VERSION ""

NS_ :

BS_:

BU_:

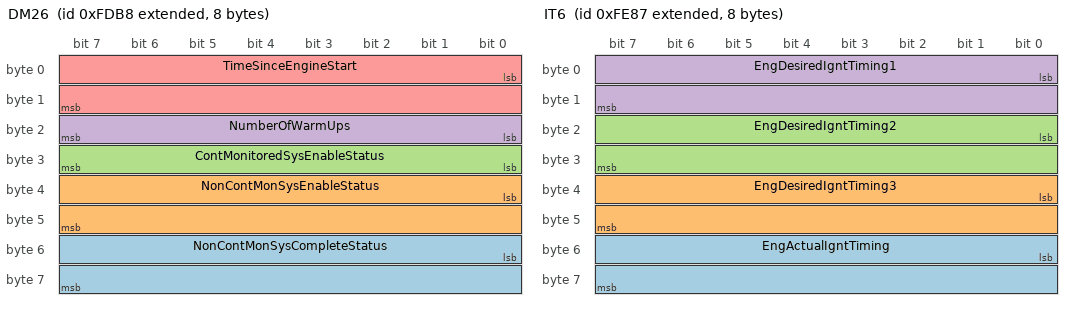
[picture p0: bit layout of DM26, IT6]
BO_ 2147548600 DM26: 8 Vector__XXX
 SG_ NonContMonSysCompleteStatus : 48|16@1+ (1,0) [0|65535] "" Vector__XXX
 SG_ NonContMonSysEnableStatus : 32|16@1+ (1,0) [0|65535] "" Vector__XXX
 SG_ ContMonitoredSysEnableStatus : 24|8@1+ (1,0) [0|255] "" Vector__XXX
 SG_ NumberOfWarmUps : 16|8@1+ (1,0) [0|255] "" Vector__XXX
 SG_ TimeSinceEngineStart : 0|16@1+ (1,0) [0|64255] "sec" Vector__XXX

BO_ 2147537920 DM18: 8 Vector__XXX
 SG_ SecurityEntityType : 16|4@1- (1,0) [0|15] "" Vector__XXX
 SG_ SecurityEntityLength : 0|12@1+ (1,0) [0|1785] "" Vector__XXX

BO_ 2147548855 LF: 10 Vector__XXX
 SG_ TotalEngCruiseTime : 48|32@1+ (0.05,0) [0|210554060.75] "hr" Vector__XXX
 SG_ TotalDriveAverageLoadFactor : 40|8@1+ (0.4,0) [0|100] "%" Vector__XXX
 SG_ TripDriveAverageLoadFactor : 32|8@1+ (0.4,0) [0|100] "%" Vector__XXX
 SG_ TripAverageEngSpeed : 16|16@1+ (0.125,0) [0|8031.875] "rpm" Vector__XXX
 SG_ TripMaxEngSpeed : 0|16@1+ (0.125,0) [0|8031.875] "rpm" Vector__XXX

BO_ 2147548736 LD: 8 Vector__XXX
 SG_ ImplementRearWorkLight : 62|2@1+ (1,0) [0|3] "" Vector__XXX
 SG_ ImplementLeftForwardWorkLight : 60|2@1+ (1,0) [0|3] "" Vector__XXX
 SG_ ImplementRightForwardWorkLight : 58|2@1+ (1,0) [0|3] "" Vector__XXX
 SG_ ImplementLeftFacingWorkLight : 54|2@1+ (1,0) [0|3] "" Vector__XXX
 SG_ ImplementRightFacingWorkLight : 52|2@1+ (1,0) [0|3] "" Vector__XXX
 SG_ ImplementOEMOption1Light : 50|2@1+ (1,0) [0|3] "" Vector__XXX
 SG_ ImplementOEMOption2Light : 48|2@1+ (1,0) [0|3] "" Vector__XXX
 SG_ TrctrFrontHighMountedWorkLights : 46|2@1+ (1,0) [0|3] "" Vector__XXX
 SG_ TrctorFrontLowMountedWorkLights : 44|2@1+ (1,0) [0|3] "" Vector__XXX
 SG_ TrctorSideHighMountedWorkLights : 42|2@1+ (1,0) [0|3] "" Vector__XXX
 SG_ TractorSideLowMountedWorkLights : 40|2@1+ (1,0) [0|3] "" Vector__XXX
 SG_ TrctorRearHighMountedWorkLights : 38|2@1+ (1,0) [0|3] "" Vector__XXX
 SG_ TractorRearLowMountedWorkLights : 36|2@1+ (1,0) [0|3] "" Vector__XXX
 SG_ TrctrUndersideMountedWorkLights : 34|2@1+ (1,0) [0|3] "" Vector__XXX
 SG_ RearFogLights : 32|2@1+ (1,0) [0|3] "" Vector__XXX
 SG_ TractorMarkerLight : 30|2@1+ (1,0) [0|3] "" Vector__XXX
 SG_ ImplementMarkerLight : 28|2@1+ (1,0) [0|3] "" Vector__XXX
 SG_ TractorClearanceLight : 26|2@1+ (1,0) [0|3] "" Vector__XXX
 SG_ ImplementClearanceLight : 24|2@1+ (1,0) [0|3] "" Vector__XXX
 SG_ LeftStopLight : 22|2@1+ (1,0) [0|3] "" Vector__XXX
 SG_ RightStopLight : 20|2@1+ (1,0) [0|3] "" Vector__XXX
 SG_ CenterStopLight : 18|2@1+ (1,0) [0|3] "" Vector__XXX
 SG_ BackUpLightAndAlarmHorn : 16|2@1+ (1,0) [0|3] "" Vector__XXX
 SG_ LeftTurnSignalLights : 14|2@1+ (1,0) [0|3] "" Vector__XXX
 SG_ RightTurnSignalLights : 12|2@1+ (1,0) [0|3] "" Vector__XXX
 SG_ RotatingBeaconLight : 10|2@1+ (1,0) [0|3] "" Vector__XXX
 SG_ TractorFrontFogLights : 8|2@1+ (1,0) [0|3] "" Vector__XXX
 SG_ HighBeamHeadLightData : 6|2@1+ (1,0) [0|3] "" Vector__XXX
 SG_ LowBeamHeadLightData : 4|2@1+ (1,0) [0|3] "" Vector__XXX
 SG_ AltBeamHeadLightData : 2|2@1+ (1,0) [0|3] "" Vector__XXX
 SG_ RunningLight : 0|2@1+ (1,0) [0|3] "" Vector__XXX

BO_ 2147548737 LC: 8 Vector__XXX
 SG_ ImplementRearWorkLightCmd : 62|2@1+ (1,0) [0|3] "" Vector__XXX
 SG_ ImplmentLeftForwardWorkLightCmd : 60|2@1+ (1,0) [0|3] "" Vector__XXX
 SG_ ImplmntRightForwardWorkLightCmd : 58|2@1+ (1,0) [0|3] "" Vector__XXX
 SG_ LightingDataRqCmd : 56|2@1+ (1,0) [0|3] "" Vector__XXX
 SG_ ImplementLeftFacingWorkLightCmd : 54|2@1+ (1,0) [0|3] "" Vector__XXX
 SG_ ImplmentRightFacingWorkLightCmd : 52|2@1+ (1,0) [0|3] "" Vector__XXX
 SG_ ImplementOEMOption1LightCmd : 50|2@1+ (1,0) [0|3] "" Vector__XXX
 SG_ ImplementOEMOption2LightCmd : 48|2@1+ (1,0) [0|3] "" Vector__XXX
 SG_ TrctrFrntHghMuntedWorkLightsCmd : 46|2@1+ (1,0) [0|3] "" Vector__XXX
 SG_ TrctrFrntLwMountedWorkLightsCmd : 44|2@1+ (1,0) [0|3] "" Vector__XXX
 SG_ TrctrSdHighMountedWorkLightsCmd : 42|2@1+ (1,0) [0|3] "" Vector__XXX
 SG_ TrctrSdeLowMountedWorkLightsCmd : 40|2@1+ (1,0) [0|3] "" Vector__XXX
 SG_ TrctrRrHighMountedWorkLightsCmd : 38|2@1+ (1,0) [0|3] "" Vector__XXX
 SG_ TrctrRarLowMountedWorkLightsCmd : 36|2@1+ (1,0) [0|3] "" Vector__XXX
 SG_ TrctrUndrsdMountedWorkLightsCmd : 34|2@1+ (1,0) [0|3] "" Vector__XXX
 SG_ RearFogLightCmd : 32|2@1+ (1,0) [0|3] "" Vector__XXX
 SG_ TractorMarkerLightCmd : 30|2@1+ (1,0) [0|3] "" Vector__XXX
 SG_ ImplementMarkerLightCmd : 28|2@1+ (1,0) [0|3] "" Vector__XXX
 SG_ TractorClearanceLightCmd : 26|2@1+ (1,0) [0|3] "" Vector__XXX
 SG_ ImplementClearanceLightCmd : 24|2@1+ (1,0) [0|3] "" Vector__XXX
 SG_ LeftStopLightCmd : 22|2@1+ (1,0) [0|3] "" Vector__XXX
 SG_ RightStopLightCmd : 20|2@1+ (1,0) [0|3] "" Vector__XXX
 SG_ CenterStopLightCmd : 18|2@1+ (1,0) [0|3] "" Vector__XXX
 SG_ BackUpLightAndAlarmHornCmd : 16|2@1+ (1,0) [0|3] "" Vector__XXX
 SG_ LeftTurnSignalLightsCmd : 14|2@1+ (1,0) [0|3] "" Vector__XXX
 SG_ RightTurnSignalLightsCmd : 12|2@1+ (1,0) [0|3] "" Vector__XXX
 SG_ RotatingBeaconLightCmd : 10|2@1+ (1,0) [0|3] "" Vector__XXX
 SG_ TractorFrontFogLightsCmd : 8|2@1+ (1,0) [0|3] "" Vector__XXX
 SG_ HighBeamHeadLightCmd : 6|2@1+ (1,0) [0|3] "" Vector__XXX
 SG_ LowBeamHeadLightCmd : 4|2@1+ (1,0) [0|3] "" Vector__XXX
 SG_ AltBeamHeadLightCmd : 2|2@1+ (1,0) [0|3] "" Vector__XXX
 SG_ RunningLightCmd : 0|2@1+ (1,0) [0|3] "" Vector__XXX

BO_ 2147548786 LBC: 8 Vector__XXX
 SG_ BladeCtrlMode : 16|8@1+ (1,0) [0|255] "" Vector__XXX
 SG_ BladeDurationAndDirection : 0|16@1+ (0.1,-3275.2) [-3275.2|3148.7] "sec" Vector__XXX

BO_ 2147548807 IT6: 8 Vector__XXX
 SG_ EngActualIgntTiming : 48|16@1+ (1,-200) [-200|301.99] "deg" Vector__XXX
 SG_ EngDesiredIgntTiming3 : 32|16@1+ (1,-200) [-200|301.99] "deg" Vector__XXX
 SG_ EngDesiredIgntTiming2 : 16|16@1+ (1,-200) [-200|301.99] "deg" Vector__XXX
 SG_ EngDesiredIgntTiming1 : 0|16@1+ (1,-200) [-200|301.99] "deg" Vector__XXX

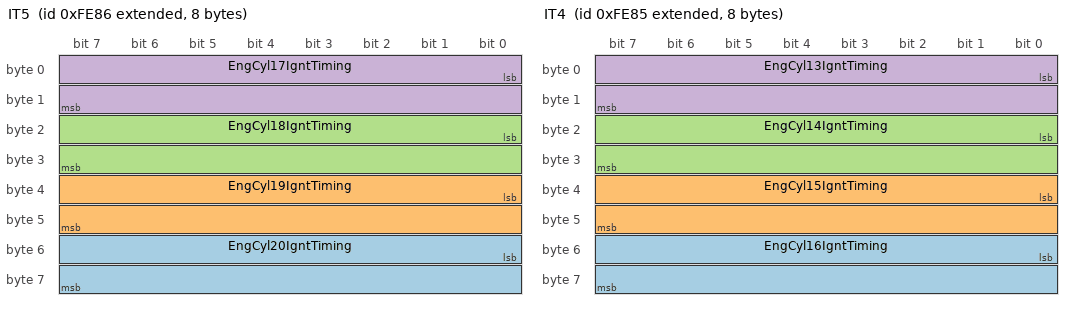
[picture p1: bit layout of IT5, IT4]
BO_ 2147548806 IT5: 8 Vector__XXX
 SG_ EngCyl20IgntTiming : 48|16@1+ (1,-200) [-200|301.99] "deg" Vector__XXX
 SG_ EngCyl19IgntTiming : 32|16@1+ (1,-200) [-200|301.99] "deg" Vector__XXX
 SG_ EngCyl18IgntTiming : 16|16@1+ (1,-200) [-200|301.99] "deg" Vector__XXX
 SG_ EngCyl17IgntTiming : 0|16@1+ (1,-200) [-200|301.99] "deg" Vector__XXX

BO_ 2147548805 IT4: 8 Vector__XXX
 SG_ EngCyl16IgntTiming : 48|16@1+ (1,-200) [-200|301.99] "deg" Vector__XXX
 SG_ EngCyl15IgntTiming : 32|16@1+ (1,-200) [-200|301.99] "deg" Vector__XXX
 SG_ EngCyl14IgntTiming : 16|16@1+ (1,-200) [-200|301.99] "deg" Vector__XXX
 SG_ EngCyl13IgntTiming : 0|16@1+ (1,-200) [-200|301.99] "deg" Vector__XXX

BO_ 2147548804 IT3: 8 Vector__XXX
 SG_ EngCyl12IgntTiming : 48|16@1+ (1,-200) [-200|301.99] "deg" Vector__XXX
 SG_ EngCyl11IgntTiming : 32|16@1+ (1,-200) [-200|301.99] "deg" Vector__XXX
 SG_ EngCyl10IgntTiming : 16|16@1+ (1,-200) [-200|301.99] "deg" Vector__XXX
 SG_ EngCyl9IgntTiming : 0|16@1+ (1,-200) [-200|301.99] "deg" Vector__XXX

BO_ 2147548803 IT2: 8 Vector__XXX
 SG_ EngCyl8IgntTiming : 48|16@1+ (1,-200) [-200|301.99] "deg" Vector__XXX
 SG_ EngCyl7IgntTiming : 32|16@1+ (1,-200) [-200|301.99] "deg" Vector__XXX
 SG_ EngCyl6IgntTiming : 16|16@1+ (1,-200) [-200|301.99] "deg" Vector__XXX
 SG_ EngCyl5IgntTiming : 0|16@1+ (1,-200) [-200|301.99] "deg" Vector__XXX

BO_ 2147548802 IT1: 8 Vector__XXX
 SG_ EngCyl4IgntTiming : 48|16@1+ (1,-200) [-200|301.99] "deg" Vector__XXX
 SG_ EngCyl3IgntTiming : 32|16@1+ (1,-200) [-200|301.99] "deg" Vector__XXX
 SG_ EngCyl2IgntTiming : 16|16@1+ (1,-200) [-200|301.99] "deg" Vector__XXX
 SG_ EngCyl1IgntTiming : 0|16@1+ (1,-200) [-200|301.99] "deg" Vector__XXX

BO_ 2147548810 ISO3: 8 Vector__XXX
 SG_ EngCyl20IgntTransSecondOutput : 24|8@1+ (1,-125) [-125|125] "%" Vector__XXX
 SG_ EngCyl19IgntTransSecondOutput : 16|8@1+ (1,-125) [-125|125] "%" Vector__XXX
 SG_ EngCyl18IgntTransSecondOutput : 8|8@1+ (1,-125) [-125|125] "%" Vector__XXX
 SG_ EngCyl17IgntTransSecondOutput : 0|8@1+ (1,-125) [-125|125] "%" Vector__XXX

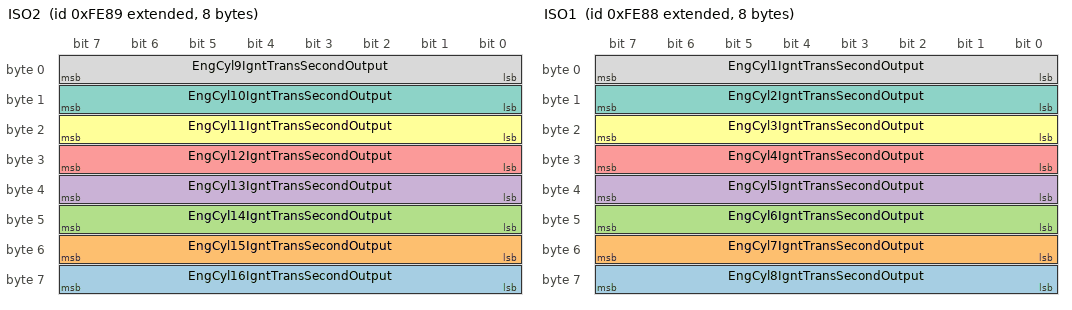
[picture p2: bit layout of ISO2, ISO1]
BO_ 2147548809 ISO2: 8 Vector__XXX
 SG_ EngCyl16IgntTransSecondOutput : 56|8@1+ (1,-125) [-125|125] "%" Vector__XXX
 SG_ EngCyl15IgntTransSecondOutput : 48|8@1+ (1,-125) [-125|125] "%" Vector__XXX
 SG_ EngCyl14IgntTransSecondOutput : 40|8@1+ (1,-125) [-125|125] "%" Vector__XXX
 SG_ EngCyl13IgntTransSecondOutput : 32|8@1+ (1,-125) [-125|125] "%" Vector__XXX
 SG_ EngCyl12IgntTransSecondOutput : 24|8@1+ (1,-125) [-125|125] "%" Vector__XXX
 SG_ EngCyl11IgntTransSecondOutput : 16|8@1+ (1,-125) [-125|125] "%" Vector__XXX
 SG_ EngCyl10IgntTransSecondOutput : 8|8@1+ (1,-125) [-125|125] "%" Vector__XXX
 SG_ EngCyl9IgntTransSecondOutput : 0|8@1+ (1,-125) [-125|125] "%" Vector__XXX

BO_ 2147548808 ISO1: 8 Vector__XXX
 SG_ EngCyl8IgntTransSecondOutput : 56|8@1+ (1,-125) [-125|125] "%" Vector__XXX
 SG_ EngCyl7IgntTransSecondOutput : 48|8@1+ (1,-125) [-125|125] "%" Vector__XXX
 SG_ EngCyl6IgntTransSecondOutput : 40|8@1+ (1,-125) [-125|125] "%" Vector__XXX
 SG_ EngCyl5IgntTransSecondOutput : 32|8@1+ (1,-125) [-125|125] "%" Vector__XXX
 SG_ EngCyl4IgntTransSecondOutput : 24|8@1+ (1,-125) [-125|125] "%" Vector__XXX
 SG_ EngCyl3IgntTransSecondOutput : 16|8@1+ (1,-125) [-125|125] "%" Vector__XXX
 SG_ EngCyl2IgntTransSecondOutput : 8|8@1+ (1,-125) [-125|125] "%" Vector__XXX
 SG_ EngCyl1IgntTransSecondOutput : 0|8@1+ (1,-125) [-125|125] "%" Vector__XXX

BO_ 2147548616 ISCS: 8 Vector__XXX
 SG_ EngOprtrPrmryIntrmdtSpdSlctStte : 0|4@1+ (1,0) [0|15] "" Vector__XXX

BO_ 2147548618 ISC: 8 Vector__XXX
 SG_ EngOprtrPrmryIntrmdtSpeedSelect : 0|4@1+ (1,0) [0|15] "" Vector__XXX

BO_ 2147548892 IO: 8 Vector__XXX
 SG_ EngTotalIdleHours : 32|32@1+ (0.05,0) [0|210554060.75] "hr" Vector__XXX
 SG_ EngTotalIdleFuelUsed : 0|32@1+ (0.5,0) [0|2105540607.5] "L" Vector__XXX

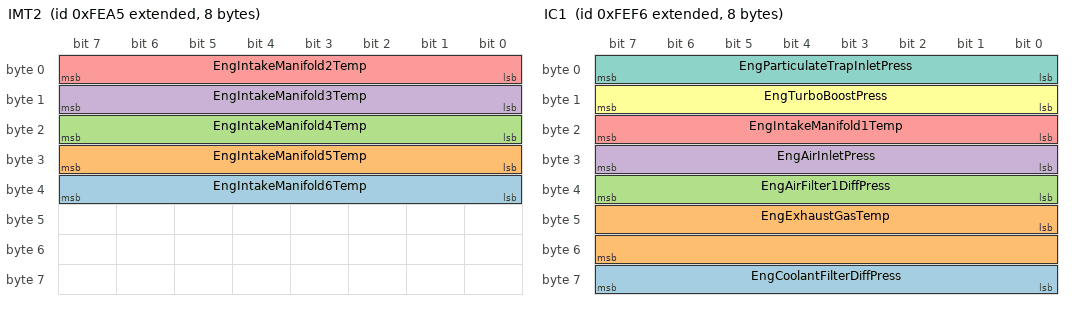
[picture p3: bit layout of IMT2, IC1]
BO_ 2147548837 IMT2: 8 Vector__XXX
 SG_ EngIntakeManifold6Temp : 32|8@1+ (1,-40) [-40|210] "deg" Vector__XXX
 SG_ EngIntakeManifold5Temp : 24|8@1+ (1,-40) [-40|210] "deg" Vector__XXX
 SG_ EngIntakeManifold4Temp : 16|8@1+ (1,-40) [-40|210] "deg" Vector__XXX
 SG_ EngIntakeManifold3Temp : 8|8@1+ (1,-40) [-40|210] "deg" Vector__XXX
 SG_ EngIntakeManifold2Temp : 0|8@1+ (1,-40) [-40|210] "deg" Vector__XXX

BO_ 2147548838 IMT1: 8 Vector__XXX
 SG_ EngTurbo4BoostPress : 48|16@1+ (0.125,0) [0|0] "+8031.875" Vector__XXX
 SG_ EngTurbo3BoostPress : 32|16@1+ (0.125,0) [0|0] "+8031.875" Vector__XXX
 SG_ EngTurbo2BoostPress : 16|16@1+ (0.125,0) [0|0] "+8031.875" Vector__XXX
 SG_ EngTurbo1BoostPress : 0|16@1+ (0.125,0) [0|0] "+8031.875" Vector__XXX

BO_ 2147548624 IC2: 8 Vector__XXX
 SG_ EngAirFilter4DiffPress : 16|8@1+ (0.05,0) [0|12.5] "kPa" Vector__XXX
 SG_ EngAirFilter3DiffPress : 8|8@1+ (0.05,0) [0|12.5] "kPa" Vector__XXX
 SG_ EngAirFilter2DiffPress : 0|8@1+ (0.05,0) [0|12.5] "kPa" Vector__XXX

BO_ 2147548918 IC1: 8 Vector__XXX
 SG_ EngCoolantFilterDiffPress : 56|8@1+ (0.5,0) [0|125] "kPa" Vector__XXX
 SG_ EngExhaustGasTemp : 40|16@1+ (0.03125,-273) [-273|1735] "deg" Vector__XXX
 SG_ EngAirFilter1DiffPress : 32|8@1+ (0.05,0) [0|12.5] "kPa" Vector__XXX
 SG_ EngAirInletPress : 24|8@1+ (2,0) [0|500] "kPa" Vector__XXX
 SG_ EngIntakeManifold1Temp : 16|8@1+ (1,-40) [-40|210] "deg" Vector__XXX
 SG_ EngTurboBoostPress : 8|8@1+ (2,0) [0|500] "kPa" Vector__XXX
 SG_ EngParticulateTrapInletPress : 0|8@1+ (0.5,0) [0|125] "kPa" Vector__XXX

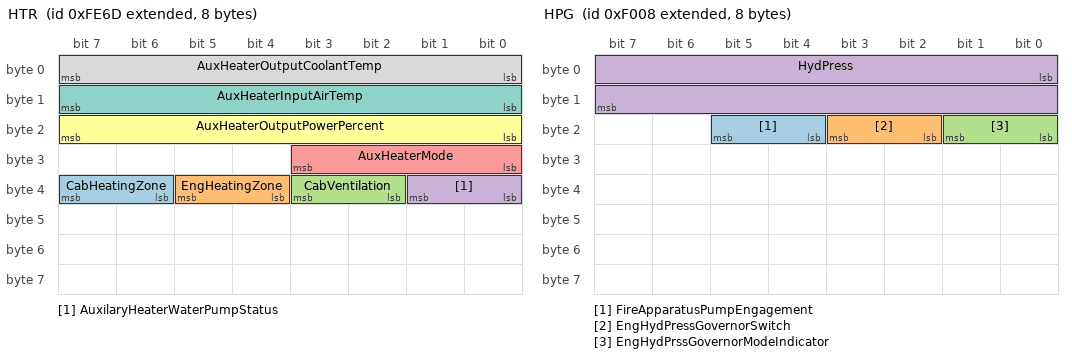
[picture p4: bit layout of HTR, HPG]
BO_ 2147548781 HTR: 8 Vector__XXX
 SG_ CabHeatingZone : 38|2@1+ (1,0) [0|3] "" Vector__XXX
 SG_ EngHeatingZone : 36|2@1+ (1,0) [0|3] "" Vector__XXX
 SG_ CabVentilation : 34|2@1+ (1,0) [0|3] "" Vector__XXX
 SG_ AuxilaryHeaterWaterPumpStatus : 32|2@1+ (1,0) [0|3] "" Vector__XXX
 SG_ AuxHeaterMode : 24|4@1+ (1,0) [0|15] "" Vector__XXX
 SG_ AuxHeaterOutputPowerPercent : 16|8@1+ (0.4,0) [0|100] "%" Vector__XXX
 SG_ AuxHeaterInputAirTemp : 8|8@1+ (1,-40) [-40|210] "deg" Vector__XXX
 SG_ AuxHeaterOutputCoolantTemp : 0|8@1+ (1,-40) [-40|210] "deg" Vector__XXX

BO_ 2147548782 HRW: 8 Vector__XXX
 SG_ RearAxleRightWheelSpeed : 48|16@1+ (1,0) [0|250.996] "km/h" Vector__XXX
 SG_ RearAxleLeftWheelSpeed : 32|16@1+ (1,0) [0|250.996] "km/h" Vector__XXX
 SG_ FrontAxleRightWheelSpeed : 16|16@1+ (1,0) [0|250.996] "km/h" Vector__XXX
 SG_ FrontAxleLeftWheelSpeed : 0|16@1+ (1,0) [0|250.996] "km/h" Vector__XXX

BO_ 2147545096 HPG: 8 Vector__XXX
 SG_ FireApparatusPumpEngagement : 20|2@1+ (1,0) [0|3] "" Vector__XXX
 SG_ EngHydPressGovernorSwitch : 18|2@1+ (1,0) [0|3] "" Vector__XXX
 SG_ EngHydPrssGovernorModeIndicator : 16|2@1+ (1,0) [0|3] "" Vector__XXX
 SG_ HydPress : 0|16@1+ (2,0) [0|128510] "kPa" Vector__XXX

BO_ 2147548901 HOURS: 8 Vector__XXX
 SG_ EngTotalRevolutions : 32|32@1+ (1000,0) [0|4.211081215E+012] "r" Vector__XXX
 SG_ EngTotalHoursOfOperation : 0|32@1+ (0.05,0) [0|210554060.75] "hr" Vector__XXX

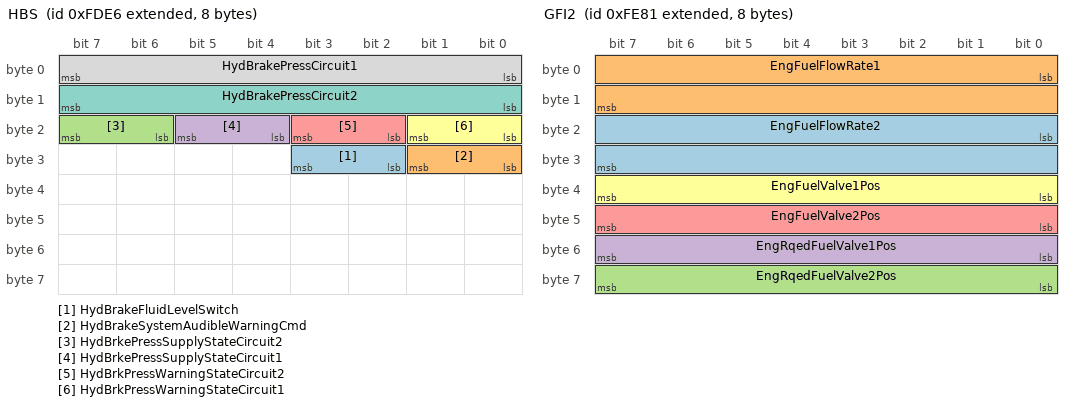
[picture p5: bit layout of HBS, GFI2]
BO_ 2147548646 HBS: 8 Vector__XXX
 SG_ HydBrakeFluidLevelSwitch : 26|2@1+ (1,0) [0|3] "" Vector__XXX
 SG_ HydBrakeSystemAudibleWarningCmd : 24|2@1+ (1,0) [0|3] "" Vector__XXX
 SG_ HydBrkePressSupplyStateCircuit2 : 22|2@1+ (1,0) [0|3] "" Vector__XXX
 SG_ HydBrkePressSupplyStateCircuit1 : 20|2@1+ (1,0) [0|3] "" Vector__XXX
 SG_ HydBrkPressWarningStateCircuit2 : 18|2@1+ (1,0) [0|3] "" Vector__XXX
 SG_ HydBrkPressWarningStateCircuit1 : 16|2@1+ (1,0) [0|3] "" Vector__XXX
 SG_ HydBrakePressCircuit2 : 8|8@1+ (100,0) [0|25] "MPa" Vector__XXX
 SG_ HydBrakePressCircuit1 : 0|8@1+ (100,0) [0|25] "MPa" Vector__XXX

BO_ 2147548856 GTFI: 22 Vector__XXX
 SG_ TripDriveFuelEconomy : 160|16@1+ (1,0) [0|125.5] "km/kg" Vector__XXX
 SG_ TripCruiseFuelUsed : 128|32@1+ (0.5,0) [0|2105540607.5] "kg" Vector__XXX
 SG_ TripVehicleIdleFuelUsed : 96|32@1+ (0.5,0) [0|2105540607.5] "kg" Vector__XXX
 SG_ TripPTONonmovingFuelUsed : 64|32@1+ (0.5,0) [0|2105540607.5] "kg" Vector__XXX
 SG_ TripPTOMovingFuelUsed : 32|32@1+ (0.5,0) [0|2105540607.5] "kg" Vector__XXX
 SG_ TripDriveFuelUsed : 0|32@1+ (0.5,0) [0|2105540607.5] "kg" Vector__XXX

BO_ 2147548811 GFP: 8 Vector__XXX
 SG_ EngAirToFuelDiffPress : 32|16@1+ (0.1,0) [0|6425.5] "kPa" Vector__XXX
 SG_ EngFuelValveDiffPress : 16|16@1+ (0.1,0) [0|6425.5] "kPa" Vector__XXX
 SG_ EngFuelValveInletAbsPress : 0|16@1+ (0.1,0) [0|6425.5] "kPa" Vector__XXX

BO_ 2147548801 GFI2: 8 Vector__XXX
 SG_ EngFuelFlowRate2 : 16|16@1+ (0.1,0) [0|6425.5] "m^3/h" Vector__XXX
 SG_ EngFuelFlowRate1 : 0|16@1+ (0.1,0) [0|6425.5] "m^3/h" Vector__XXX
 SG_ EngRqedFuelValve2Pos : 56|8@1+ (0.4,0) [0|100] "%" Vector__XXX
 SG_ EngRqedFuelValve1Pos : 48|8@1+ (0.4,0) [0|100] "%" Vector__XXX
 SG_ EngFuelValve2Pos : 40|8@1+ (0.4,0) [0|100] "%" Vector__XXX
 SG_ EngFuelValve1Pos : 32|8@1+ (0.4,0) [0|100] "%" Vector__XXX

BO_ 2147548850 GFI1: 8 Vector__XXX
 SG_ EngFuelSpecificGravity : 48|16@1+ (0.0001,0) [0|6.4255] "" Vector__XXX
 SG_ TripAverageFuelRate : 32|16@1+ (0.05,0) [0|3212.75] "kg/h" Vector__XXX
 SG_ TotalEngPTOFuelUsed : 0|32@1+ (0.5,0) [0|2105540607.5] "kg" Vector__XXX

BO_ 2147548757 GFD: 8 Vector__XXX
 SG_ SpecificHeatRatio : 0|16@1+ (0.001,0) [0|64.255] "" Vector__XXX

BO_ 2147548847 GFC: 8 Vector__XXX
 SG_ TotalFuelUsed : 32|32@1+ (0.5,0) [0|2105540607.5] "kg" Vector__XXX
 SG_ TripFuel : 0|32@1+ (0.5,0) [0|2105540607.5] "kg" Vector__XXX

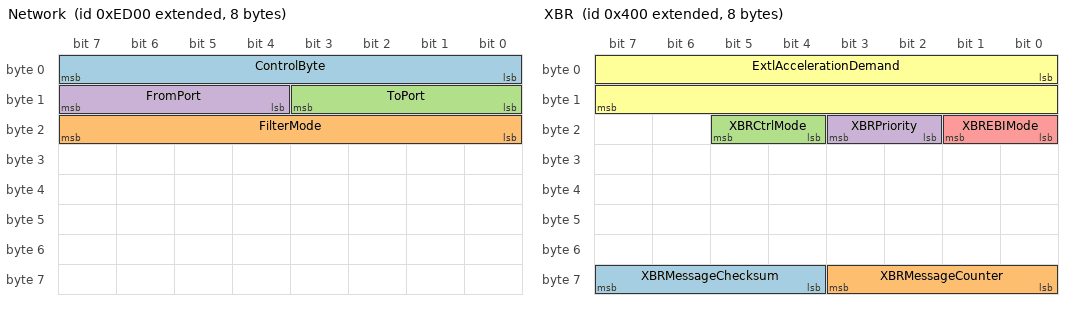
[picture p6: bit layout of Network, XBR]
BO_ 2147544320 Network: 8 Vector__XXX
 SG_ ControlByte : 0|8@1+ (1,0) [0|255] "" Vector__XXX
 SG_ FilterMode : 16|8@1+ (1,0) [0|255] "" Vector__XXX
 SG_ ToPort : 8|4@1+ (1,0) [0|15] "" Vector__XXX
 SG_ FromPort : 12|4@1+ (1,0) [0|15] "" Vector__XXX

BO_ 2147484672 XBR: 8 Vector__XXX
 SG_ XBRMessageChecksum : 60|4@1+ (1,0) [0|15] "" Vector__XXX
 SG_ XBRMessageCounter : 56|4@1+ (1,0) [0|15] "" Vector__XXX
 SG_ XBRCtrlMode : 20|2@1+ (1,0) [0|3] "" Vector__XXX
 SG_ XBRPriority : 18|2@1+ (1,0) [0|3] "" Vector__XXX
 SG_ XBREBIMode : 16|2@1+ (1,0) [0|3] "" Vector__XXX
 SG_ ExtlAccelerationDemand : 0|16@1+ (1,-14.313) [-14.313|0] "+15.687" Vector__XXX

BO_ 2147548927 WFI: 8 Vector__XXX
 SG_ WaterInFuelIndicator : 0|2@1+ (1,0) [0|3] "" Vector__XXX

BO_ 2147548906 VW: 8 Vector__XXX
 SG_ CargoWeight : 40|16@1+ (2,0) [0|128510] "kg" Vector__XXX
 SG_ TrailerWeight : 24|16@1+ (2,0) [0|128510] "kg" Vector__XXX
 SG_ AxleWeight : 8|16@1+ (0.5,0) [0|32127.5] "kg" Vector__XXX
 SG_ AxleLocation : 0|8@1+ (1,0) [0|255] "" Vector__XXX

BO_ 2147548754 VP3: 8 Vector__XXX
 SG_ NetBatteryCurrentHiRes : 16|16@1+ (0.05,-1600) [-1600|1676.75] "A" Vector__XXX
 SG_ AltCurrentHiRes : 0|16@1+ (0.05,-1600) [-1600|1676.75] "A" Vector__XXX

BO_ 2147548813 VP2: 8 Vector__XXX
 SG_ Battery2Potential : 0|16@1+ (0.05,0) [0|3212.75] "V" Vector__XXX

BO_ 2147548915 VP: 8 Vector__XXX
 SG_ Longitude : 32|32@1+ (10,-210) [-210|211.1008122] "deg" Vector__XXX
 SG_ Latitude : 0|32@1+ (10,-210) [-210|211.1008122] "deg" Vector__XXX

BO_ 2147548908 VI: 8 Vector__XXX

BO_ 2147548903 VH: 8 Vector__XXX
 SG_ TotalPowerTakeoffHours : 32|32@1+ (0.05,0) [0|210554060.75] "hr" Vector__XXX
 SG_ TotalVehicleHours : 0|32@1+ (0.05,0) [0|210554060.75] "hr" Vector__XXX

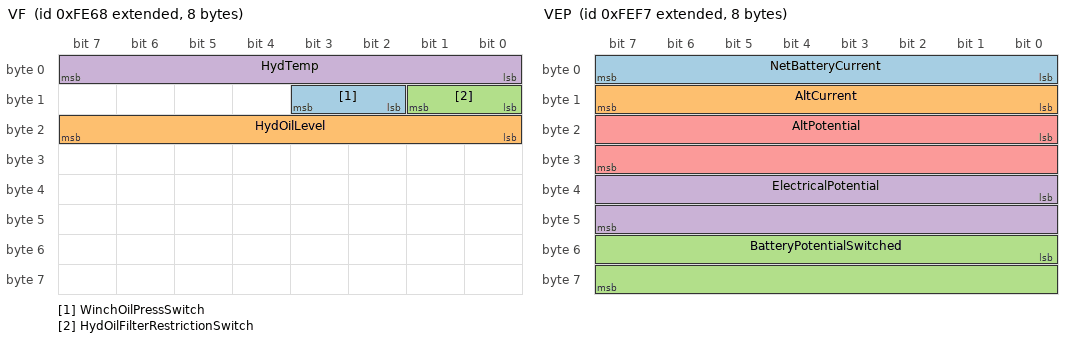
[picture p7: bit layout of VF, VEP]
BO_ 2147548776 VF: 8 Vector__XXX
 SG_ WinchOilPressSwitch : 10|2@1+ (1,0) [0|3] "" Vector__XXX
 SG_ HydOilLevel : 16|8@1+ (0.4,0) [0|100] "%" Vector__XXX
 SG_ HydOilFilterRestrictionSwitch : 8|2@1+ (1,0) [0|3] "" Vector__XXX
 SG_ HydTemp : 0|8@1+ (1,-40) [-40|210] "deg" Vector__XXX

BO_ 2147548919 VEP: 8 Vector__XXX
 SG_ NetBatteryCurrent : 0|8@1+ (1,-125) [-125|125] "A" Vector__XXX
 SG_ AltCurrent : 8|8@1+ (1,0) [0|250] "A" Vector__XXX
 SG_ BatteryPotentialSwitched : 48|16@1+ (0.05,0) [0|3212.75] "V" Vector__XXX
 SG_ ElectricalPotential : 32|16@1+ (0.05,0) [0|3212.75] "V" Vector__XXX
 SG_ AltPotential : 16|16@1+ (0.05,0) [0|3212.75] "V" Vector__XXX

BO_ 2147548904 VDS: 8 Vector__XXX
 SG_ Altitude : 48|16@1+ (0.125,-2500) [-2500|5531.875] "m" Vector__XXX
 SG_ Pitch : 32|16@1+ (1,-200) [-200|301.99] "deg" Vector__XXX
 SG_ NavigationBasedVehicleSpeed : 16|16@1+ (1,0) [0|250.996] "km/h" Vector__XXX
 SG_ CompassBearing : 0|16@1+ (1,0) [0|501.99] "deg" Vector__XXX

BO_ 2147548865 VDHR: 8 Vector__XXX
 SG_ HighResolutionTripDistance : 32|32@1+ (5,0) [0|21055406] "km" Vector__XXX
 SG_ HghRslutionTotalVehicleDistance : 0|32@1+ (5,0) [0|21055406] "km" Vector__XXX

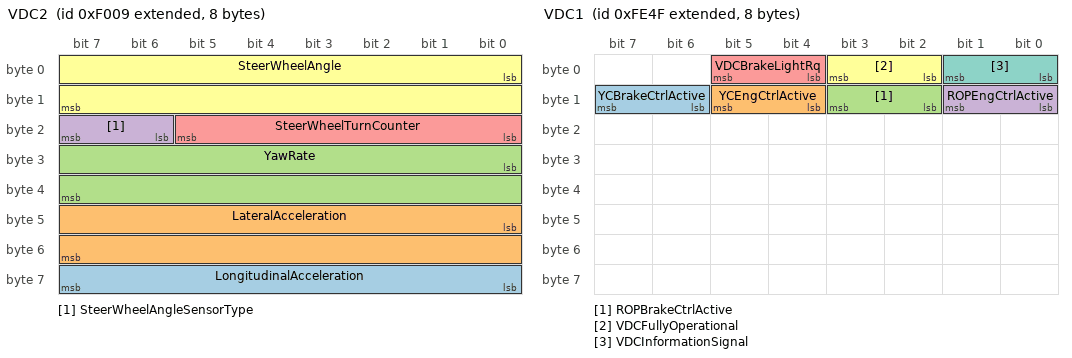
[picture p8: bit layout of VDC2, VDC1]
BO_ 2147545097 VDC2: 8 Vector__XXX
 SG_ LongitudinalAcceleration : 56|8@1+ (0.1,-11.5) [-11.5|0] "+12.5" Vector__XXX
 SG_ LateralAcceleration : 40|16@1+ (1,-14.313) [-14.313|0] "+15.687" Vector__XXX
 SG_ YawRate : 24|16@1+ (1,-2.08) [-2.08|0] "+3.92" Vector__XXX
 SG_ SteerWheelAngleSensorType : 22|2@1+ (1,0) [0|3] "" Vector__XXX
 SG_ SteerWheelTurnCounter : 16|6@1+ (1,-32) [-32|29] "turns" Vector__XXX
 SG_ SteerWheelAngle : 0|16@1+ (1,-30.626) [-30.626|0] "+31.374" Vector__XXX

BO_ 2147548751 VDC1: 8 Vector__XXX
 SG_ YCBrakeCtrlActive : 14|2@1+ (1,0) [0|3] "" Vector__XXX
 SG_ YCEngCtrlActive : 12|2@1+ (1,0) [0|3] "" Vector__XXX
 SG_ ROPBrakeCtrlActive : 10|2@1+ (1,0) [0|3] "" Vector__XXX
 SG_ ROPEngCtrlActive : 8|2@1+ (1,0) [0|3] "" Vector__XXX
 SG_ VDCBrakeLightRq : 4|2@1+ (1,0) [0|3] "" Vector__XXX
 SG_ VDCFullyOperational : 2|2@1+ (1,0) [0|3] "" Vector__XXX
 SG_ VDCInformationSignal : 0|2@1+ (1,0) [0|3] "" Vector__XXX

BO_ 2147548896 VD: 8 Vector__XXX
 SG_ TotalVehicleDistance : 32|32@1+ (0.125,0) [0|526385151.9] "km" Vector__XXX
 SG_ TripDistance : 0|32@1+ (0.125,0) [0|526385151.9] "km" Vector__XXX

BO_ 2147548854 TVI: 8 Vector__XXX
 SG_ TripCruiseDistance : 16|32@1+ (0.125,0) [0|526385151.9] "km" Vector__XXX
 SG_ TripMaxVehicleSpeed : 0|16@1+ (1,0) [0|250.996] "km/h" Vector__XXX

BO_ 2147548848 TTI2: 20 Vector__XXX
 SG_ TripAirCompressorOnTime : 128|32@1+ (0.05,0) [0|210554060.75] "hr" Vector__XXX
 SG_ TripIdleTime : 96|32@1+ (0.05,0) [0|210554060.75] "hr" Vector__XXX
 SG_ TripEngRunningTime : 64|32@1+ (0.05,0) [0|210554060.75] "hr" Vector__XXX
 SG_ TripPTOTime : 32|32@1+ (0.05,0) [0|210554060.75] "hr" Vector__XXX
 SG_ TripCruiseTime : 0|32@1+ (0.05,0) [0|210554060.75] "hr" Vector__XXX

BO_ 2147548852 TTI1: 16 Vector__XXX
 SG_ TripTimeInDerateByEng : 96|32@1+ (0.05,0) [0|210554060.75] "hr" Vector__XXX
 SG_ TripTimeInGearDown : 64|32@1+ (0.05,0) [0|210554060.75] "hr" Vector__XXX
 SG_ TripTimeInTopGear : 32|32@1+ (0.05,0) [0|210554060.75] "hr" Vector__XXX
 SG_ TripTimeInVSL : 0|32@1+ (0.05,0) [0|210554060.75] "hr" Vector__XXX

BO_ 2147548853 TSI: 8 Vector__XXX
 SG_ TripSuddenDecelerations : 48|16@1+ (1,0) [0|64255] "counts" Vector__XXX
 SG_ TrpNmberOfIdleShutdownOverrides : 32|16@1+ (1,0) [0|64255] "counts" Vector__XXX
 SG_ TripNumberOfIdleShutdowns : 16|16@1+ (1,0) [0|64255] "counts" Vector__XXX
 SG_ TripNumberOfHotShutdowns : 0|16@1+ (1,0) [0|64255] "counts" Vector__XXX

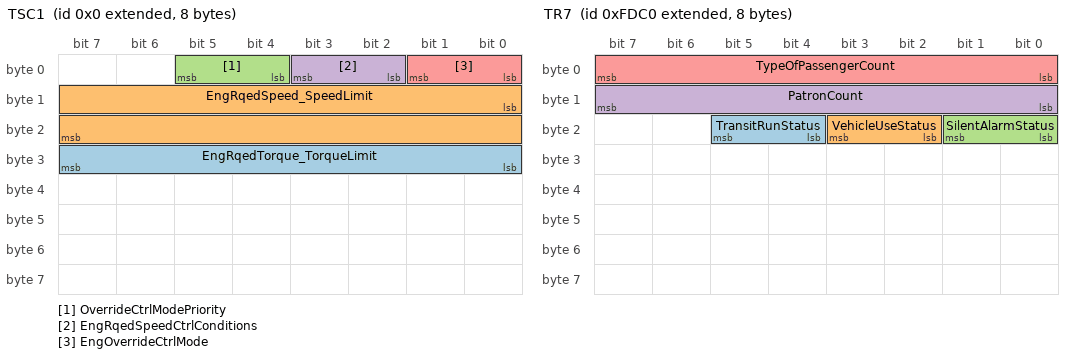
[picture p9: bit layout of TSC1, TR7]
BO_ 2147483648 TSC1: 8 Vector__XXX
 SG_ EngRqedTorque_TorqueLimit : 24|8@1+ (1,-125) [-125|125] "%" Vector__XXX
 SG_ EngRqedSpeed_SpeedLimit : 8|16@1+ (0.125,0) [0|8031.875] "rpm" Vector__XXX
 SG_ OverrideCtrlModePriority : 4|2@1+ (1,0) [0|3] "" Vector__XXX
 SG_ EngRqedSpeedCtrlConditions : 2|2@1+ (1,0) [0|3] "" Vector__XXX
 SG_ EngOverrideCtrlMode : 0|2@1+ (1,0) [0|3] "" Vector__XXX

BO_ 2147548608 TR7: 8 Vector__XXX
 SG_ TransitRunStatus : 20|2@1+ (1,0) [0|3] "" Vector__XXX
 SG_ VehicleUseStatus : 18|2@1+ (1,0) [0|3] "" Vector__XXX
 SG_ SilentAlarmStatus : 16|2@1+ (1,0) [0|3] "" Vector__XXX
 SG_ PatronCount : 8|8@1+ (1,0) [0|250] "" Vector__XXX
 SG_ TypeOfPassengerCount : 0|8@1+ (1,0) [0|255] "" Vector__XXX

BO_ 2147548602 TR6: 8 Vector__XXX
 SG_ FareboxAlarmIdentifier : 8|7@1+ (1,0) [0|127] "" Vector__XXX
 SG_ FareboxEmergencyStatus : 0|2@1+ (1,0) [0|3] "" Vector__XXX

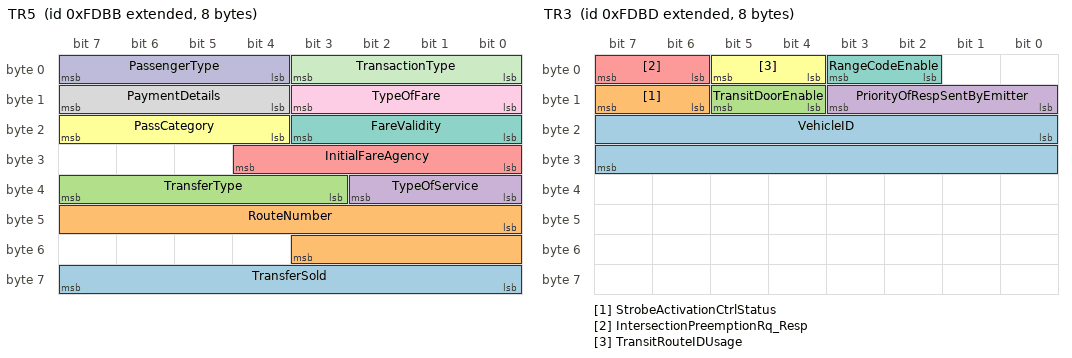
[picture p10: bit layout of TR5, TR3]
BO_ 2147548603 TR5: 8 Vector__XXX
 SG_ TransferSold : 56|8@1+ (1,0) [0|255] "" Vector__XXX
 SG_ RouteNumber : 40|12@1+ (1,0) [0|4095] "" Vector__XXX
 SG_ TransferType : 35|5@1+ (1,0) [0|31] "" Vector__XXX
 SG_ TypeOfService : 32|3@1+ (1,0) [0|7] "" Vector__XXX
 SG_ InitialFareAgency : 24|5@1+ (1,0) [0|31] "" Vector__XXX
 SG_ PassCategory : 20|4@1+ (1,0) [0|15] "" Vector__XXX
 SG_ FareValidity : 16|4@1+ (1,0) [0|15] "" Vector__XXX
 SG_ PaymentDetails : 12|4@1+ (1,0) [0|15] "" Vector__XXX
 SG_ TypeOfFare : 8|4@1+ (1,0) [0|15] "" Vector__XXX
 SG_ PassengerType : 4|4@1+ (1,0) [0|15] "" Vector__XXX
 SG_ TransactionType : 0|4@1+ (1,0) [0|15] "" Vector__XXX

BO_ 2147548604 TR4: 15 Vector__XXX
 SG_ DriversFareboxSecurityCode : 104|16@1+ (1,0) [0|65535] "counts" Vector__XXX
 SG_ AssignedBlock : 88|16@1+ (1,0) [0|65535] "counts" Vector__XXX
 SG_ AssignedRun : 72|16@1+ (1,0) [0|65535] "counts" Vector__XXX
 SG_ AssignedRoute : 56|16@1+ (1,0) [0|65535] "counts" Vector__XXX
 SG_ PatternNumber : 40|16@1+ (1,0) [0|65535] "counts" Vector__XXX
 SG_ TripNumber : 24|16@1+ (1,0) [0|65535] "counts" Vector__XXX
 SG_ FarePresets : 16|8@1+ (1,0) [0|255] "" Vector__XXX
 SG_ TripDirection : 8|4@1+ (1,0) [0|15] "" Vector__XXX
 SG_ TripStatus : 2|3@1+ (1,0) [0|7] "" Vector__XXX
 SG_ FareboxServiceStatus : 0|2@1+ (1,0) [0|3] "" Vector__XXX

BO_ 2147548605 TR3: 8 Vector__XXX
 SG_ VehicleID : 16|16@1+ (1,0) [0|65535] "counts" Vector__XXX
 SG_ StrobeActivationCtrlStatus : 14|2@1+ (1,0) [0|3] "" Vector__XXX
 SG_ TransitDoorEnable : 12|2@1+ (1,0) [0|3] "" Vector__XXX
 SG_ PriorityOfRespSentByEmitter : 8|4@1+ (1,0) [0|15] "" Vector__XXX
 SG_ IntersectionPreemptionRq_Resp : 6|2@1+ (1,0) [0|3] "" Vector__XXX
 SG_ TransitRouteIDUsage : 4|2@1+ (1,0) [0|3] "" Vector__XXX
 SG_ RangeCodeEnable : 2|2@1+ (1,0) [0|3] "" Vector__XXX

BO_ 2147548607 TR2: 8 Vector__XXX
 SG_ NmbrOfBytsInMlpstIdentification : 0|8@1+ (1,0) [0|250] "" Vector__XXX

BO_ 2147548606 TR1: 8 Vector__XXX
 SG_ Agency : 0|8@1+ (1,0) [0|255] "" Vector__XXX
 SG_ NmbrOfBytsInTrnstAssgndBlckIdntt : 24|8@1+ (1,0) [0|250] "" Vector__XXX
 SG_ NmbrOfBytsInTrnstAssgndRnIdntty : 16|8@1+ (1,0) [0|250] "" Vector__XXX
 SG_ NmbrOfBytsInTrnstAssgndRtIdntty : 8|8@1+ (1,0) [0|250] "" Vector__XXX

BO_ 2147528192 TPRS: 8 Vector__XXX
 SG_ ReferenceTirePressSetting : 8|8@1+ (8,0) [0|2000] "kPa" Vector__XXX
 SG_ TireLocation : 0|8@1+ (1,0) [0|255] "" Vector__XXX

BO_ 2147548601 TPRI: 8 Vector__XXX
 SG_ ReferenceTirePress : 8|8@1+ (8,0) [0|2000] "kPa" Vector__XXX
 SG_ TireLocation : 0|8@1+ (1,0) [0|255] "" Vector__XXX

BO_ 2147548794 TP3: 8 Vector__XXX
 SG_ SteerChannelTirePress : 32|16@1+ (0.5,0) [0|32127.5] "kPa" Vector__XXX
 SG_ DriveChannelTirePress : 16|16@1+ (0.5,0) [0|32127.5] "kPa" Vector__XXX
 SG_ TrailerTagPushChannelTirePress : 0|16@1+ (0.5,0) [0|32127.5] "kPa" Vector__XXX

BO_ 2147548793 TP2: 8 Vector__XXX
 SG_ SteerChannelTirePressTarget : 32|16@1+ (0.5,0) [0|32127.5] "kPa" Vector__XXX
 SG_ DriveChannelTirePressTarget : 16|16@1+ (0.5,0) [0|32127.5] "kPa" Vector__XXX
 SG_ TrlrTgPshChannelTirePressTarget : 0|16@1+ (0.5,0) [0|32127.5] "kPa" Vector__XXX

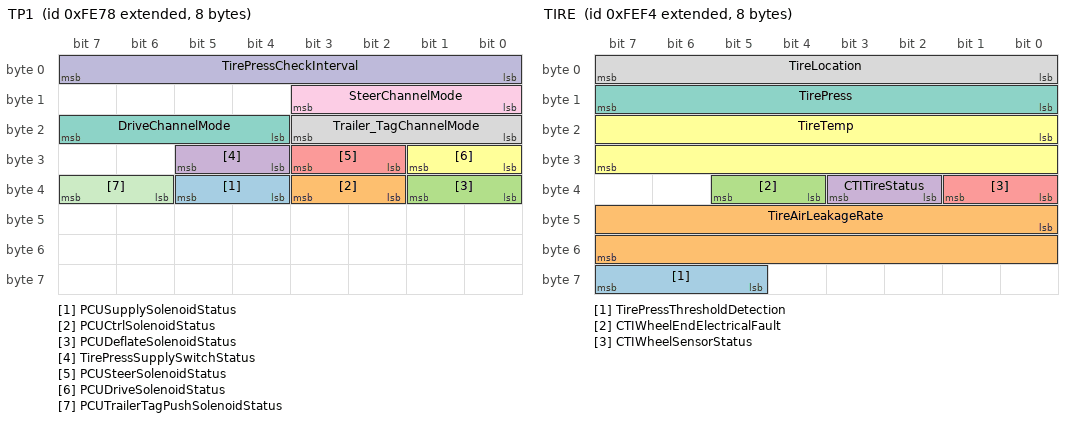
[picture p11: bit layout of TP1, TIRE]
BO_ 2147548792 TP1: 8 Vector__XXX
 SG_ PCUSupplySolenoidStatus : 36|2@1+ (1,0) [0|3] "" Vector__XXX
 SG_ PCUCtrlSolenoidStatus : 34|2@1+ (1,0) [0|3] "" Vector__XXX
 SG_ PCUDeflateSolenoidStatus : 32|2@1+ (1,0) [0|3] "" Vector__XXX
 SG_ TirePressSupplySwitchStatus : 28|2@1+ (1,0) [0|3] "" Vector__XXX
 SG_ PCUSteerSolenoidStatus : 26|2@1+ (1,0) [0|3] "" Vector__XXX
 SG_ PCUDriveSolenoidStatus : 24|2@1+ (1,0) [0|3] "" Vector__XXX
 SG_ DriveChannelMode : 20|4@1+ (1,0) [0|15] "" Vector__XXX
 SG_ Trailer_TagChannelMode : 16|4@1+ (1,0) [0|15] "" Vector__XXX
 SG_ SteerChannelMode : 8|4@1+ (1,0) [0|15] "" Vector__XXX
 SG_ TirePressCheckInterval : 0|8@1+ (1,0) [0|250] "mins" Vector__XXX
 SG_ PCUTrailerTagPushSolenoidStatus : 38|2@1+ (1,0) [0|3] "" Vector__XXX

BO_ 2147548916 TIRE: 8 Vector__XXX
 SG_ TirePressThresholdDetection : 61|3@1+ (1,0) [0|7] "" Vector__XXX
 SG_ TireAirLeakageRate : 40|16@1+ (0.1,0) [0|0] "/s" Vector__XXX
 SG_ CTIWheelEndElectricalFault : 36|2@1+ (1,0) [0|3] "" Vector__XXX
 SG_ CTITireStatus : 34|2@1+ (1,0) [0|3] "" Vector__XXX
 SG_ CTIWheelSensorStatus : 32|2@1+ (1,0) [0|3] "" Vector__XXX
 SG_ TireTemp : 16|16@1+ (0.03125,-273) [-273|1735] "deg" Vector__XXX
 SG_ TirePress : 8|8@1+ (4,0) [0|1000] "kPa" Vector__XXX
 SG_ TireLocation : 0|8@1+ (1,0) [0|255] "" Vector__XXX

BO_ 2147548758 TI1: 8 Vector__XXX
 SG_ CatalystTankTemp : 8|8@1+ (1,-40) [-40|210] "deg" Vector__XXX
 SG_ CatalystTankLevel : 0|8@1+ (0.4,0) [0|100] "%" Vector__XXX

BO_ 2147548859 TFI: 16 Vector__XXX
 SG_ TripFanOnTimeDueToAManualSwitch : 64|32@1+ (0.05,0) [0|210554060.75] "hr" Vector__XXX
 SG_ TripFanOnTime : 0|32@1+ (0.05,0) [0|210554060.75] "hr" Vector__XXX
 SG_ TripFanOnTimeDueToA_CSystem : 96|32@1+ (0.05,0) [0|210554060.75] "hr" Vector__XXX
 SG_ TripFanOnTimeDueToEngSystem : 32|32@1+ (0.05,0) [0|210554060.75] "hr" Vector__XXX

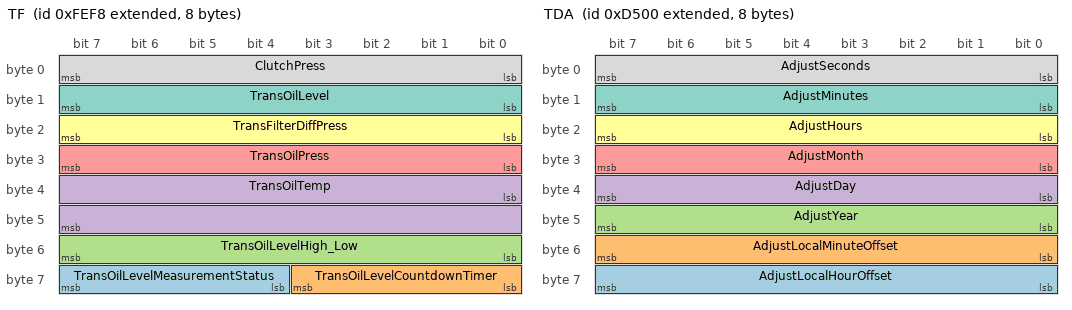
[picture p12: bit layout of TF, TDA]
BO_ 2147548920 TF: 8 Vector__XXX
 SG_ TransOilLevelMeasurementStatus : 60|4@1+ (1,0) [0|15] "" Vector__XXX
 SG_ TransOilLevelCountdownTimer : 56|4@1+ (1,0) [0|15] "" Vector__XXX
 SG_ TransOilLevelHigh_Low : 48|8@1+ (0.5,-61.5) [-61.5|62.5] "L" Vector__XXX
 SG_ TransOilTemp : 32|16@1+ (0.03125,-273) [-273|1735] "deg" Vector__XXX
 SG_ TransOilPress : 24|8@1+ (16,0) [0|4000] "kPa" Vector__XXX
 SG_ TransFilterDiffPress : 16|8@1+ (2,0) [0|500] "kPa" Vector__XXX
 SG_ TransOilLevel : 8|8@1+ (0.4,0) [0|100] "%" Vector__XXX
 SG_ ClutchPress : 0|8@1+ (16,0) [0|4000] "kPa" Vector__XXX

BO_ 2147548858 TDI: 12 Vector__XXX
 SG_ TripDistanceInTopGear : 64|32@1+ (0.125,0) [0|526385151.9] "km" Vector__XXX
 SG_ TripGearDownDistance : 32|32@1+ (0.125,0) [0|526385151.9] "km" Vector__XXX
 SG_ TripDistanceOnVSL : 0|32@1+ (0.125,0) [0|526385151.9] "km" Vector__XXX

BO_ 2147538176 TDA: 8 Vector__XXX
 SG_ AdjustLocalHourOffset : 56|8@1+ (1,-125) [-125|125] "hr" Vector__XXX
 SG_ AdjustLocalMinuteOffset : 48|8@1+ (1,-125) [-125|125] "mins" Vector__XXX
 SG_ AdjustYear : 40|8@1+ (1,1985) [1985|2235] "years" Vector__XXX
 SG_ AdjustDay : 32|8@1+ (0.25,0) [0|62.5] "days" Vector__XXX
 SG_ AdjustMonth : 24|8@1+ (1,0) [0|250] "months" Vector__XXX
 SG_ AdjustHours : 16|8@1+ (1,0) [0|250] "hr" Vector__XXX
 SG_ AdjustMinutes : 8|8@1+ (1,0) [0|250] "mins" Vector__XXX
 SG_ AdjustSeconds : 0|8@1+ (0.25,0) [0|62.5] "s" Vector__XXX

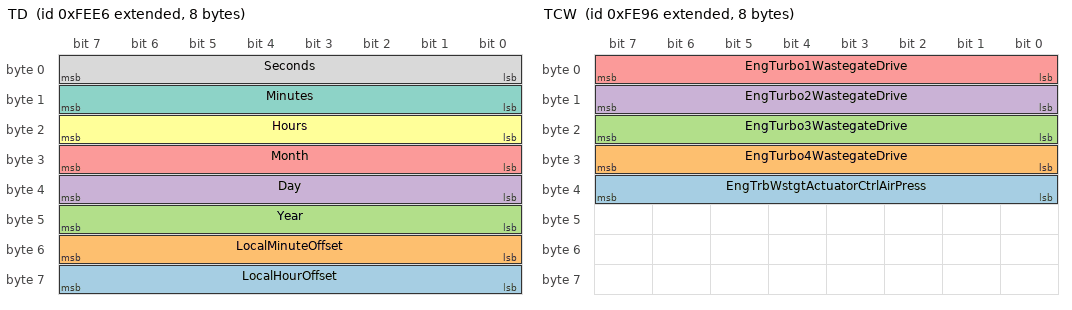
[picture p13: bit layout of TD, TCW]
BO_ 2147548902 TD: 8 Vector__XXX
 SG_ LocalHourOffset : 56|8@1+ (1,-125) [-125|125] "hr" Vector__XXX
 SG_ LocalMinuteOffset : 48|8@1+ (1,-125) [-125|125] "mins" Vector__XXX
 SG_ Year : 40|8@1+ (1,1985) [1985|2235] "years" Vector__XXX
 SG_ Day : 32|8@1+ (0.25,0) [0|62.5] "days" Vector__XXX
 SG_ Month : 24|8@1+ (1,0) [0|250] "months" Vector__XXX
 SG_ Hours : 16|8@1+ (1,0) [0|250] "hr" Vector__XXX
 SG_ Minutes : 8|8@1+ (1,0) [0|250] "mins" Vector__XXX
 SG_ Seconds : 0|8@1+ (0.25,0) [0|62.5] "s" Vector__XXX

BO_ 2147548822 TCW: 8 Vector__XXX
 SG_ EngTrbWstgtActuatorCtrlAirPress : 32|8@1+ (4,0) [0|1000] "kPa" Vector__XXX
 SG_ EngTurbo4WastegateDrive : 24|8@1+ (0.4,0) [0|100] "%" Vector__XXX
 SG_ EngTurbo3WastegateDrive : 16|8@1+ (0.4,0) [0|100] "%" Vector__XXX
 SG_ EngTurbo2WastegateDrive : 8|8@1+ (0.4,0) [0|100] "%" Vector__XXX
 SG_ EngTurbo1WastegateDrive : 0|8@1+ (0.4,0) [0|100] "%" Vector__XXX

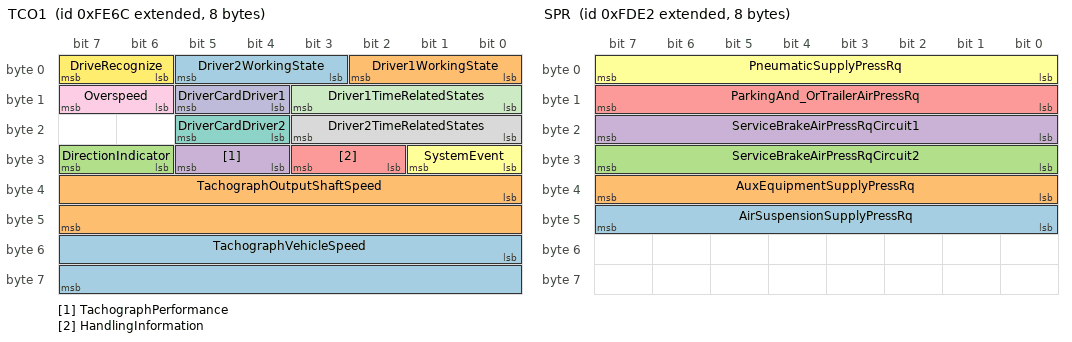
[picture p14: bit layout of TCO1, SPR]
BO_ 2147548780 TCO1: 8 Vector__XXX
 SG_ TachographVehicleSpeed : 48|16@1+ (1,0) [0|250.996] "km/h" Vector__XXX
 SG_ TachographOutputShaftSpeed : 32|16@1+ (0.125,0) [0|8031.875] "rpm" Vector__XXX
 SG_ DirectionIndicator : 30|2@1+ (1,0) [0|3] "" Vector__XXX
 SG_ TachographPerformance : 28|2@1+ (1,0) [0|3] "" Vector__XXX
 SG_ HandlingInformation : 26|2@1+ (1,0) [0|3] "" Vector__XXX
 SG_ SystemEvent : 24|2@1+ (1,0) [0|3] "" Vector__XXX
 SG_ DriverCardDriver2 : 20|2@1+ (1,0) [0|3] "" Vector__XXX
 SG_ Driver2TimeRelatedStates : 16|4@1+ (1,0) [0|15] "" Vector__XXX
 SG_ Overspeed : 14|2@1+ (1,0) [0|3] "" Vector__XXX
 SG_ DriverCardDriver1 : 12|2@1+ (1,0) [0|3] "" Vector__XXX
 SG_ Driver1TimeRelatedStates : 8|4@1+ (1,0) [0|15] "" Vector__XXX
 SG_ DriveRecognize : 6|2@1+ (1,0) [0|3] "" Vector__XXX
 SG_ Driver2WorkingState : 3|3@1+ (1,0) [0|7] "" Vector__XXX
 SG_ Driver1WorkingState : 0|3@1+ (1,0) [0|7] "" Vector__XXX

BO_ 2147548627 TCI6: 8 Vector__XXX
 SG_ EngTurbo4CompressorOutletTemp : 48|16@1+ (0.03125,-273) [-273|1735] "deg" Vector__XXX
 SG_ EngTurbo3CompressorOutletTemp : 32|16@1+ (0.03125,-273) [-273|1735] "deg" Vector__XXX
 SG_ EngTurbo2CompressorOutletTemp : 16|16@1+ (0.03125,-273) [-273|1735] "deg" Vector__XXX
 SG_ EngTurbo1CompressorOutletTemp : 0|16@1+ (0.03125,-273) [-273|1735] "deg" Vector__XXX

BO_ 2147548823 TCI5: 8 Vector__XXX
 SG_ EngTurbo4TurbineOutletTemp : 48|16@1+ (0.03125,-273) [-273|1735] "deg" Vector__XXX
 SG_ EngTurbo3TurbineOutletTemp : 32|16@1+ (0.03125,-273) [-273|1735] "deg" Vector__XXX
 SG_ EngTurbo2TurbineOutletTemp : 16|16@1+ (0.03125,-273) [-273|1735] "deg" Vector__XXX
 SG_ EngTurbo1TurbineOutletTemp : 0|16@1+ (0.03125,-273) [-273|1735] "deg" Vector__XXX

BO_ 2147548824 TCI4: 8 Vector__XXX
 SG_ EngTurbo4TurbineInletTemp : 48|16@1+ (0.03125,-273) [-273|1735] "deg" Vector__XXX
 SG_ EngTurbo3TurbineInletTemp : 32|16@1+ (0.03125,-273) [-273|1735] "deg" Vector__XXX
 SG_ EngTurbo2TurbineInletTemp : 16|16@1+ (0.03125,-273) [-273|1735] "deg" Vector__XXX
 SG_ EngTurbo1TurbineInletTemp : 0|16@1+ (0.03125,-273) [-273|1735] "deg" Vector__XXX

BO_ 2147548825 TCI3: 8 Vector__XXX
 SG_ EngTurbo4CompressorInletPress : 48|16@1+ (1,-250) [-250|0] "a" Vector__XXX
 SG_ EngTurbo3CompressorInletPress : 32|16@1+ (1,-250) [-250|0] "a" Vector__XXX
 SG_ EngTurbo2CompressorInletPress : 16|16@1+ (1,-250) [-250|0] "a" Vector__XXX
 SG_ EngTurbo1CompressorInletPress : 0|16@1+ (1,-250) [-250|0] "a" Vector__XXX

BO_ 2147548826 TCI2: 8 Vector__XXX
 SG_ EngTurbo4CompressorInletTemp : 48|16@1+ (0.03125,-273) [-273|1735] "deg" Vector__XXX
 SG_ EngTurbo3CompressorInletTemp : 32|16@1+ (0.03125,-273) [-273|1735] "deg" Vector__XXX
 SG_ EngTurbo2CompressorInletTemp : 16|16@1+ (0.03125,-273) [-273|1735] "deg" Vector__XXX
 SG_ EngTurbo1CompressorInletTemp : 0|16@1+ (0.03125,-273) [-273|1735] "deg" Vector__XXX

BO_ 2147548827 TCI1: 8 Vector__XXX
 SG_ EngTurbo4Speed : 40|16@1+ (4,0) [0|257020] "rpm" Vector__XXX
 SG_ EngTurbo3Speed : 24|16@1+ (4,0) [0|257020] "rpm" Vector__XXX
 SG_ EngTurbo2Speed : 8|16@1+ (4,0) [0|257020] "rpm" Vector__XXX
 SG_ EngTurboLubeOilPress2 : 0|8@1+ (4,0) [0|1000] "kPa" Vector__XXX

BO_ 2147548747 TCFG2: 8 Vector__XXX
 SG_ TransTorqueLimit : 0|16@1+ (1,0) [0|64255] "Nm" Vector__XXX

BO_ 2147548898 TCFG: 8 Vector__XXX
 SG_ TransGearRatio : 16|16@1+ (0.001,0) [0|64.255] "" Vector__XXX
 SG_ NumberOfForwardGearRatios : 8|8@1+ (1,0) [0|250] "" Vector__XXX
 SG_ NumberOfReverseGearRatios : 0|8@1+ (1,0) [0|250] "" Vector__XXX

BO_ 2147483904 TC1: 8 Vector__XXX
 SG_ TrnsShftSlctorDisplayModeSwitch : 54|2@1+ (1,0) [0|3] "" Vector__XXX
 SG_ TransMode4 : 46|2@1+ (1,0) [0|3] "" Vector__XXX
 SG_ TransMode3 : 44|2@1+ (1,0) [0|3] "" Vector__XXX
 SG_ TransMode2 : 42|2@1+ (1,0) [0|3] "" Vector__XXX
 SG_ TransMode1 : 40|2@1+ (1,0) [0|3] "" Vector__XXX
 SG_ DisengageDiffLockRqCentralRear : 36|2@1+ (1,0) [0|3] "" Vector__XXX
 SG_ DisengageDiffLockRqCentralFront : 34|2@1+ (1,0) [0|3] "" Vector__XXX
 SG_ DisengageDiffLockRqCentral : 32|2@1+ (1,0) [0|3] "" Vector__XXX
 SG_ DisengageDiffLockRqRearAxle2 : 30|2@1+ (1,0) [0|3] "" Vector__XXX
 SG_ DisengageDiffLockRqRearAxle1 : 28|2@1+ (1,0) [0|3] "" Vector__XXX
 SG_ DisengageDiffLockRqFrontAxle2 : 26|2@1+ (1,0) [0|3] "" Vector__XXX
 SG_ DisengageDiffLockRqFrontAxle1 : 24|2@1+ (1,0) [0|3] "" Vector__XXX
 SG_ TransRqedGear : 16|8@1+ (1,-125) [-125|125] "" Vector__XXX
 SG_ RqedPercentClutchSlip : 8|8@1+ (0.4,0) [0|100] "%" Vector__XXX
 SG_ DisengageDrivelineRq : 4|2@1+ (1,0) [0|3] "" Vector__XXX
 SG_ TorqueConverterLockupDisableRq : 2|2@1+ (1,0) [0|3] "" Vector__XXX
 SG_ TransGearShiftInhibitRq : 0|2@1+ (1,0) [0|3] "" Vector__XXX

BO_ 2147548893 TC: 8 Vector__XXX
 SG_ EngTurboOilLevelSwitch : 30|2@1+ (1,0) [0|3] "" Vector__XXX
 SG_ EngTurbo1Speed : 8|16@1+ (4,0) [0|257020] "rpm" Vector__XXX
 SG_ EngTurboLubeOilPress1 : 0|8@1+ (4,0) [0|1000] "kPa" Vector__XXX

BO_ 2147548749 TAVG: 8 Vector__XXX
 SG_ EngTotalAverageFuelEconomy : 16|16@1+ (1,0) [0|125.5] "km/L" Vector__XXX
 SG_ EngTotalAverageFuelRate : 0|16@1+ (0.05,0) [0|3212.75] "L/h" Vector__XXX

BO_ 2147548642 SPR: 8 Vector__XXX
 SG_ AirSuspensionSupplyPressRq : 40|8@1+ (8,0) [0|2000] "kPa" Vector__XXX
 SG_ AuxEquipmentSupplyPressRq : 32|8@1+ (8,0) [0|2000] "kPa" Vector__XXX
 SG_ ServiceBrakeAirPressRqCircuit2 : 24|8@1+ (8,0) [0|2000] "kPa" Vector__XXX
 SG_ ServiceBrakeAirPressRqCircuit1 : 16|8@1+ (8,0) [0|2000] "kPa" Vector__XXX
 SG_ ParkingAnd_OrTrailerAirPressRq : 8|8@1+ (8,0) [0|2000] "kPa" Vector__XXX
 SG_ PneumaticSupplyPressRq : 0|8@1+ (8,0) [0|2000] "kPa" Vector__XXX

BO_ 2147548815 SP2: 8 Vector__XXX
 SG_ EngExtlShutdownAirSupplyPress : 0|16@1+ (0.5,0) [0|32127.5] "kPa" Vector__XXX

BO_ 2147548890 SOFT: 8 Vector__XXX
 SG_ NmbrOfSftwrIdentificationFields : 0|8@1+ (1,0) [0|250] "steps" Vector__XXX

BO_ 2147548900 SHUTDOW: 8 Vector__XXX
 SG_ EngOverspeedTest : 54|2@1+ (1,0) [0|3] "" Vector__XXX
 SG_ EngAirShutoffCmdStatus : 52|2@1+ (1,0) [0|3] "" Vector__XXX
 SG_ EngAlarmOutputCmdStatus : 50|2@1+ (1,0) [0|3] "" Vector__XXX
 SG_ EngAlarmAcknowledge : 48|2@1+ (1,0) [0|3] "" Vector__XXX
 SG_ EngProtectionSystemConfig : 46|2@1+ (1,0) [0|3] "" Vector__XXX
 SG_ EngProtectionSystemTimerState : 38|2@1+ (1,0) [0|3] "" Vector__XXX
 SG_ EngPrtectionSystemTimerOverride : 36|2@1+ (1,0) [0|3] "" Vector__XXX
 SG_ EngPrtctnSystmApprchingShutdown : 34|2@1+ (1,0) [0|3] "" Vector__XXX
 SG_ EngPrtctionSystemHasShutdownEng : 32|2@1+ (1,0) [0|3] "" Vector__XXX
 SG_ EngWaitToStartLamp : 24|2@1+ (1,0) [0|3] "" Vector__XXX
 SG_ RefrigerantHighPressSwitch : 20|2@1+ (1,0) [0|3] "" Vector__XXX
 SG_ RefrigerantLowPressSwitch : 18|2@1+ (1,0) [0|3] "" Vector__XXX
 SG_ A_CHighPressFanSwitch : 16|2@1+ (1,0) [0|3] "" Vector__XXX
 SG_ EngIdleShutdownTimerFunction : 14|2@1+ (1,0) [0|3] "" Vector__XXX
 SG_ EngIdleShutdownTimerState : 6|2@1+ (1,0) [0|3] "" Vector__XXX
 SG_ EngIdleShutdownTimerOverride : 4|2@1+ (1,0) [0|3] "" Vector__XXX
 SG_ EngIdleShutdownDriverAlertMode : 2|2@1+ (1,0) [0|3] "" Vector__XXX
 SG_ EngIdleShutdownHasShutdownEng : 0|2@1+ (1,0) [0|3] "" Vector__XXX

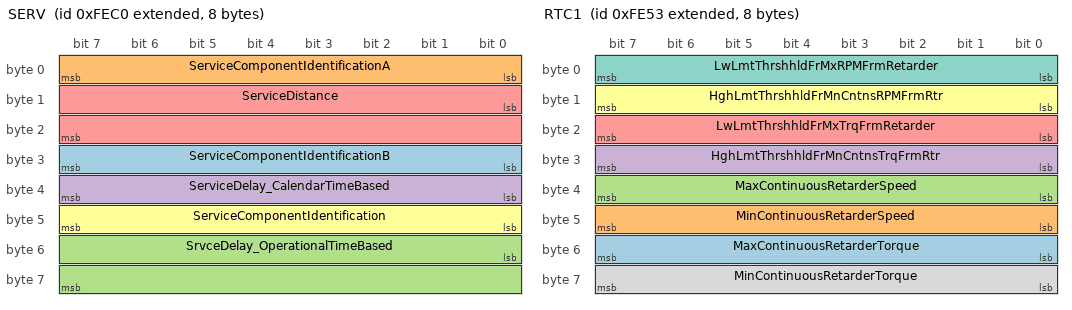
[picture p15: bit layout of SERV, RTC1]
BO_ 2147548864 SERV: 8 Vector__XXX
 SG_ ServiceComponentIdentificationB : 24|8@1+ (1,0) [0|250] "ID" Vector__XXX
 SG_ ServiceComponentIdentificationA : 0|8@1+ (1,0) [0|250] "ID" Vector__XXX
 SG_ SrvceDelay_OperationalTimeBased : 48|16@1+ (1,-31873) [-31873|32128] "hr" Vector__XXX
 SG_ ServiceDelay_CalendarTimeBased : 32|8@1+ (1,-125) [-125|125] "weeks" Vector__XXX
 SG_ ServiceDistance : 8|16@1+ (5,-159365) [-159365|160640] "km" Vector__XXX
 SG_ ServiceComponentIdentification : 40|8@1+ (1,0) [0|250] "ID" Vector__XXX

BO_ 2147548814 S2: 8 Vector__XXX
 SG_ TimeSinceLastService : 8|16@1+ (1,-31873) [-31873|32128] "hr" Vector__XXX
 SG_ ServiceComponentIdentification : 0|8@1+ (1,0) [0|250] "ID" Vector__XXX

BO_ 2147548755 RTC1: 8 Vector__XXX
 SG_ MaxContinuousRetarderTorque : 48|8@1+ (1,-125) [-125|125] "%" Vector__XXX
 SG_ MinContinuousRetarderSpeed : 40|8@1+ (32,0) [0|8000] "rpm" Vector__XXX
 SG_ MaxContinuousRetarderSpeed : 32|8@1+ (32,0) [0|8000] "rpm" Vector__XXX
 SG_ HghLmtThrshhldFrMnCntnsTrqFrmRtr : 24|8@1+ (1,-125) [-125|125] "%" Vector__XXX
 SG_ LwLmtThrshhldFrMxTrqFrmRetarder : 16|8@1+ (1,-125) [-125|125] "%" Vector__XXX
 SG_ HghLmtThrshhldFrMnCntnsRPMFrmRtr : 8|8@1+ (32,0) [0|8000] "rpm" Vector__XXX
 SG_ LwLmtThrshhldFrMxRPMFrmRetarder : 0|8@1+ (32,0) [0|8000] "rpm" Vector__XXX
 SG_ MinContinuousRetarderTorque : 56|8@1+ (1,-125) [-125|125] "%" Vector__XXX

BO_ 2147548923 RF: 8 Vector__XXX
 SG_ HydRetarderOilTemp : 8|8@1+ (1,-40) [-40|210] "deg" Vector__XXX
 SG_ HydRetarderPress : 0|8@1+ (16,0) [0|4000] "kPa" Vector__XXX

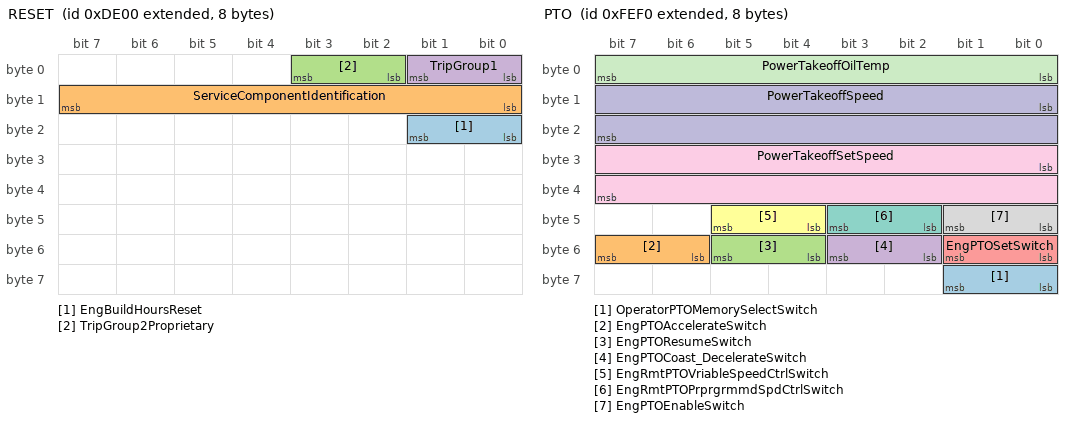
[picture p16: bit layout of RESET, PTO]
BO_ 2147540480 RESET: 8 Vector__XXX
 SG_ EngBuildHoursReset : 16|2@1+ (1,0) [0|3] "" Vector__XXX
 SG_ ServiceComponentIdentification : 8|8@1+ (1,0) [0|250] "ID" Vector__XXX
 SG_ TripGroup2Proprietary : 2|2@1+ (1,0) [0|3] "" Vector__XXX
 SG_ TripGroup1 : 0|2@1+ (1,0) [0|3] "" Vector__XXX

BO_ 2147548897 RC: 19 Vector__XXX
 SG_ PercentTorqueAtPeakTorquePoint5 : 144|8@1+ (1,-125) [-125|125] "%" Vector__XXX
 SG_ ReferenceRetarderTorque : 128|16@1+ (1,0) [0|64255] "Nm" Vector__XXX
 SG_ RetarderSpeedAtPeakTorquePoint5 : 112|16@1+ (0.125,0) [0|8031.875] "rpm" Vector__XXX
 SG_ PercentTorqueAtPoint4 : 104|8@1+ (1,-125) [-125|125] "%" Vector__XXX
 SG_ RetarderSpeedAtPoint4 : 88|16@1+ (0.125,0) [0|8031.875] "rpm" Vector__XXX
 SG_ PercentTorqueAtPoint3 : 80|8@1+ (1,-125) [-125|125] "%" Vector__XXX
 SG_ RetarderSpeedAtPoint3 : 64|16@1+ (0.125,0) [0|8031.875] "rpm" Vector__XXX
 SG_ PercentTorqueAtMaxSpeedPoint2 : 56|8@1+ (1,-125) [-125|125] "%" Vector__XXX
 SG_ MaxRetarderSpeedPoint2 : 40|16@1+ (0.125,0) [0|8031.875] "rpm" Vector__XXX
 SG_ PercentTorqueAtIdlePoint1 : 32|8@1+ (1,-125) [-125|125] "%" Vector__XXX
 SG_ RetarderSpeedAtIdlePoint1 : 16|16@1+ (0.125,0) [0|8031.875] "rpm" Vector__XXX
 SG_ RetarderCtrlMethod : 8|8@1+ (1,0) [0|250] "steps" Vector__XXX
 SG_ RetarderLocation : 4|4@1+ (1,0) [0|15] "" Vector__XXX
 SG_ RetarderType : 0|4@1+ (1,0) [0|15] "" Vector__XXX

BO_ 2147548821 RBI: 8 Vector__XXX
 SG_ EngOperationTimeSinceRebuild : 0|32@1+ (1,0) [0|4211081215] "s" Vector__XXX

BO_ 2147548912 PTO: 8 Vector__XXX
 SG_ OperatorPTOMemorySelectSwitch : 56|2@1+ (1,0) [0|3] "" Vector__XXX
 SG_ EngPTOAccelerateSwitch : 54|2@1+ (1,0) [0|3] "" Vector__XXX
 SG_ EngPTOResumeSwitch : 52|2@1+ (1,0) [0|3] "" Vector__XXX
 SG_ EngPTOCoast_DecelerateSwitch : 50|2@1+ (1,0) [0|3] "" Vector__XXX
 SG_ EngPTOSetSwitch : 48|2@1+ (1,0) [0|3] "" Vector__XXX
 SG_ EngRmtPTOVriableSpeedCtrlSwitch : 44|2@1+ (1,0) [0|3] "" Vector__XXX
 SG_ EngRmtPTOPrprgrmmdSpdCtrlSwitch : 42|2@1+ (1,0) [0|3] "" Vector__XXX
 SG_ EngPTOEnableSwitch : 40|2@1+ (1,0) [0|3] "" Vector__XXX
 SG_ PowerTakeoffSetSpeed : 24|16@1+ (0.125,0) [0|8031.875] "rpm" Vector__XXX
 SG_ PowerTakeoffSpeed : 8|16@1+ (0.125,0) [0|8031.875] "rpm" Vector__XXX
 SG_ PowerTakeoffOilTemp : 0|8@1+ (1,-40) [-40|210] "deg" Vector__XXX

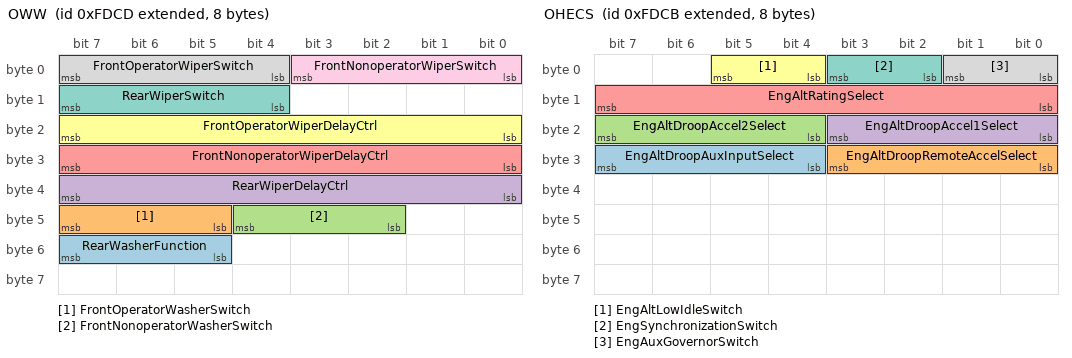
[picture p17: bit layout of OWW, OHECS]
BO_ 2147548621 OWW: 8 Vector__XXX
 SG_ RearWasherFunction : 53|3@1+ (1,0) [0|7] "" Vector__XXX
 SG_ FrontOperatorWasherSwitch : 45|3@1+ (1,0) [0|7] "" Vector__XXX
 SG_ FrontNonoperatorWasherSwitch : 42|3@1+ (1,0) [0|7] "" Vector__XXX
 SG_ RearWiperDelayCtrl : 32|8@1+ (0.4,0) [0|100] "%" Vector__XXX
 SG_ FrontNonoperatorWiperDelayCtrl : 24|8@1+ (0.4,0) [0|100] "%" Vector__XXX
 SG_ FrontOperatorWiperDelayCtrl : 16|8@1+ (0.4,0) [0|100] "%" Vector__XXX
 SG_ RearWiperSwitch : 12|4@1+ (1,0) [0|15] "" Vector__XXX
 SG_ FrontOperatorWiperSwitch : 4|4@1+ (1,0) [0|15] "" Vector__XXX
 SG_ FrontNonoperatorWiperSwitch : 0|4@1+ (1,0) [0|15] "" Vector__XXX

BO_ 2147548619 OHECS: 8 Vector__XXX
 SG_ EngAltDroopAuxInputSelect : 28|4@1+ (1,0) [0|15] "" Vector__XXX
 SG_ EngAltDroopRemoteAccelSelect : 24|4@1+ (1,0) [0|15] "" Vector__XXX
 SG_ EngAltDroopAccel2Select : 20|4@1+ (1,0) [0|15] "" Vector__XXX
 SG_ EngAltDroopAccel1Select : 16|4@1+ (1,0) [0|15] "" Vector__XXX
 SG_ EngAltRatingSelect : 8|8@1+ (1,0) [0|255] "" Vector__XXX
 SG_ EngAltLowIdleSwitch : 4|2@1+ (1,0) [0|3] "" Vector__XXX
 SG_ EngSynchronizationSwitch : 2|2@1+ (1,0) [0|3] "" Vector__XXX
 SG_ EngAuxGovernorSwitch : 0|2@1+ (1,0) [0|3] "" Vector__XXX

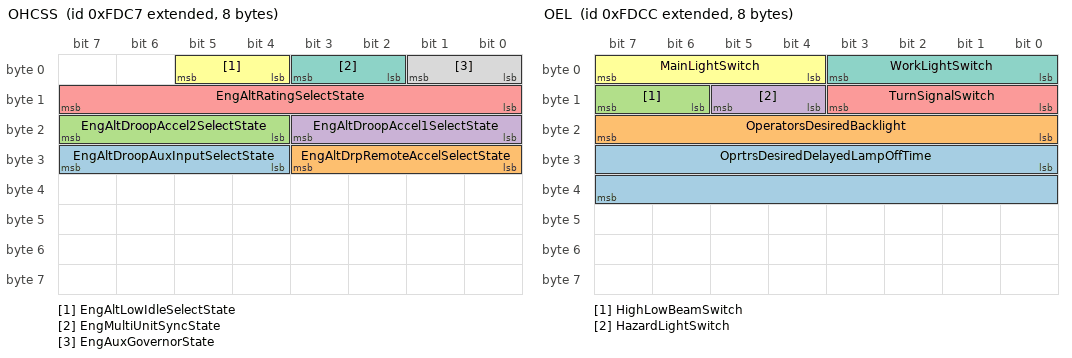
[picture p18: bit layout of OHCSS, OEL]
BO_ 2147548615 OHCSS: 8 Vector__XXX
 SG_ EngAltDroopAuxInputSelectState : 28|4@1+ (1,0) [0|15] "" Vector__XXX
 SG_ EngAltDrpRemoteAccelSelectState : 24|4@1+ (1,0) [0|15] "" Vector__XXX
 SG_ EngAltDroopAccel2SelectState : 20|4@1+ (1,0) [0|15] "" Vector__XXX
 SG_ EngAltDroopAccel1SelectState : 16|4@1+ (1,0) [0|15] "" Vector__XXX
 SG_ EngAltRatingSelectState : 8|8@1+ (1,0) [0|255] "" Vector__XXX
 SG_ EngAltLowIdleSelectState : 4|2@1+ (1,0) [0|3] "" Vector__XXX
 SG_ EngMultiUnitSyncState : 2|2@1+ (1,0) [0|3] "" Vector__XXX
 SG_ EngAuxGovernorState : 0|2@1+ (1,0) [0|3] "" Vector__XXX

BO_ 2147548620 OEL: 8 Vector__XXX
 SG_ OprtrsDesiredDelayedLampOffTime : 24|16@1+ (1,0) [0|64255] "s" Vector__XXX
 SG_ OperatorsDesiredBacklight : 16|8@1+ (0.4,0) [0|100] "%" Vector__XXX
 SG_ HighLowBeamSwitch : 14|2@1+ (1,0) [0|3] "" Vector__XXX
 SG_ HazardLightSwitch : 12|2@1+ (1,0) [0|3] "" Vector__XXX
 SG_ TurnSignalSwitch : 8|4@1+ (1,0) [0|15] "" Vector__XXX
 SG_ MainLightSwitch : 4|4@1+ (1,0) [0|15] "" Vector__XXX
 SG_ WorkLightSwitch : 0|4@1+ (1,0) [0|15] "" Vector__XXX

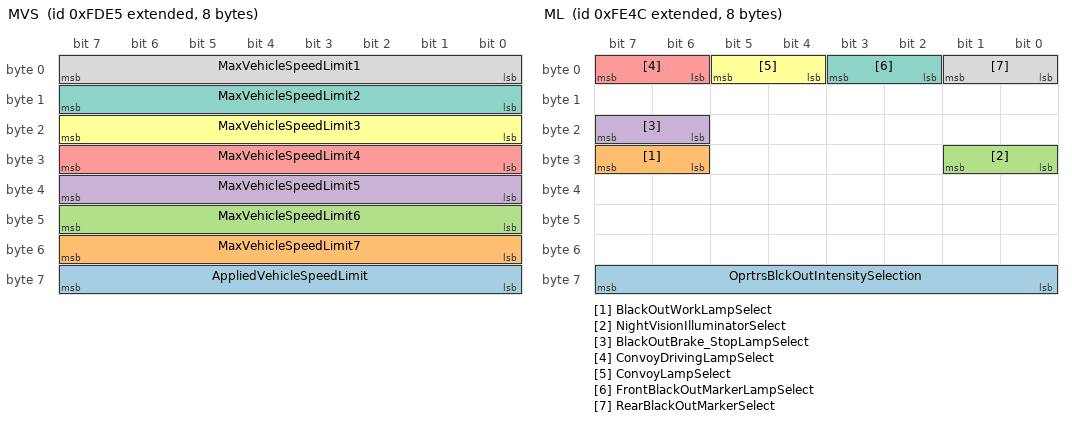
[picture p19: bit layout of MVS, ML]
BO_ 2147548645 MVS: 8 Vector__XXX
 SG_ AppliedVehicleSpeedLimit : 56|8@1+ (1,0) [0|250] "km/h" Vector__XXX
 SG_ MaxVehicleSpeedLimit7 : 48|8@1+ (1,0) [0|250] "km/h" Vector__XXX
 SG_ MaxVehicleSpeedLimit6 : 40|8@1+ (1,0) [0|250] "km/h" Vector__XXX
 SG_ MaxVehicleSpeedLimit5 : 32|8@1+ (1,0) [0|250] "km/h" Vector__XXX
 SG_ MaxVehicleSpeedLimit4 : 24|8@1+ (1,0) [0|250] "km/h" Vector__XXX
 SG_ MaxVehicleSpeedLimit3 : 16|8@1+ (1,0) [0|250] "km/h" Vector__XXX
 SG_ MaxVehicleSpeedLimit2 : 8|8@1+ (1,0) [0|250] "km/h" Vector__XXX
 SG_ MaxVehicleSpeedLimit1 : 0|8@1+ (1,0) [0|250] "km/h" Vector__XXX

BO_ 2147548748 ML: 8 Vector__XXX
 SG_ OprtrsBlckOutIntensitySelection : 56|8@1+ (0.4,0) [0|100] "%" Vector__XXX
 SG_ BlackOutWorkLampSelect : 30|2@1+ (1,0) [0|3] "" Vector__XXX
 SG_ NightVisionIlluminatorSelect : 24|2@1+ (1,0) [0|3] "" Vector__XXX
 SG_ BlackOutBrake_StopLampSelect : 22|2@1+ (1,0) [0|3] "" Vector__XXX
 SG_ ConvoyDrivingLampSelect : 6|2@1+ (1,0) [0|3] "" Vector__XXX
 SG_ ConvoyLampSelect : 4|2@1+ (1,0) [0|3] "" Vector__XXX
 SG_ FrontBlackOutMarkerLampSelect : 2|2@1+ (1,0) [0|3] "" Vector__XXX
 SG_ RearBlackOutMarkerSelect : 0|2@1+ (1,0) [0|3] "" Vector__XXX

CM_ BO_ 2147548600 "Diagnostic Readiness 3";
CM_ SG_ 2147548600 NonContMonSysCompleteStatus "Completion status of non-continuous monitors this monitoring cycle.";
CM_ SG_ 2147548600 NonContMonSysEnableStatus "Enable status of non-continuous monitors this monitoring cycle.";
CM_ SG_ 2147548600 ContMonitoredSysEnableStatus "Enable status of non-continuous monitors this monitoring cycle.";
CM_ SG_ 2147548600 NumberOfWarmUps "Number of OBD warm-up cycles since all DTCs were cleared.";
CM_ SG_ 2147548600 TimeSinceEngineStart "Runtime shall increment while the engine is running.";
CM_ BO_ 2147537920 "Data Security";
CM_ BO_ 2147548855 "Engine Speed/Load Factor Information";
CM_ SG_ 2147548855 TripAverageEngSpeed "Average speed of the engine since the last trip reset.";
CM_ SG_ 2147548855 TripMaxEngSpeed "Maximum engine speed achieved since the last trip reset.";
CM_ BO_ 2147548736 "Lighting Data";
CM_ SG_ 2147548736 ImplementRearWorkLight "This parameter provides measured data from the implement rear work lamps.";
CM_ SG_ 2147548736 ImplementLeftForwardWorkLight "This parameter provides measured data from the forward facing work lights toward the left end of the implement.";
CM_ SG_ 2147548736 ImplementRightForwardWorkLight "This parameter provides measured data from the forward facing work lights toward the right end of the implement.";
CM_ SG_ 2147548736 ImplementOEMOption1Light "This parameter provides measured data from the implement OEM option 1 light.";
CM_ SG_ 2147548736 ImplementOEMOption2Light "This parameter provides measured data from the implement OEM option 2 light.";
CM_ SG_ 2147548736 TrctrFrontHighMountedWorkLights "This parameter provides measured data from the tractor front high mounted work lights.";
CM_ SG_ 2147548736 TrctorFrontLowMountedWorkLights "This parameter provides measured data from the tractor front low mounted work lights.";
CM_ SG_ 2147548736 TrctorSideHighMountedWorkLights "This parameter provides measured data from the tractor side high mounted work lights.";
CM_ SG_ 2147548736 TractorSideLowMountedWorkLights "This parameter provides measured data from the tractor side low mounted work lights.";
CM_ SG_ 2147548736 TrctorRearHighMountedWorkLights "This parameter provides measured data from the tractor rear high mounted work lights.";
CM_ SG_ 2147548736 TractorRearLowMountedWorkLights "This parameter provides measured data from the tractor rear low mounted work lights.";
CM_ SG_ 2147548736 TrctrUndersideMountedWorkLights "This parameter provides measured data from the tractor underside mounted work lights.";
CM_ SG_ 2147548736 RearFogLights "This parameter provides measured data from the tractor and/or implement rear fog lights.";
CM_ SG_ 2147548736 TractorClearanceLight "This parameter provides measured data from the tractor high mounted clearance and center ID lights.";
CM_ SG_ 2147548736 ImplementClearanceLight "This parameter provides measured data from an attached implement high mounted clearance lights.";
CM_ SG_ 2147548736 LeftStopLight "This parameter provides measured data from the tractor and attached implement left stop lights.";
CM_ SG_ 2147548736 RightStopLight "This parameter provides measured data from the tractor and attached implement right stop lights.";
CM_ SG_ 2147548736 CenterStopLight "This parameter provides measured data from the tractor and attached implement center stop lights.";
CM_ SG_ 2147548736 BackUpLightAndAlarmHorn "This parameter provides measured data from the back up lights and/ or associated alarm.";
CM_ SG_ 2147548736 LeftTurnSignalLights "This parameter provides measured data from the tractor and attached implement left turn signal lights.";
CM_ SG_ 2147548736 RightTurnSignalLights "This parameter provides measured data from the tractor and attached implement right turn signal lights.";
CM_ SG_ 2147548736 RotatingBeaconLight "This parameter provides measured data from the beacon light on tractor or attached implements.";
CM_ SG_ 2147548736 TractorFrontFogLights "This parameter provides measured data from the tractor front fog lights.";
CM_ SG_ 2147548736 HighBeamHeadLightData "This parameter provides measured data from the tractor high beam head light lamps.";
CM_ SG_ 2147548736 LowBeamHeadLightData "This parameter provides measured data from the tractor low beam head light lamps.";
CM_ SG_ 2147548736 AltBeamHeadLightData "This parameter provides measured data from the tractor alternate beam head light lamps.";
CM_ SG_ 2147548736 RunningLight "This parameter provides measured data from the vehicle’s running lights.";
CM_ BO_ 2147548737 "Lighting Command";
CM_ SG_ 2147548737 ImplementRearWorkLightCmd "Command to activate or de-activate implement rear work lights.";
CM_ SG_ 2147548737 ImplmentLeftForwardWorkLightCmd "Command to activate or de-activate the forward facing work lights toward the left end of the implement.";
CM_ SG_ 2147548737 ImplmntRightForwardWorkLightCmd "Command to activate or de-activate the forward facing work lights toward the right end of the implement.";
CM_ SG_ 2147548737 ImplementLeftFacingWorkLightCmd "Command to activate or de-activate work lights mounted on an implement to illuminate beyond left end of the implement.";
CM_ SG_ 2147548737 ImplmentRightFacingWorkLightCmd "Command to activate or de-activate work lights mounted on an implement to illuminate beyond right end of the implement.";
CM_ SG_ 2147548737 ImplementOEMOption1LightCmd "Command to activate or de-activate an implement OEM option 1 light.";
CM_ SG_ 2147548737 ImplementOEMOption2LightCmd "Command to activate or de-activate an implement OEM option 2 light.";
CM_ SG_ 2147548737 TrctrFrntHghMuntedWorkLightsCmd "Command to activate or de-activate the tractor front high mounted work lights.";
CM_ SG_ 2147548737 TrctrFrntLwMountedWorkLightsCmd "Command to activate or de-activate the tractor front low mounted work lights.";
CM_ SG_ 2147548737 TrctrSdHighMountedWorkLightsCmd "Command to activate or de-activate the tractor side high mounted work lights.";
CM_ SG_ 2147548737 TrctrSdeLowMountedWorkLightsCmd "Command to activate or de-activate the tractor side low mounted work lights.";
CM_ SG_ 2147548737 TrctrRrHighMountedWorkLightsCmd "Command to activate or de-activate the tractor rear high mounted work lights.";
CM_ SG_ 2147548737 TrctrRarLowMountedWorkLightsCmd "Command to activate or de-activate the tractor rear low mounted work lights.";
CM_ SG_ 2147548737 TrctrUndrsdMountedWorkLightsCmd "Command to activate or de-activate the tractor underside mounted work lights.";
CM_ SG_ 2147548737 RearFogLightCmd "Command to activate or de-activate tractor or implement rear fog lights.";
CM_ SG_ 2147548737 ImplementClearanceLightCmd "Command to activate or de-activate the implement high mounted clearance and lights.";
CM_ SG_ 2147548737 RotatingBeaconLightCmd "Command to activate or de-activate slow moving vehicle indicator lights on tractor and/or implements.";
CM_ SG_ 2147548737 TractorFrontFogLightsCmd "Command to activate or de-activate tractor front fog lights.";
CM_ SG_ 2147548737 HighBeamHeadLightCmd "Command to activate or de-activate the tractor high beam head light lamps.";
CM_ SG_ 2147548737 LowBeamHeadLightCmd "Command to activate or de-activate the tractor low beam head light lamps.";
CM_ SG_ 2147548737 AltBeamHeadLightCmd "Command to activate or de-activate the tractor alternate head lights (only low beam is available on alternate head lights).";
CM_ SG_ 2147548737 RunningLightCmd "Command to activate or de-activate the tractor or powered vehicle running lights.";
CM_ BO_ 2147548786 "Laser Leveling System Blade Control";
CM_ SG_ 2147548786 BladeCtrlMode "Allows the user to select the type of blade control for the land leveling system.";
CM_ SG_ 2147548786 BladeDurationAndDirection "Used to indicate the duration and direction that the land leveling system blade moves.";
CM_ BO_ 2147548807 "Ignition Timing 6";
CM_ SG_ 2147548807 EngActualIgntTiming "The actual ignition timing at the current engine conditions.";
CM_ SG_ 2147548807 EngDesiredIgntTiming3 "A programmable timing value specific to the engine’s application.";
CM_ SG_ 2147548807 EngDesiredIgntTiming2 "A programmable timing value specific to the engine’s application.";
CM_ SG_ 2147548807 EngDesiredIgntTiming1 "A programmable timing value specific to the engine’s application.";
CM_ BO_ 2147548806 "Ignition Timing 5";
CM_ SG_ 2147548806 EngCyl20IgntTiming "The ignition timing of the cylinder.";
CM_ SG_ 2147548806 EngCyl19IgntTiming "The ignition timing of the cylinder.";
CM_ SG_ 2147548806 EngCyl18IgntTiming "The ignition timing of the cylinder.";
CM_ SG_ 2147548806 EngCyl17IgntTiming "The ignition timing of the cylinder.";
CM_ BO_ 2147548805 "Ignition Timing 4";
CM_ SG_ 2147548805 EngCyl16IgntTiming "The ignition timing of the cylinder.";
CM_ SG_ 2147548805 EngCyl15IgntTiming "The ignition timing of the cylinder.";
CM_ SG_ 2147548805 EngCyl14IgntTiming "The ignition timing of the cylinder.";
CM_ SG_ 2147548805 EngCyl13IgntTiming "The ignition timing of the cylinder.";
CM_ BO_ 2147548804 "Ignition Timing 3";
CM_ SG_ 2147548804 EngCyl12IgntTiming "The ignition timing of the cylinder.";
CM_ SG_ 2147548804 EngCyl11IgntTiming "The ignition timing of the cylinder.";
CM_ SG_ 2147548804 EngCyl10IgntTiming "The ignition timing of the cylinder.";
CM_ SG_ 2147548804 EngCyl9IgntTiming "The ignition timing of the cylinder.";
CM_ BO_ 2147548803 "Ignition Timing 2";
CM_ SG_ 2147548803 EngCyl8IgntTiming "The ignition timing of the cylinder.";
CM_ SG_ 2147548803 EngCyl7IgntTiming "The ignition timing of the cylinder.";
CM_ SG_ 2147548803 EngCyl6IgntTiming "The ignition timing of the cylinder.";
CM_ SG_ 2147548803 EngCyl5IgntTiming "The ignition timing of the cylinder.";
CM_ BO_ 2147548802 "Ignition Timing 1";
CM_ SG_ 2147548802 EngCyl4IgntTiming "The ignition timing of the cylinder.";
CM_ SG_ 2147548802 EngCyl3IgntTiming "The ignition timing of the cylinder.";
CM_ SG_ 2147548802 EngCyl2IgntTiming "The ignition timing of the cylinder.";
CM_ SG_ 2147548802 EngCyl1IgntTiming "The ignition timing of the cylinder.";
CM_ BO_ 2147548810 "Ignition Transformer Secondary Output 3";
CM_ SG_ 2147548810 EngCyl20IgntTransSecondOutput "This parameter indicates the relative intensity of the secondary output voltage of the ignition transformer.";
CM_ SG_ 2147548810 EngCyl19IgntTransSecondOutput "This parameter indicates the relative intensity of the secondary output voltage of the ignition transformer.";
CM_ SG_ 2147548810 EngCyl18IgntTransSecondOutput "This parameter indicates the relative intensity of the secondary output voltage of the ignition transformer.";
CM_ SG_ 2147548810 EngCyl17IgntTransSecondOutput "This parameter indicates the relative intensity of the secondary output voltage of the ignition transformer.";
CM_ BO_ 2147548809 "Ignition Transformer Secondary Output 2";
CM_ SG_ 2147548809 EngCyl16IgntTransSecondOutput "This parameter indicates the relative intensity of the secondary output voltage of the ignition transformer.";
CM_ SG_ 2147548809 EngCyl15IgntTransSecondOutput "This parameter indicates the relative intensity of the secondary output voltage of the ignition transformer.";
CM_ SG_ 2147548809 EngCyl14IgntTransSecondOutput "This parameter indicates the relative intensity of the secondary output voltage of the ignition transformer.";
CM_ SG_ 2147548809 EngCyl13IgntTransSecondOutput "This parameter indicates the relative intensity of the secondary output voltage of the ignition transformer.";
CM_ SG_ 2147548809 EngCyl12IgntTransSecondOutput "This parameter indicates the relative intensity of the secondary output voltage of the ignition transformer.";
CM_ SG_ 2147548809 EngCyl11IgntTransSecondOutput "This parameter indicates the relative intensity of the secondary output voltage of the ignition transformer.";
CM_ SG_ 2147548809 EngCyl10IgntTransSecondOutput "This parameter indicates the relative intensity of the secondary output voltage of the ignition transformer.";
CM_ SG_ 2147548809 EngCyl9IgntTransSecondOutput "This parameter indicates the relative intensity of the secondary output voltage of the ignition transformer.";
CM_ BO_ 2147548808 "Ignition Transformer Secondary Output 1";
CM_ SG_ 2147548808 EngCyl8IgntTransSecondOutput "This parameter indicates the relative intensity of the secondary output voltage of the ignition transformer.";
CM_ SG_ 2147548808 EngCyl7IgntTransSecondOutput "This parameter indicates the relative intensity of the secondary output voltage of the ignition transformer.";
CM_ SG_ 2147548808 EngCyl6IgntTransSecondOutput "This parameter indicates the relative intensity of the secondary output voltage of the ignition transformer.";
CM_ SG_ 2147548808 EngCyl5IgntTransSecondOutput "This parameter indicates the relative intensity of the secondary output voltage of the ignition transformer.";
CM_ SG_ 2147548808 EngCyl4IgntTransSecondOutput "This parameter indicates the relative intensity of the secondary output voltage of the ignition transformer.";
CM_ SG_ 2147548808 EngCyl3IgntTransSecondOutput "This parameter indicates the relative intensity of the secondary output voltage of the ignition transformer.";
CM_ SG_ 2147548808 EngCyl2IgntTransSecondOutput "This parameter indicates the relative intensity of the secondary output voltage of the ignition transformer.";
CM_ SG_ 2147548808 EngCyl1IgntTransSecondOutput "This parameter indicates the relative intensity of the secondary output voltage of the ignition transformer.";
CM_ BO_ 2147548616 "Operator Primary Intermediate Speed Control state";
CM_ SG_ 2147548616 EngOprtrPrmryIntrmdtSpdSlctStte "13 preprogrammed intermediate speed control settings are availible for the contolling ECM to select.";
CM_ BO_ 2147548618 "Intermediate Speed Control";
CM_ SG_ 2147548618 EngOprtrPrmryIntrmdtSpeedSelect "Allows the operator to select one of 13 preprogrammed Intermediate Speed Control settings.";
CM_ BO_ 2147548892 "Idle Operation";
CM_ SG_ 2147548892 EngTotalIdleHours "Accumulated time of operation of the engine while under idle conditions.";
CM_ SG_ 2147548892 EngTotalIdleFuelUsed "Accumulated amount of fuel used during vehicle operation while under idle conditions.";
CM_ BO_ 2147548837 "Intake Manifold Information 2";
CM_ SG_ 2147548837 EngIntakeManifold6Temp "Temperature of pre-combustion air found in intake manifold number 6 of engine air supply system.";
CM_ SG_ 2147548837 EngIntakeManifold5Temp "Temperature of pre-combustion air found in intake manifold number 5 of engine air supply system.";
CM_ SG_ 2147548837 EngIntakeManifold4Temp "Temperature of pre-combustion air found in intake manifold of engine air supply system.";
CM_ SG_ 2147548837 EngIntakeManifold3Temp "Temperature of pre-combustion air found in intake manifold of engine air supply system.";
CM_ SG_ 2147548837 EngIntakeManifold2Temp "Temperature of pre-combustion air found in intake manifold of engine air supply system.";
CM_ BO_ 2147548838 "Intake Manifold Information 1";
CM_ SG_ 2147548838 EngTurbo4BoostPress "Gage pressure of air measured downstream of the compressor discharge side of the turbocharger.";
CM_ SG_ 2147548838 EngTurbo3BoostPress "Gage pressure of air measured downstream of the compressor discharge side of the turbocharger.";
CM_ SG_ 2147548838 EngTurbo2BoostPress "Gage pressure of air measured downstream of the compressor discharge side of the turbocharger.";
CM_ SG_ 2147548838 EngTurbo1BoostPress "Gage pressure of air measured downstream of the compressor discharge side of the turbocharger.";
CM_ BO_ 2147548624 "Inlet/Exhaust Conditions 2";
CM_ BO_ 2147548918 "Inlet/Exhaust Conditions 1";
CM_ SG_ 2147548918 EngExhaustGasTemp "Temperature of combustion byproducts leaving the engine.";
CM_ SG_ 2147548918 EngAirInletPress "Absolute air pressure at inlet to intake manifold or air box.";
CM_ SG_ 2147548918 EngIntakeManifold1Temp "Temperature of pre-combustion air found in intake manifold of engine air supply system.";
CM_ SG_ 2147548918 EngTurboBoostPress "Gage pressure of air measured downstream on the compressor discharge side of the turbocharger.";
CM_ SG_ 2147548918 EngParticulateTrapInletPress "Exhaust back pressure as a result of particle accumulation on filter media placed in the exhaust stream.";
CM_ BO_ 2147548781 "Heater Information";
CM_ SG_ 2147548781 CabHeatingZone "Parameter indicating whether the cab zone is being heated.";
CM_ SG_ 2147548781 EngHeatingZone "Parameter indicating whether the engine zone is being heated.";
CM_ SG_ 2147548781 CabVentilation "Indicates whether the cab is being ventilated or not.";
CM_ SG_ 2147548781 AuxHeaterOutputPowerPercent "Current auxiliary heater output power, relative to the auxiliary heater maximum output power.";
CM_ SG_ 2147548781 AuxHeaterInputAirTemp "Temperature of the input air in an auxiliary heater system.";
CM_ SG_ 2147548781 AuxHeaterOutputCoolantTemp "Temperature of the auxiliary heater output coolant (I.";
CM_ BO_ 2147548782 "High Resolution Wheel Speed";
CM_ SG_ 2147548782 RearAxleRightWheelSpeed "High resolution measurement of the speed of the right wheel on the rear axle.";
CM_ SG_ 2147548782 RearAxleLeftWheelSpeed "High resolution measurement of the speed of the left wheel on the rear axle.";
CM_ SG_ 2147548782 FrontAxleRightWheelSpeed "High resolution measurement of the speed of the right wheel on the front axle.";
CM_ SG_ 2147548782 FrontAxleLeftWheelSpeed "High resolution measurement of the speed of the left wheel on the front axle.";
CM_ BO_ 2147545096 "Hydraulic Pressure Governor Info";
CM_ SG_ 2147545096 EngHydPrssGovernorModeIndicator "Mode for governor operation is hydraulic pressure control.";
CM_ SG_ 2147545096 HydPress "Hydraulic pressure measured at the output of the hydraulic pump.";
CM_ BO_ 2147548901 "Engine Hours, Revolutions";
CM_ SG_ 2147548901 EngTotalRevolutions "Accumulated number of revolutions of engine crankshaft during its operation.";
CM_ SG_ 2147548901 EngTotalHoursOfOperation "Accumulated time of operation of engine.";
CM_ BO_ 2147548646 "Hydraulic Braking System";
CM_ SG_ 2147548646 HydBrakeFluidLevelSwitch "Signal which indicates whether the hydraulic fluid level in the reservoir(s) is sufficient.";
CM_ SG_ 2147548646 HydBrakeSystemAudibleWarningCmd "Signal which commands an audible warning by the hydraulic braking system.";
CM_ BO_ 2147548856 "Trip Fuel Information (Gaseous)";
CM_ SG_ 2147548856 TripCruiseFuelUsed "Total fuel consumed while the engine is in the cruise hold state since the last trip reset.";
CM_ BO_ 2147548811 "Gaseous Fuel Pressure";
CM_ SG_ 2147548811 EngAirToFuelDiffPress "The differential pressure between the gaseous fuel and the air intake manifold.";
CM_ SG_ 2147548811 EngFuelValveDiffPress "The differential pressure between the inlet and the outlet of a gaseous fuel valve.";
CM_ SG_ 2147548811 EngFuelValveInletAbsPress "The absolute pressure at the inlet of the gaseous fuel valve.";
CM_ BO_ 2147548801 "Fuel Information 2 (Gaseous)";
CM_ SG_ 2147548801 EngFuelFlowRate2 "The rate at which the fuel is flowing through a fuel valve.";
CM_ SG_ 2147548801 EngFuelFlowRate1 "The rate at which the fuel is flowing through a fuel valve.";
CM_ SG_ 2147548801 EngRqedFuelValve1Pos "The requested position of a gaseous fuel valve 1 that is metering the fuel flow to the engine.";
CM_ SG_ 2147548801 EngFuelValve2Pos "The position of a gaseous fuel valve that is metering the fuel flow to the engine.";
CM_ SG_ 2147548801 EngFuelValve1Pos "The position of a gaseous fuel valve that is metering the fuel flow to the engine.";
CM_ BO_ 2147548850 "Fuel Information 1 (Gaseous)";
CM_ SG_ 2147548850 EngFuelSpecificGravity "This parameter conveys the specific gravity of the gaseous fuel being used by the engine.";
CM_ SG_ 2147548850 TripAverageFuelRate "Average fuel rate, equal to trip fuel divided by trip time while the engine speed is above zero, since the last trip reset.";
CM_ SG_ 2147548850 TotalEngPTOFuelUsed "Total fuel used while the PTO or remote PTO is in the hold state and engine speed is above zero, over the life of the engine.";
CM_ BO_ 2147548757 "Gaseous Fuel Properties";
CM_ SG_ 2147548757 SpecificHeatRatio "The specific heat ratio of the fuel.";
CM_ BO_ 2147548847 "Fuel Consumption (Gaseous)";
CM_ BO_ 2147544320 "Used to access network interconnection ECU parametrics and database";
CM_ SG_ 2147544320 FilterMode "Filter mode for Network PG";
CM_ SG_ 2147544320 ToPort "Destination port for network PG";
CM_ SG_ 2147544320 FromPort "Source port for Network PG";
CM_ BO_ 2147484672 "External Brake Request";
CM_ SG_ 2147484672 ExtlAccelerationDemand "Parameter provided to the brake system from external sources.";
CM_ BO_ 2147548927 "Water in Fuel Indicator";
CM_ SG_ 2147548927 WaterInFuelIndicator "Signal which indicates the presence of water in the fuel.";
CM_ BO_ 2147548906 "Vehicle Weight";
CM_ SG_ 2147548906 CargoWeight "The mass of freight carried.";
CM_ SG_ 2147548906 TrailerWeight "Total mass of freight-carrying vehicle designed to be pulled by truck, including the weight of the contents.";
CM_ SG_ 2147548906 AxleWeight "Total mass imposed by the tires on the road surface at the specified axle.";
CM_ SG_ 2147548906 AxleLocation "To identify to which of several similar devices (such as tires or fuel tanks) the information applies.";
CM_ BO_ 2147548754 "Vehicle Electrical Power 3";
CM_ SG_ 2147548754 NetBatteryCurrentHiRes "Net flow of electrical current into/out-of the battery or batteries.";
CM_ SG_ 2147548754 AltCurrentHiRes "This parameter indicates the amount of electrical current output from the alternator of the main vehicle.";
CM_ BO_ 2147548813 "Vehicle Electrical Power 2";
CM_ SG_ 2147548813 Battery2Potential "The voltage for isolated battery #2.";
CM_ BO_ 2147548915 "Vehicle Position";
CM_ SG_ 2147548915 Longitude "Longitude position of the vehicle.";
CM_ SG_ 2147548915 Latitude "Latitude position of the vehicle.";
CM_ BO_ 2147548908 "Vehicle Identification";
CM_ BO_ 2147548903 "Vehicle Hours";
CM_ SG_ 2147548903 TotalPowerTakeoffHours "Accumulated time of operation of power takeoff device.";
CM_ SG_ 2147548903 TotalVehicleHours "Accumulated time of operation of vehicle.";
CM_ BO_ 2147548776 "Vehicle Fluids";
CM_ SG_ 2147548776 HydOilLevel "This parameter indicates the level of the hydraulic fluid in tank as a ratio of current volume to total tank volume.";
CM_ SG_ 2147548776 HydOilFilterRestrictionSwitch "This switch indicates whether hydraulic oil filter is clogged.";
CM_ SG_ 2147548776 HydTemp "Temperature of hydraulic fluid.";
CM_ BO_ 2147548919 "Vehicle Electrical Power";
CM_ SG_ 2147548919 NetBatteryCurrent "Net flow of electrical current into/out-of the battery or batteries.";
CM_ SG_ 2147548919 AltCurrent "This parameter indicates the amount of electrical current output from the alternator of the main vehicle.";
CM_ SG_ 2147548919 BatteryPotentialSwitched "Electrical potential measured at the input of the electronic control unit supplied through a switching device.";
CM_ SG_ 2147548919 ElectricalPotential "Measured electrical potential of the battery.";
CM_ SG_ 2147548919 AltPotential "Electrical potential measured at the alternator output.";
CM_ BO_ 2147548904 "Vehicle Direction/Speed";
CM_ SG_ 2147548904 Altitude "Altitude of the vehicle referenced to sea level at standard atmospheric pressure and temperature.";
CM_ SG_ 2147548904 Pitch "Pitch of the vehicle as calculated by the navigation device(s).";
CM_ SG_ 2147548904 NavigationBasedVehicleSpeed "Speed of the vehicle as calculated from a device such as a Global Positioning System (GPS).";
CM_ SG_ 2147548904 CompassBearing "Present compass bearing of vehicle.";
CM_ BO_ 2147548865 "High Resolution Vehicle Distance";
CM_ SG_ 2147548865 HighResolutionTripDistance "Distance traveled during all or part of a journey.";
CM_ SG_ 2147548865 HghRslutionTotalVehicleDistance "Accumulated distance traveled by the vehicle during its operation.";
CM_ BO_ 2147545097 "Vehicle Dynamic Stability Control 2";
CM_ SG_ 2147545097 LongitudinalAcceleration "Indicates the longitudinal acceleration of the vehicle.";
CM_ SG_ 2147545097 LateralAcceleration "Indicates a lateral acceleration of the vehicle.";
CM_ SG_ 2147545097 YawRate "Indicates the rotation about the vertical axis.";
CM_ SG_ 2147545097 SteerWheelTurnCounter "Indicates number of steering wheel turns, absolute position or relative position at ignition on.";
CM_ SG_ 2147545097 SteerWheelAngle "The main operator`s steering wheel angle (on the steering column, not the actual wheel angle).";
CM_ BO_ 2147548751 "Vehicle Dynamic Stability Control 1";
CM_ SG_ 2147548751 YCBrakeCtrlActive "State signal which indicates that Yaw Control (YC) has activated brake control.";
CM_ SG_ 2147548751 YCEngCtrlActive "State Signal which indicates that the Yaw Control (YC) has commanded engine control to be active.";
CM_ SG_ 2147548751 ROPBrakeCtrlActive "State signal which indicates that Roll over Prevention (ROP) has activated brake control.";
CM_ SG_ 2147548751 ROPEngCtrlActive "State Signal which indicates that the Roll Over Prevention (ROP) has commanded engine control to be active.";
CM_ SG_ 2147548751 VDCInformationSignal "This parameter commands the VDC information signal, for example a dash lamp.";
CM_ BO_ 2147548896 "Vehicle Distance";
CM_ SG_ 2147548896 TotalVehicleDistance "Accumulated distance traveled by vehicle during its operation.";
CM_ SG_ 2147548896 TripDistance "Distance traveled during all or part of a journey.";
CM_ BO_ 2147548854 "Trip Vehicle Speed/Cruise Distance Information";
CM_ BO_ 2147548848 "Trip Time Information 2";
CM_ SG_ 2147548848 TripAirCompressorOnTime "Total time that the air compressor is on and compressing air since the last trip reset.";
CM_ SG_ 2147548848 TripEngRunningTime "Total time accumulated while the engine speed is greater than zero since the last trip reset.";
CM_ SG_ 2147548848 TripPTOTime "Total time accumulated while the engine is in the PTO or remote PTO hold state since the last trip reset.";
CM_ BO_ 2147548852 "Trip Time Information 1";
CM_ SG_ 2147548852 TripTimeInTopGear "Total time accumulated when the vehicle has operated in top gear for a calibrated minimum time, since the last trip reset.";
CM_ BO_ 2147548853 "Trip Shutdown Information";
CM_ SG_ 2147548853 TrpNmberOfIdleShutdownOverrides "Total number of times an operator disables idle shutdown to prevent an engine shutdown, since the last trip reset.";
CM_ SG_ 2147548853 TripNumberOfHotShutdowns "Total number of hot shutdowns since the last trip reset.";
CM_ BO_ 2147483648 "Torque/Speed Control 1";
CM_ SG_ 2147483648 EngRqedTorque_TorqueLimit "Parameter provided to the engine or retarder in the torque/speed control message for controlling or limiting the output torque.";
CM_ SG_ 2147483648 EngRqedSpeed_SpeedLimit "Parameter provided to the engine from external sources in the torque/speed control message.";
CM_ SG_ 2147483648 EngRqedSpeedCtrlConditions "This mode tells the engine control system the governor characteristics that are desired during speed control.";
CM_ BO_ 2147548608 "Passenger Counter";
CM_ SG_ 2147548608 TransitRunStatus "Status of the run switch for the vehicle.";
CM_ SG_ 2147548608 VehicleUseStatus "Used to indicate the proper or unauthorized use of the vehicle.";
CM_ SG_ 2147548608 SilentAlarmStatus "Used to report silent alarm push button status.";
CM_ SG_ 2147548608 PatronCount "Count of the number of passengers on a transit vehicle.";
CM_ SG_ 2147548608 TypeOfPassengerCount "Used to notify transit link devices of the type of passenger counting system used in the vehicle.";
CM_ BO_ 2147548602 "Farebox Status";
CM_ SG_ 2147548602 FareboxAlarmIdentifier "Indicates the nature of the farebox alarm condition.";
CM_ SG_ 2147548602 FareboxEmergencyStatus "Indicates if a farebox emergency condition exists.";
CM_ BO_ 2147548603 "Farebox Point of Sale";
CM_ SG_ 2147548603 TransferSold "Indicates that a transfer was sold or issued on this transaction including its type and/or restrictions.";
CM_ SG_ 2147548603 RouteNumber "The route number issuing the transfer.";
CM_ SG_ 2147548603 PaymentDetails "Payment details.";
CM_ SG_ 2147548603 PassengerType "Enumerated value representing the type/class of passenger, as defined by the agency.";
CM_ BO_ 2147548604 "Farebox Service Detail";
CM_ SG_ 2147548604 DriversFareboxSecurityCode "Security code for the farebox, numerical only.";
CM_ SG_ 2147548604 AssignedRoute "The identity number assigned to this route.";
CM_ SG_ 2147548604 TripNumber "The identity number assigned to this trip.";
CM_ SG_ 2147548604 TripDirection "The general direction of travel for this trip.";
CM_ SG_ 2147548604 FareboxServiceStatus "Indicates if the farebox is in or out of service.";
CM_ BO_ 2147548605 "Signal Preemption";
CM_ SG_ 2147548605 VehicleID "Numerical designation of the vehicle.";
CM_ BO_ 2147548607 "Transit Milepost";
CM_ BO_ 2147548606 "Transit Route";
CM_ BO_ 2147528192 "Tire Pressure Reference Setting";
CM_ SG_ 2147528192 TireLocation "Identifies which tire is associated with the parametric data in this PGN.";
CM_ BO_ 2147548601 "Tire Pressure Reference Information";
CM_ SG_ 2147548601 TireLocation "Identifies which tire is associated with the parametric data in this PGN.";
CM_ BO_ 2147548794 "Tire Pressure Control Unit Current Pressures";
CM_ SG_ 2147548794 SteerChannelTirePress "The latest gage pressure reading of the steer group of tires, as opposed to the pressure in each tire.";
CM_ SG_ 2147548794 DriveChannelTirePress "The latest gage pressure reading of the drive group of tires, as opposed to the pressure in each tire.";
CM_ SG_ 2147548794 TrailerTagPushChannelTirePress "The latest gage pressure reading of the trailer, tag, or push group of tires, as opposed to the pressure in each tire.";
CM_ BO_ 2147548793 "Tire Pressure Control Unit Target Pressures";
CM_ SG_ 2147548793 SteerChannelTirePressTarget "The tire pressure control system’s target gage pressure for the steer group of tires.";
CM_ SG_ 2147548793 DriveChannelTirePressTarget "The tire pressure control system’s target gage pressure for the drive group of tires.";
CM_ SG_ 2147548793 TrlrTgPshChannelTirePressTarget "The tire pressure control system’s target gage pressure for the trailer, tag, or push group of tires.";
CM_ BO_ 2147548792 "Tire Pressure Control Unit Mode and Status";
CM_ SG_ 2147548792 PCUSupplySolenoidStatus "Current state of the supply solenoid used to implement a tire pressure control system in its pneumatic control unit (PCU).";
CM_ SG_ 2147548792 PCUCtrlSolenoidStatus "Current state of the control solenoid used to implement a tire pressure control system in its pneumatic control unit (PCU).";
CM_ SG_ 2147548792 PCUDeflateSolenoidStatus "Current state of the deflate solenoid used to implement a tire pressure control system in its pneumatic control unit (PCU).";
CM_ SG_ 2147548792 TirePressSupplySwitchStatus "Current state of an open/closed type switch used to determine if adequate pressure exists for system implementation.";
CM_ SG_ 2147548792 PCUSteerSolenoidStatus "Current state of the steer solenoid used to implement a tire pressure control system in its pneumatic control unit (PCU).";
CM_ SG_ 2147548792 PCUDriveSolenoidStatus "Current state of the drive solenoid used to implement a tire pressure control system in its pneumatic control unit (PCU).";
CM_ SG_ 2147548792 DriveChannelMode "Indicates the functional mode of trailer/tag channel of the tire pressure control system.";
CM_ SG_ 2147548792 Trailer_TagChannelMode "Indicates the functional mode of trailer/tag channel of the tire pressure control system.";
CM_ SG_ 2147548792 SteerChannelMode "Indicates the functional mode of steer channel of the tire pressure control system.";
CM_ SG_ 2147548792 TirePressCheckInterval "The interval at which the system will check the tire pressures (e.";
CM_ BO_ 2147548916 "Tire Condition";
CM_ SG_ 2147548916 TirePressThresholdDetection "Signal indicating the pressure level of the tire.";
CM_ SG_ 2147548916 TireAirLeakageRate "The pressure loss rate of a tire.";
CM_ SG_ 2147548916 CTIWheelEndElectricalFault "Indicates the status of electrical fault on CTI wheel interface.";
CM_ SG_ 2147548916 CTITireStatus "Indicates the status of the tire.";
CM_ SG_ 2147548916 CTIWheelSensorStatus "Indicates whether the wheel is being monitored by the CTI controller.";
CM_ SG_ 2147548916 TireTemp "Temperature at the surface of the tire sidewall.";
CM_ SG_ 2147548916 TirePress "Pressure at which air is contained in cavity formed by tire and rim.";
CM_ SG_ 2147548916 TireLocation "Identifies which tire is associated with the parametric data in this PGN.";
CM_ BO_ 2147548758 "Tank Information 1";
CM_ SG_ 2147548758 CatalystTankTemp "Temperature of the reagent in the storage tank.";
CM_ SG_ 2147548758 CatalystTankLevel "A special catalyst uses chemical substance to reach legal requirement for NOX emissions.";
CM_ BO_ 2147548859 "Trip Fan Information";
CM_ SG_ 2147548859 TripFanOnTimeDueToAManualSwitch "Total time the fan has been on due to manual activation by the operator (i.";
CM_ SG_ 2147548859 TripFanOnTime "Total time the fan has been on (due to an automatic trigger or manual trigger) since the last trip reset.";
CM_ SG_ 2147548859 TripFanOnTimeDueToA_CSystem "Total time the fan has been on due to the A/C system since the last trip reset.";
CM_ SG_ 2147548859 TripFanOnTimeDueToEngSystem "Total time the fan has been on due to engine triggers (i.";
CM_ BO_ 2147548920 "Transmission Fluids";
CM_ SG_ 2147548920 TransOilLevelHigh_Low "Amount of current volume of transmission sump oil compared to recommended volume.";
CM_ SG_ 2147548920 TransOilTemp "Temperature of the transmission lubricant.";
CM_ SG_ 2147548920 TransOilPress "Gage pressure of lubrication fluid in transmission, measured after pump.";
CM_ SG_ 2147548920 TransOilLevel "Ratio of volume of transmission sump oil to recommended volume.";
CM_ SG_ 2147548920 ClutchPress "Gage pressure of oil within a wet clutch.";
CM_ BO_ 2147548858 "Trip Distance Information";
CM_ SG_ 2147548858 TripDistanceInTopGear "Total distance accumulated while the vehicle has operated in top gear for a calibrated minimum time since the last trip reset.";
CM_ SG_ 2147548858 TripDistanceOnVSL "Total distance accumulated while the engine torque mode is road speed governing since the last trip reset.";
CM_ BO_ 2147538176 "Time/Date Adjust";
CM_ SG_ 2147538176 AdjustLocalMinuteOffset "Used to set the local offset in minutes from a reference time.";
CM_ SG_ 2147538176 AdjustYear "Part of a parameter used to set a calendar date.";
CM_ SG_ 2147538176 AdjustDay "Part of a parameter used to set a calendar date.";
CM_ SG_ 2147538176 AdjustMonth "Part of a parameter used to set a calendar date.";
CM_ SG_ 2147538176 AdjustHours "Part of the parameter used to set the time.";
CM_ SG_ 2147538176 AdjustMinutes "Part of the parameter used to set the time.";
CM_ SG_ 2147538176 AdjustSeconds "Part of the parameter used to set the time.";
CM_ BO_ 2147548902 "Time/Date";
CM_ SG_ 2147548902 LocalMinuteOffset "Local offset in minutes from a reference time.";
CM_ SG_ 2147548902 Year "Part of a parameter used to represent a calendar date.";
CM_ SG_ 2147548902 Day "Part of a parameter used to represent a calendar date.";
CM_ SG_ 2147548902 Month "Part of a parameter used to represent a calendar date.";
CM_ SG_ 2147548902 Hours "Part of a parameter used to represent time.";
CM_ SG_ 2147548902 Minutes "Part of a parameter used to represent time.";
CM_ SG_ 2147548902 Seconds "Part of a parameter used to represent time.";
CM_ BO_ 2147548822 "Turbocharger Wastegate";
CM_ SG_ 2147548822 EngTrbWstgtActuatorCtrlAirPress "Gage pressure of the air used to control the actuator which opens and closes the wastegate valve.";
CM_ SG_ 2147548822 EngTurbo4WastegateDrive "Position of the wastegate drive.";
CM_ SG_ 2147548822 EngTurbo3WastegateDrive "Position of the wastegate drive.";
CM_ SG_ 2147548822 EngTurbo2WastegateDrive "Position of the wastegate drive.";
CM_ SG_ 2147548822 EngTurbo1WastegateDrive "Position of the wastegate drive.";
CM_ BO_ 2147548780 "Tachograph";
CM_ SG_ 2147548780 TachographVehicleSpeed "Speed of the vehicle registered by the tachograph.";
CM_ SG_ 2147548780 TachographOutputShaftSpeed "Calculated speed of the transmission output shaft.";
CM_ SG_ 2147548780 DirectionIndicator "Indicates the direction of the vehicle.";
CM_ SG_ 2147548780 HandlingInformation "Indicates that handling information is present.";
CM_ SG_ 2147548780 SystemEvent "Indicates that a tachograph event has occurred.";
CM_ SG_ 2147548780 Driver2TimeRelatedStates "Indicates if the driver approaches or exceeds working time limits (or other limits).";
CM_ SG_ 2147548780 Overspeed "Indicates whether the vehicle is exceeding the legal speed limit set in the tachograph.";
CM_ SG_ 2147548780 Driver1TimeRelatedStates "Indicates if the driver approaches or exceeds working time limits (or other limits).";
CM_ SG_ 2147548780 DriveRecognize "Indicates whether motion of the vehicle is detected or not.";
CM_ SG_ 2147548780 Driver2WorkingState "State of work of the driver.";
CM_ SG_ 2147548780 Driver1WorkingState "State of work of the driver.";
CM_ BO_ 2147548627 "Turbocharger Information 6";
CM_ BO_ 2147548823 "Turbocharger Information 5";
CM_ SG_ 2147548823 EngTurbo4TurbineOutletTemp "Temperature of the combustion by-products exiting the turbine side of the turbocharger.";
CM_ SG_ 2147548823 EngTurbo3TurbineOutletTemp "Temperature of the combustion by-products exiting the turbine side of the turbocharger.";
CM_ SG_ 2147548823 EngTurbo2TurbineOutletTemp "Temperature of the combustion by-products exiting the turbine side of the turbocharger.";
CM_ SG_ 2147548823 EngTurbo1TurbineOutletTemp "Temperature of the combustion by-products exiting the turbine side of the turbocharger.";
CM_ BO_ 2147548824 "Turbocharger Information 4";
CM_ SG_ 2147548824 EngTurbo4TurbineInletTemp "Temperature of the combustion by-products entering the turbine side of the turbocharger.";
CM_ SG_ 2147548824 EngTurbo3TurbineInletTemp "Temperature of the combustion by-products entering the turbine side of the turbocharger.";
CM_ SG_ 2147548824 EngTurbo2TurbineInletTemp "Temperature of the combustion by-products entering the turbine side of the turbocharger.";
CM_ SG_ 2147548824 EngTurbo1TurbineInletTemp "Temperature of the combustion by-products entering the turbine side of the turbocharger.";
CM_ BO_ 2147548825 "Turbocharger Information 3";
CM_ SG_ 2147548825 EngTurbo4CompressorInletPress "Gage pressure of the air entering the compressor side of the turbocharger.";
CM_ SG_ 2147548825 EngTurbo3CompressorInletPress "Gage pressure of the air entering the compressor side of the turbocharger.";
CM_ SG_ 2147548825 EngTurbo2CompressorInletPress "Gage pressure of the air entering the compressor side of the turbocharger.";
CM_ SG_ 2147548825 EngTurbo1CompressorInletPress "Gage pressure of the air entering the compressor side of the turbocharger.";
CM_ BO_ 2147548826 "Turbocharger Information 2";
CM_ SG_ 2147548826 EngTurbo4CompressorInletTemp "Temperature of the air entering the compressor side of the turbocharger.";
CM_ SG_ 2147548826 EngTurbo3CompressorInletTemp "Temperature of the air entering the compressor side of the turbocharger.";
CM_ SG_ 2147548826 EngTurbo2CompressorInletTemp "Temperature of the air entering the compressor side of the turbocharger.";
CM_ SG_ 2147548826 EngTurbo1CompressorInletTemp "Temperature of the air entering the compressor side of the turbocharger.";
CM_ BO_ 2147548827 "Turbocharger Information 1";
CM_ SG_ 2147548827 EngTurbo4Speed "Rotational velocity of rotor in the turbocharger.";
CM_ SG_ 2147548827 EngTurbo3Speed "Rotational velocity of rotor in the turbocharger.";
CM_ SG_ 2147548827 EngTurbo2Speed "Rotational velocity of rotor in the turbocharger.";
CM_ SG_ 2147548827 EngTurboLubeOilPress2 "Gage pressure of oil in turbocharger lubrication system.";
CM_ BO_ 2147548747 "Transmission Configuration 2";
CM_ BO_ 2147548898 "Transmission Configuration";
CM_ SG_ 2147548898 NumberOfForwardGearRatios "Number of forward gear ratios in the transmission, provided as part of the configuration.";
CM_ SG_ 2147548898 NumberOfReverseGearRatios "Number of reverse gear ratios in the transmission, provided as part of the transmission configuration.";
CM_ BO_ 2147483904 "Transmission Control 1";
CM_ SG_ 2147483904 TrnsShftSlctorDisplayModeSwitch "Status of the operator’s switch used to ‘toggle’ through multiple display modes of a shift selector display.";
CM_ SG_ 2147483904 TransMode4 "Indicates whether transmission mode 4 is enabled.";
CM_ SG_ 2147483904 TransMode3 "Indicates whether transmission mode 3 is enabled.";
CM_ SG_ 2147483904 TransMode2 "Indicates whether transmission mode 2 is enabled.";
CM_ SG_ 2147483904 TransMode1 "Indicates whether transmission mode 1 is enabled.";
CM_ SG_ 2147483904 DisengageDiffLockRqCentralRear "Command signal used to disengage the various differential locks, e.";
CM_ SG_ 2147483904 DisengageDiffLockRqCentralFront "Command signal used to disengage the various differential locks, e.";
CM_ SG_ 2147483904 DisengageDiffLockRqCentral "Command signal used to disengage the various differential locks, e.";
CM_ SG_ 2147483904 DisengageDiffLockRqRearAxle2 "Command signal used to disengage the various differential locks, e.";
CM_ SG_ 2147483904 DisengageDiffLockRqRearAxle1 "Command signal used to disengage the various differential locks, e.";
CM_ SG_ 2147483904 DisengageDiffLockRqFrontAxle2 "Command signal used to disengage the various differential locks, e.";
CM_ SG_ 2147483904 DisengageDiffLockRqFrontAxle1 "Command signal used to disengage the various differential locks, e.";
CM_ SG_ 2147483904 TransRqedGear "Gear requested by the operator, ABS, or engine.";
CM_ SG_ 2147483904 RqedPercentClutchSlip "Parameter which represents the percent clutch slip requested by a device.";
CM_ SG_ 2147483904 DisengageDrivelineRq "Command signal used to simply disengage the driveline, e.";
CM_ SG_ 2147483904 TorqueConverterLockupDisableRq "Command signal to prevent torque converter lockup, which may cause problems in certain circumstances for ASR.";
CM_ SG_ 2147483904 TransGearShiftInhibitRq "Command signal to inhibit gear shifts.";
CM_ BO_ 2147548893 "Turbocharger";
CM_ SG_ 2147548893 EngTurbo1Speed "Rotational velocity of rotor in the turbocharger.";
CM_ SG_ 2147548893 EngTurboLubeOilPress1 "Gage pressure of oil in turbocharger lubrication system.";
CM_ BO_ 2147548749 "Total Averaged Information";
CM_ BO_ 2147548642 "Supply Pressure Demand";
CM_ SG_ 2147548642 AirSuspensionSupplyPressRq "Command signal to influence the pneumatic pressure in the circuit for the electronically controlled air suspension system.";
CM_ SG_ 2147548642 AuxEquipmentSupplyPressRq "Command signal to influence the pneumatic pressure in the auxiliary circuit.";
CM_ SG_ 2147548642 ServiceBrakeAirPressRqCircuit2 "Command signal to influence the pneumatic pressure in the service brake circuit or reservoir #2.";
CM_ SG_ 2147548642 ServiceBrakeAirPressRqCircuit1 "Command signal to influence the pneumatic pressure in the service brake circuit or reservoir #1.";
CM_ SG_ 2147548642 PneumaticSupplyPressRq "Command signal to influence the pneumatic pressure in the main reservoir.";
CM_ BO_ 2147548815 "Supply Pressure 2";
CM_ SG_ 2147548815 EngExtlShutdownAirSupplyPress "Pressure of the air used to shut off the fuel supply to the engine.";
CM_ BO_ 2147548890 "Software Identification";
CM_ SG_ 2147548890 NmbrOfSftwrIdentificationFields "Number of software identification designators represented in the software identification parameter group.";
CM_ BO_ 2147548900 "Shutdown";
CM_ SG_ 2147548900 EngOverspeedTest "The engine overspeed test signal as measured by the reporting ECM.";
CM_ SG_ 2147548900 EngAirShutoffCmdStatus "State signal which indicates when the Air Shutoff driver output is being driven.";
CM_ SG_ 2147548900 EngAlarmOutputCmdStatus "State signal which indicates when the Alarm driver output is being driven.";
CM_ SG_ 2147548900 EngAlarmAcknowledge "The Engine Alarm Acknowledge Input signal as measured by the reporting ECM.";
CM_ SG_ 2147548900 EngProtectionSystemConfig "Parameter which indicates the configuration of the engine shutdown system.";
CM_ SG_ 2147548900 EngProtectionSystemTimerState "Status signal which indicates the current mode of the engine protection system timer system.";
CM_ SG_ 2147548900 EngPrtectionSystemTimerOverride "Status signal which indicates the status of the override feature of the engine protection system timer.";
CM_ SG_ 2147548900 EngPrtctnSystmApprchingShutdown "Status signal which indicates that engine shutdown is imminent.";
CM_ SG_ 2147548900 EngPrtctionSystemHasShutdownEng "Status signal which indicates whether or not the engine protection system has shutdown the engine.";
CM_ SG_ 2147548900 RefrigerantHighPressSwitch "Switch signal which indicates the position of the high pressure switch in the coolant circuit of an air conditioning system.";
CM_ SG_ 2147548900 RefrigerantLowPressSwitch "Switch signal which indicates the position of the low pressure switch in the coolant circuit of an air conditioning system.";
CM_ SG_ 2147548900 EngIdleShutdownTimerFunction "Parameter which indicates the configuration of the idle shutdown timer system.";
CM_ SG_ 2147548900 EngIdleShutdownTimerState "Status signal which indicates the current mode of operation of the idle shutdown timer system.";
CM_ SG_ 2147548900 EngIdleShutdownTimerOverride "Status signal which indicates the status of the override feature of the idle shutdown timer system.";
CM_ SG_ 2147548900 EngIdleShutdownDriverAlertMode "Status signal which indicates the status of the driver alert mode of the idle shutdown timer system.";
CM_ SG_ 2147548900 EngIdleShutdownHasShutdownEng "Status signal which identifies whether or not the engine has been shutdown by the idle shutdown timer system.";
CM_ BO_ 2147548864 "Service Information";
CM_ SG_ 2147548864 ServiceComponentIdentificationB "Identification of component needing service.";
CM_ SG_ 2147548864 ServiceComponentIdentificationA "Identification of component needing service.";
CM_ SG_ 2147548864 SrvceDelay_OperationalTimeBased "The time in vehicle operational time until the next vehicle service inspection is required.";
CM_ SG_ 2147548864 ServiceDelay_CalendarTimeBased "The time in weeks until the next vehicle service inspection is required.";
CM_ SG_ 2147548864 ServiceDistance "The distance which can be traveled by the vehicle before the next service inspection is required.";
CM_ SG_ 2147548864 ServiceComponentIdentification "Identification of component needing service.Identification of component needing service.Identification of component needing service.";
CM_ BO_ 2147548814 "Service 2";
CM_ SG_ 2147548814 TimeSinceLastService "The vehicle operation time since the last service was performed.";
CM_ SG_ 2147548814 ServiceComponentIdentification "Identification of component needing service.Identification of component needing service.Identification of component needing service.";
CM_ BO_ 2147548755 "Retarder Continuous Torque & Speed Limit";
CM_ SG_ 2147548755 MaxContinuousRetarderTorque "Applied limit for maximum continuous retarder torque.";
CM_ SG_ 2147548755 HghLmtThrshhldFrMnCntnsTrqFrmRtr "Maximum allowable value for minimum continuous retarder torque.";
CM_ SG_ 2147548755 LwLmtThrshhldFrMxTrqFrmRetarder "Minimum allowable value for maximum continuous retarder torque.";
CM_ BO_ 2147548923 "Retarder fluids";
CM_ SG_ 2147548923 HydRetarderOilTemp "Temperature of oil found in a hydraulic retarder.";
CM_ SG_ 2147548923 HydRetarderPress "Gage pressure of oil in hydraulic retarder system.";
CM_ BO_ 2147540480 "Reset";
CM_ SG_ 2147540480 EngBuildHoursReset "Command signal used to reset the engine rebuild hours.";
CM_ SG_ 2147540480 ServiceComponentIdentification "Identification of component needing service.Identification of component needing service.Identification of component needing service.";
CM_ SG_ 2147540480 TripGroup2Proprietary "Command signal used to reset proprietary parameters associated with a trip but not defined within this document.";
CM_ SG_ 2147540480 TripGroup1 "Command signal used to reset the PGNs and parameters as defined in Table SPN988_A.";
CM_ BO_ 2147548897 "Retarder Configuration";
CM_ SG_ 2147548897 ReferenceRetarderTorque "This parameter is the 100% reference value for all defined indicated retarder torque parameters.";
CM_ SG_ 2147548897 RetarderSpeedAtPoint4 "Retarder speed of point 4 of the engine retarder torque map.";
CM_ SG_ 2147548897 RetarderSpeedAtPoint3 "Retarder speed of point 3 of the engine retarder torque map.";
CM_ SG_ 2147548897 PercentTorqueAtMaxSpeedPoint2 "The torque limit that indicates the available retarder torque which can be provided by the retarder at its maximum speed.";
CM_ SG_ 2147548897 MaxRetarderSpeedPoint2 "Maximum speed of retarder (Please reference PGN 65249).";
CM_ SG_ 2147548897 PercentTorqueAtIdlePoint1 "The torque limit that indicates the available retarder torque which can be provided by the retarder at idle speed.";
CM_ SG_ 2147548897 RetarderCtrlMethod "This parameter identifies the number of steps used by the retarder.";
CM_ SG_ 2147548897 RetarderType "A vehicle retarder is a supplementary device to the wheel brakes for the driver to better control the vehicle.";
CM_ BO_ 2147548821 "Rebuild Information";
CM_ SG_ 2147548821 EngOperationTimeSinceRebuild "The time in engine operation since the last engine rebuild.";
CM_ BO_ 2147548912 "Power Takeoff Information";
CM_ SG_ 2147548912 OperatorPTOMemorySelectSwitch "Measured state of the operator PTO memory select switch.";
CM_ SG_ 2147548912 EngPTOAccelerateSwitch "Switch signal of the PTO control activator which indicates that the activator is in the position \"accelerate\".";
CM_ SG_ 2147548912 EngPTOResumeSwitch "Switch signal of the PTO control activator which indicates that the activator is in the position \"resume\".";
CM_ SG_ 2147548912 EngPTOCoast_DecelerateSwitch "Switch signal of the PTO control activator which indicates that the activator is in the position \"coast/decelerate\".";
CM_ SG_ 2147548912 EngPTOSetSwitch "Switch signal of the PTO control activator which indicates that the activator is in the position \"set\".";
CM_ SG_ 2147548912 EngRmtPTOVriableSpeedCtrlSwitch "Switch signal which indicates that the remote PTO toggle switch is in the enabled (ON) position.";
CM_ SG_ 2147548912 EngRmtPTOPrprgrmmdSpdCtrlSwitch "Switch signal which indicates that the remote PTO toggle switch is in the enabled (ON) position.";
CM_ SG_ 2147548912 PowerTakeoffSetSpeed "Rotational velocity selected by operator for device used to transmit engine power to auxiliary equipment.";
CM_ SG_ 2147548912 PowerTakeoffSpeed "Rotational velocity of device used to transmit engine power to auxiliary equipment.";
CM_ SG_ 2147548912 PowerTakeoffOilTemp "Temperature of lubricant in device used to transmit engine power to auxiliary equipment.";
CM_ BO_ 2147548621 "Operator Wiper and Washer Controls Message";
CM_ SG_ 2147548621 RearWasherFunction "State of operation selected by operator switch for the rear washer.";
CM_ SG_ 2147548621 FrontOperatorWasherSwitch "State of operation selected by operator switch for the washer in front of the operator position.";
CM_ SG_ 2147548621 FrontNonoperatorWasherSwitch "State of operation selected by operator switch for the front washer not in front of the operator position.";
CM_ SG_ 2147548621 RearWiperDelayCtrl "Time between cycles of the rear wiper (i.";
CM_ SG_ 2147548621 FrontNonoperatorWiperDelayCtrl "Time between cycles of the front non-operator side wiper (i.";
CM_ SG_ 2147548621 FrontOperatorWiperDelayCtrl "Time between cycles of the front operator side wiper (i.";
CM_ SG_ 2147548621 RearWiperSwitch "State of operation selected by operator switch for the rear wiper.";
CM_ SG_ 2147548621 FrontOperatorWiperSwitch "State of operation selected by operator switch for the Wiper in front of the operator position.";
CM_ SG_ 2147548621 FrontNonoperatorWiperSwitch "State of operation selected by operator switch for the front wiper not in front of the operator position.";
CM_ BO_ 2147548619 "Off-Highway Engine Control Selection";
CM_ SG_ 2147548619 EngAltRatingSelect "In some off-highway applications it may be desirable to have multiple engine ratings available for selection by the operator.";
CM_ SG_ 2147548619 EngAltLowIdleSwitch "Operator switch which selects between two low idle speeds, default and alternate.";
CM_ SG_ 2147548619 EngSynchronizationSwitch "This is the On/Off operation of the Multiple Unit Synchronization functionality.";
CM_ SG_ 2147548619 EngAuxGovernorSwitch "This is the On/Off operation of the Auxiliary Governor feature switch.";
CM_ BO_ 2147548615 "Off-Highway Engine Control Selection States";
CM_ SG_ 2147548615 EngAltRatingSelectState "In some off-highway applications it may be desirable to have multiple engine ratings available for selection by the operator.";
CM_ SG_ 2147548615 EngAltLowIdleSelectState "In many applications, it is desirable that an alternate low idle speed setting be made available via switch input.";
CM_ SG_ 2147548615 EngMultiUnitSyncState "This feature is widely used in Industry to operate multiple engines from a single command source.";
CM_ SG_ 2147548615 EngAuxGovernorState "This is the Engine Auxiliary Governor feature.";
CM_ BO_ 2147548620 "Operators External Light Controls Message";
CM_ SG_ 2147548620 OprtrsDesiredDelayedLampOffTime "A 16 bit parameter to be associated with Delayed Off position (1000 binary) of the Main Light Switch.";
CM_ SG_ 2147548620 OperatorsDesiredBacklight "A 8 bit parameter to indicate the level of back lighting the operator has selected for displays.";
CM_ SG_ 2147548620 HighLowBeamSwitch "A 2 bit parameter to indicate the selected position of the operator's high/low beam select switch.";
CM_ SG_ 2147548620 HazardLightSwitch "A 2 bit parameter to indicate the selected position of the operator's hazard light switch.";
CM_ SG_ 2147548620 TurnSignalSwitch "A 4 bit parameter to indicate the selected position of the operator's turn signal switch.";
CM_ SG_ 2147548620 MainLightSwitch "A 4 bit parameter to indicate the selected position of the operator's main light switch.";
CM_ SG_ 2147548620 WorkLightSwitch "A 4 bit parameter to indicate the selected position of the operator's work light switch.";
CM_ BO_ 2147548645 "Maximum Vehicle Speed Limit Status";
CM_ SG_ 2147548645 AppliedVehicleSpeedLimit "The vehicle speed limit in effect.";
CM_ SG_ 2147548645 MaxVehicleSpeedLimit1 "The lowest Maximum Vehicle Speed Limit.";
CM_ BO_ 2147548748 "Military Lighting Command";
CM_ SG_ 2147548748 OprtrsBlckOutIntensitySelection "Operators Selection of lamp intensity in black out mode.";
BA_DEF_  "BusType" STRING ;
BA_DEF_ SG_  "SigType" STRING ;
BA_DEF_ SG_  "SPN" INT 0 524287;
BA_DEF_ BO_  "J1939PGPrio" INT 0 7;
BA_DEF_ BO_  "SingleFrame" INT 0 1;
BA_DEF_ BO_  "J1939PGRepetitionCycle" INT 0 1000000;
BA_DEF_ BO_  "J1939PGRepetitionType" ENUM  "always","when active","on request";
BA_DEF_  "J1939PGN" INT 0 1;
BA_DEF_DEF_  "BusType" "";
BA_DEF_DEF_  "SigType" "";
BA_DEF_DEF_  "SPN" 0;
BA_DEF_DEF_  "J1939PGPrio" 6;
BA_DEF_DEF_  "SingleFrame" 1;
BA_DEF_DEF_  "J1939PGRepetitionCycle" 0;
BA_DEF_DEF_  "J1939PGRepetitionType" "on request";
BA_DEF_DEF_  "J1939PGN" 0;
BA_ "J1939PGN" 1;
BA_ "BusType" "CAN";
BA_ "J1939PGRepetitionType" BO_ 2147548600 3;
BA_ "J1939PGPrio" BO_ 2147548855 7;
BA_ "J1939PGPrio" BO_ 2147548737 3;
BA_ "J1939PGPrio" BO_ 2147548786 3;
BA_ "J1939PGRepetitionCycle" BO_ 2147548786 50;
BA_ "J1939PGRepetitionType" BO_ 2147548786 0;
BA_ "J1939PGPrio" BO_ 2147548807 7;
BA_ "J1939PGPrio" BO_ 2147548806 7;
BA_ "J1939PGPrio" BO_ 2147548805 7;
BA_ "J1939PGPrio" BO_ 2147548804 7;
BA_ "J1939PGPrio" BO_ 2147548803 7;
BA_ "J1939PGPrio" BO_ 2147548802 7;
BA_ "J1939PGPrio" BO_ 2147548810 7;
BA_ "J1939PGPrio" BO_ 2147548809 7;
BA_ "J1939PGPrio" BO_ 2147548808 7;
BA_ "J1939PGRepetitionCycle" BO_ 2147548616 1000;
BA_ "J1939PGRepetitionType" BO_ 2147548616 0;
BA_ "J1939PGRepetitionCycle" BO_ 2147548618 1000;
BA_ "J1939PGRepetitionType" BO_ 2147548618 0;
BA_ "J1939PGPrio" BO_ 2147548837 7;
BA_ "J1939PGRepetitionCycle" BO_ 2147548837 1000;
BA_ "J1939PGRepetitionType" BO_ 2147548837 0;
BA_ "J1939PGRepetitionCycle" BO_ 2147548838 500;
BA_ "J1939PGRepetitionType" BO_ 2147548838 0;
BA_ "J1939PGRepetitionCycle" BO_ 2147548624 500;
BA_ "J1939PGRepetitionType" BO_ 2147548624 0;
BA_ "J1939PGRepetitionCycle" BO_ 2147548918 500;
BA_ "J1939PGRepetitionType" BO_ 2147548918 0;
BA_ "J1939PGRepetitionCycle" BO_ 2147548781 1000;
BA_ "J1939PGRepetitionType" BO_ 2147548781 0;
BA_ "J1939PGPrio" BO_ 2147548782 2;
BA_ "J1939PGRepetitionCycle" BO_ 2147548782 20;
BA_ "J1939PGRepetitionType" BO_ 2147548782 0;
BA_ "J1939PGRepetitionCycle" BO_ 2147545096 50;
BA_ "J1939PGRepetitionType" BO_ 2147545096 0;
BA_ "J1939PGPrio" BO_ 2147548646 3;
BA_ "J1939PGRepetitionCycle" BO_ 2147548646 100;
BA_ "J1939PGRepetitionType" BO_ 2147548646 0;
BA_ "J1939PGPrio" BO_ 2147548856 7;
BA_ "J1939PGPrio" BO_ 2147548811 7;
BA_ "J1939PGPrio" BO_ 2147548801 7;
BA_ "J1939PGPrio" BO_ 2147548850 7;
BA_ "J1939PGPrio" BO_ 2147548847 7;
BA_ "J1939PGPrio" BO_ 2147484672 3;
BA_ "J1939PGRepetitionCycle" BO_ 2147484672 20;
BA_ "J1939PGRepetitionType" BO_ 2147484672 1;
BA_ "J1939PGRepetitionCycle" BO_ 2147548927 10000;
BA_ "J1939PGRepetitionType" BO_ 2147548927 0;
BA_ "J1939PGRepetitionCycle" BO_ 2147548754 1000;
BA_ "J1939PGRepetitionType" BO_ 2147548754 0;
BA_ "J1939PGPrio" BO_ 2147548813 7;
BA_ "J1939PGRepetitionCycle" BO_ 2147548915 5000;
BA_ "J1939PGRepetitionType" BO_ 2147548915 0;
BA_ "J1939PGRepetitionCycle" BO_ 2147548776 1000;
BA_ "J1939PGRepetitionType" BO_ 2147548776 0;
BA_ "J1939PGRepetitionCycle" BO_ 2147548919 1000;
BA_ "J1939PGRepetitionType" BO_ 2147548919 0;
BA_ "J1939PGRepetitionCycle" BO_ 2147548865 1000;
BA_ "J1939PGRepetitionType" BO_ 2147548865 0;
BA_ "J1939PGRepetitionCycle" BO_ 2147545097 10;
BA_ "J1939PGRepetitionType" BO_ 2147545097 0;
BA_ "J1939PGRepetitionCycle" BO_ 2147548751 100;
BA_ "J1939PGRepetitionType" BO_ 2147548751 0;
BA_ "J1939PGRepetitionCycle" BO_ 2147548896 100;
BA_ "J1939PGRepetitionType" BO_ 2147548896 0;
BA_ "J1939PGPrio" BO_ 2147548854 7;
BA_ "J1939PGPrio" BO_ 2147548848 7;
BA_ "J1939PGPrio" BO_ 2147548852 7;
BA_ "J1939PGPrio" BO_ 2147548853 7;
BA_ "J1939PGPrio" BO_ 2147483648 3;
BA_ "J1939PGPrio" BO_ 2147548794 7;
BA_ "J1939PGPrio" BO_ 2147548793 7;
BA_ "J1939PGPrio" BO_ 2147548792 7;
BA_ "J1939PGRepetitionCycle" BO_ 2147548916 10000;
BA_ "J1939PGRepetitionType" BO_ 2147548916 0;
BA_ "J1939PGRepetitionCycle" BO_ 2147548758 1000;
BA_ "J1939PGRepetitionType" BO_ 2147548758 0;
BA_ "J1939PGPrio" BO_ 2147548859 7;
BA_ "J1939PGRepetitionCycle" BO_ 2147548920 1000;
BA_ "J1939PGRepetitionType" BO_ 2147548920 0;
BA_ "J1939PGPrio" BO_ 2147548858 7;
BA_ "J1939PGRepetitionCycle" BO_ 2147548822 100;
BA_ "J1939PGRepetitionType" BO_ 2147548822 0;
BA_ "J1939PGPrio" BO_ 2147548780 3;
BA_ "J1939PGRepetitionCycle" BO_ 2147548780 50;
BA_ "J1939PGRepetitionType" BO_ 2147548780 0;
BA_ "J1939PGRepetitionCycle" BO_ 2147548627 1000;
BA_ "J1939PGRepetitionType" BO_ 2147548627 0;
BA_ "J1939PGRepetitionCycle" BO_ 2147548823 1000;
BA_ "J1939PGRepetitionType" BO_ 2147548823 0;
BA_ "J1939PGRepetitionCycle" BO_ 2147548824 1000;
BA_ "J1939PGRepetitionType" BO_ 2147548824 0;
BA_ "J1939PGRepetitionCycle" BO_ 2147548825 1000;
BA_ "J1939PGRepetitionType" BO_ 2147548825 0;
BA_ "J1939PGRepetitionCycle" BO_ 2147548826 1000;
BA_ "J1939PGRepetitionType" BO_ 2147548826 0;
BA_ "J1939PGPrio" BO_ 2147548827 7;
BA_ "J1939PGRepetitionCycle" BO_ 2147548827 1000;
BA_ "J1939PGRepetitionType" BO_ 2147548827 0;
BA_ "J1939PGPrio" BO_ 2147483904 3;
BA_ "J1939PGRepetitionCycle" BO_ 2147548893 1000;
BA_ "J1939PGRepetitionType" BO_ 2147548893 0;
BA_ "J1939PGPrio" BO_ 2147548749 7;
BA_ "J1939PGRepetitionCycle" BO_ 2147548642 1000;
BA_ "J1939PGRepetitionType" BO_ 2147548642 1;
BA_ "J1939PGRepetitionCycle" BO_ 2147548815 1000;
BA_ "J1939PGRepetitionType" BO_ 2147548815 0;
BA_ "J1939PGRepetitionCycle" BO_ 2147548900 1000;
BA_ "J1939PGRepetitionType" BO_ 2147548900 0;
BA_ "J1939PGPrio" BO_ 2147548814 7;
BA_ "J1939PGRepetitionCycle" BO_ 2147548755 5000;
BA_ "J1939PGRepetitionType" BO_ 2147548755 0;
BA_ "J1939PGRepetitionCycle" BO_ 2147548923 1000;
BA_ "J1939PGRepetitionType" BO_ 2147548923 0;
BA_ "J1939PGPrio" BO_ 2147540480 7;
BA_ "J1939PGPrio" BO_ 2147548821 7;
BA_ "J1939PGRepetitionCycle" BO_ 2147548912 100;
BA_ "J1939PGRepetitionType" BO_ 2147548912 0;
BA_ "J1939PGRepetitionCycle" BO_ 2147548621 200;
BA_ "J1939PGRepetitionType" BO_ 2147548621 0;
BA_ "J1939PGRepetitionCycle" BO_ 2147548619 500;
BA_ "J1939PGRepetitionType" BO_ 2147548619 0;
BA_ "J1939PGRepetitionCycle" BO_ 2147548615 500;
BA_ "J1939PGRepetitionType" BO_ 2147548615 0;
BA_ "J1939PGPrio" BO_ 2147548620 3;
BA_ "J1939PGRepetitionCycle" BO_ 2147548645 1000;
BA_ "J1939PGRepetitionType" BO_ 2147548645 0;
BA_ "J1939PGRepetitionCycle" BO_ 2147548748 500;
BA_ "J1939PGRepetitionType" BO_ 2147548748 0;
BA_ "SPN" SG_ 2147548600 NonContMonSysCompleteStatus 3154;
BA_ "SPN" SG_ 2147548600 NonContMonSysEnableStatus 3153;
BA_ "SPN" SG_ 2147548600 ContMonitoredSysEnableStatus 3153;
BA_ "SigType" SG_ 2147548600 NumberOfWarmUps "RANGE";
BA_ "SPN" SG_ 2147548600 NumberOfWarmUps 3151;
BA_ "SigType" SG_ 2147548600 TimeSinceEngineStart "RANGE";
BA_ "SPN" SG_ 2147548600 TimeSinceEngineStart 3150;
BA_ "SPN" SG_ 2147537920 SecurityEntityType 1479;
BA_ "SigType" SG_ 2147537920 SecurityEntityLength "RANGE";
BA_ "SPN" SG_ 2147537920 SecurityEntityLength 1596;
BA_ "SigType" SG_ 2147548855 TotalEngCruiseTime "RANGE";
BA_ "SPN" SG_ 2147548855 TotalEngCruiseTime 1017;
BA_ "SigType" SG_ 2147548855 TotalDriveAverageLoadFactor "RANGE";
BA_ "SPN" SG_ 2147548855 TotalDriveAverageLoadFactor 1016;
BA_ "SigType" SG_ 2147548855 TripDriveAverageLoadFactor "RANGE";
BA_ "SPN" SG_ 2147548855 TripDriveAverageLoadFactor 1015;
BA_ "SigType" SG_ 2147548855 TripAverageEngSpeed "RANGE";
BA_ "SPN" SG_ 2147548855 TripAverageEngSpeed 1014;
BA_ "SigType" SG_ 2147548855 TripMaxEngSpeed "RANGE";
BA_ "SPN" SG_ 2147548855 TripMaxEngSpeed 1013;
BA_ "SigType" SG_ 2147548736 ImplementRearWorkLight "DISCRETE";
BA_ "SPN" SG_ 2147548736 ImplementRearWorkLight 2394;
BA_ "SigType" SG_ 2147548736 ImplementLeftForwardWorkLight "DISCRETE";
BA_ "SPN" SG_ 2147548736 ImplementLeftForwardWorkLight 2400;
BA_ "SigType" SG_ 2147548736 ImplementRightForwardWorkLight "DISCRETE";
BA_ "SPN" SG_ 2147548736 ImplementRightForwardWorkLight 2402;
BA_ "SigType" SG_ 2147548736 ImplementLeftFacingWorkLight "DISCRETE";
BA_ "SPN" SG_ 2147548736 ImplementLeftFacingWorkLight 2598;
BA_ "SigType" SG_ 2147548736 ImplementRightFacingWorkLight "DISCRETE";
BA_ "SPN" SG_ 2147548736 ImplementRightFacingWorkLight 2407;
BA_ "SigType" SG_ 2147548736 ImplementOEMOption1Light "DISCRETE";
BA_ "SPN" SG_ 2147548736 ImplementOEMOption1Light 2396;
BA_ "SigType" SG_ 2147548736 ImplementOEMOption2Light "DISCRETE";
BA_ "SPN" SG_ 2147548736 ImplementOEMOption2Light 2398;
BA_ "SigType" SG_ 2147548736 TrctrFrontHighMountedWorkLights "DISCRETE";
BA_ "SPN" SG_ 2147548736 TrctrFrontHighMountedWorkLights 2356;
BA_ "SigType" SG_ 2147548736 TrctorFrontLowMountedWorkLights "DISCRETE";
BA_ "SPN" SG_ 2147548736 TrctorFrontLowMountedWorkLights 2354;
BA_ "SigType" SG_ 2147548736 TrctorSideHighMountedWorkLights "DISCRETE";
BA_ "SPN" SG_ 2147548736 TrctorSideHighMountedWorkLights 2366;
BA_ "SigType" SG_ 2147548736 TractorSideLowMountedWorkLights "DISCRETE";
BA_ "SPN" SG_ 2147548736 TractorSideLowMountedWorkLights 2364;
BA_ "SigType" SG_ 2147548736 TrctorRearHighMountedWorkLights "DISCRETE";
BA_ "SPN" SG_ 2147548736 TrctorRearHighMountedWorkLights 2362;
BA_ "SigType" SG_ 2147548736 TractorRearLowMountedWorkLights "DISCRETE";
BA_ "SPN" SG_ 2147548736 TractorRearLowMountedWorkLights 2360;
BA_ "SigType" SG_ 2147548736 TrctrUndersideMountedWorkLights "DISCRETE";
BA_ "SPN" SG_ 2147548736 TrctrUndersideMountedWorkLights 2358;
BA_ "SigType" SG_ 2147548736 RearFogLights "DISCRETE";
BA_ "SPN" SG_ 2147548736 RearFogLights 2390;
BA_ "SigType" SG_ 2147548736 TractorMarkerLight "DISCRETE";
BA_ "SPN" SG_ 2147548736 TractorMarkerLight 2378;
BA_ "SigType" SG_ 2147548736 ImplementMarkerLight "DISCRETE";
BA_ "SPN" SG_ 2147548736 ImplementMarkerLight 2380;
BA_ "SigType" SG_ 2147548736 TractorClearanceLight "DISCRETE";
BA_ "SPN" SG_ 2147548736 TractorClearanceLight 2382;
BA_ "SigType" SG_ 2147548736 ImplementClearanceLight "DISCRETE";
BA_ "SPN" SG_ 2147548736 ImplementClearanceLight 2384;
BA_ "SigType" SG_ 2147548736 LeftStopLight "DISCRETE";
BA_ "SPN" SG_ 2147548736 LeftStopLight 2372;
BA_ "SigType" SG_ 2147548736 RightStopLight "DISCRETE";
BA_ "SPN" SG_ 2147548736 RightStopLight 2374;
BA_ "SigType" SG_ 2147548736 CenterStopLight "DISCRETE";
BA_ "SPN" SG_ 2147548736 CenterStopLight 2376;
BA_ "SigType" SG_ 2147548736 BackUpLightAndAlarmHorn "DISCRETE";
BA_ "SPN" SG_ 2147548736 BackUpLightAndAlarmHorn 2392;
BA_ "SigType" SG_ 2147548736 LeftTurnSignalLights "DISCRETE";
BA_ "SPN" SG_ 2147548736 LeftTurnSignalLights 2368;
BA_ "SigType" SG_ 2147548736 RightTurnSignalLights "DISCRETE";
BA_ "SPN" SG_ 2147548736 RightTurnSignalLights 2370;
BA_ "SigType" SG_ 2147548736 RotatingBeaconLight "DISCRETE";
BA_ "SPN" SG_ 2147548736 RotatingBeaconLight 2386;
BA_ "SigType" SG_ 2147548736 TractorFrontFogLights "DISCRETE";
BA_ "SPN" SG_ 2147548736 TractorFrontFogLights 2388;
BA_ "SigType" SG_ 2147548736 HighBeamHeadLightData "DISCRETE";
BA_ "SPN" SG_ 2147548736 HighBeamHeadLightData 2348;
BA_ "SigType" SG_ 2147548736 LowBeamHeadLightData "DISCRETE";
BA_ "SPN" SG_ 2147548736 LowBeamHeadLightData 2350;
BA_ "SigType" SG_ 2147548736 AltBeamHeadLightData "DISCRETE";
BA_ "SPN" SG_ 2147548736 AltBeamHeadLightData 2352;
BA_ "SigType" SG_ 2147548736 RunningLight "DISCRETE";
BA_ "SPN" SG_ 2147548736 RunningLight 2404;
BA_ "SigType" SG_ 2147548737 ImplementRearWorkLightCmd "DISCRETE";
BA_ "SPN" SG_ 2147548737 ImplementRearWorkLightCmd 2405;
BA_ "SigType" SG_ 2147548737 ImplmentLeftForwardWorkLightCmd "DISCRETE";
BA_ "SPN" SG_ 2147548737 ImplmentLeftForwardWorkLightCmd 2399;
BA_ "SigType" SG_ 2147548737 ImplmntRightForwardWorkLightCmd "DISCRETE";
BA_ "SPN" SG_ 2147548737 ImplmntRightForwardWorkLightCmd 2401;
BA_ "SigType" SG_ 2147548737 LightingDataRqCmd "DISCRETE";
BA_ "SPN" SG_ 2147548737 LightingDataRqCmd 2393;
BA_ "SigType" SG_ 2147548737 ImplementLeftFacingWorkLightCmd "DISCRETE";
BA_ "SPN" SG_ 2147548737 ImplementLeftFacingWorkLightCmd 2597;
BA_ "SigType" SG_ 2147548737 ImplmentRightFacingWorkLightCmd "DISCRETE";
BA_ "SPN" SG_ 2147548737 ImplmentRightFacingWorkLightCmd 2406;
BA_ "SigType" SG_ 2147548737 ImplementOEMOption1LightCmd "DISCRETE";
BA_ "SPN" SG_ 2147548737 ImplementOEMOption1LightCmd 2395;
BA_ "SigType" SG_ 2147548737 ImplementOEMOption2LightCmd "DISCRETE";
BA_ "SPN" SG_ 2147548737 ImplementOEMOption2LightCmd 2397;
BA_ "SigType" SG_ 2147548737 TrctrFrntHghMuntedWorkLightsCmd "DISCRETE";
BA_ "SPN" SG_ 2147548737 TrctrFrntHghMuntedWorkLightsCmd 2355;
BA_ "SigType" SG_ 2147548737 TrctrFrntLwMountedWorkLightsCmd "DISCRETE";
BA_ "SPN" SG_ 2147548737 TrctrFrntLwMountedWorkLightsCmd 2353;
BA_ "SigType" SG_ 2147548737 TrctrSdHighMountedWorkLightsCmd "DISCRETE";
BA_ "SPN" SG_ 2147548737 TrctrSdHighMountedWorkLightsCmd 2365;
BA_ "SigType" SG_ 2147548737 TrctrSdeLowMountedWorkLightsCmd "DISCRETE";
BA_ "SPN" SG_ 2147548737 TrctrSdeLowMountedWorkLightsCmd 2363;
BA_ "SigType" SG_ 2147548737 TrctrRrHighMountedWorkLightsCmd "DISCRETE";
BA_ "SPN" SG_ 2147548737 TrctrRrHighMountedWorkLightsCmd 2361;
BA_ "SigType" SG_ 2147548737 TrctrRarLowMountedWorkLightsCmd "DISCRETE";
BA_ "SPN" SG_ 2147548737 TrctrRarLowMountedWorkLightsCmd 2359;
BA_ "SigType" SG_ 2147548737 TrctrUndrsdMountedWorkLightsCmd "DISCRETE";
BA_ "SPN" SG_ 2147548737 TrctrUndrsdMountedWorkLightsCmd 2357;
BA_ "SigType" SG_ 2147548737 RearFogLightCmd "DISCRETE";
BA_ "SPN" SG_ 2147548737 RearFogLightCmd 2389;
BA_ "SigType" SG_ 2147548737 TractorMarkerLightCmd "DISCRETE";
BA_ "SPN" SG_ 2147548737 TractorMarkerLightCmd 2377;
BA_ "SigType" SG_ 2147548737 ImplementMarkerLightCmd "DISCRETE";
BA_ "SPN" SG_ 2147548737 ImplementMarkerLightCmd 2379;
BA_ "SigType" SG_ 2147548737 TractorClearanceLightCmd "DISCRETE";
BA_ "SPN" SG_ 2147548737 TractorClearanceLightCmd 2381;
BA_ "SigType" SG_ 2147548737 ImplementClearanceLightCmd "DISCRETE";
BA_ "SPN" SG_ 2147548737 ImplementClearanceLightCmd 2383;
BA_ "SigType" SG_ 2147548737 LeftStopLightCmd "DISCRETE";
BA_ "SPN" SG_ 2147548737 LeftStopLightCmd 2371;
BA_ "SigType" SG_ 2147548737 RightStopLightCmd "DISCRETE";
BA_ "SPN" SG_ 2147548737 RightStopLightCmd 2373;
BA_ "SigType" SG_ 2147548737 CenterStopLightCmd "DISCRETE";
BA_ "SPN" SG_ 2147548737 CenterStopLightCmd 2375;
BA_ "SigType" SG_ 2147548737 BackUpLightAndAlarmHornCmd "DISCRETE";
BA_ "SPN" SG_ 2147548737 BackUpLightAndAlarmHornCmd 2391;
BA_ "SigType" SG_ 2147548737 LeftTurnSignalLightsCmd "DISCRETE";
BA_ "SPN" SG_ 2147548737 LeftTurnSignalLightsCmd 2367;
BA_ "SigType" SG_ 2147548737 RightTurnSignalLightsCmd "DISCRETE";
BA_ "SPN" SG_ 2147548737 RightTurnSignalLightsCmd 2369;
BA_ "SigType" SG_ 2147548737 RotatingBeaconLightCmd "DISCRETE";
BA_ "SPN" SG_ 2147548737 RotatingBeaconLightCmd 2385;
BA_ "SigType" SG_ 2147548737 TractorFrontFogLightsCmd "DISCRETE";
BA_ "SPN" SG_ 2147548737 TractorFrontFogLightsCmd 2387;
BA_ "SigType" SG_ 2147548737 HighBeamHeadLightCmd "DISCRETE";
BA_ "SPN" SG_ 2147548737 HighBeamHeadLightCmd 2347;
BA_ "SigType" SG_ 2147548737 LowBeamHeadLightCmd "DISCRETE";
BA_ "SPN" SG_ 2147548737 LowBeamHeadLightCmd 2349;
BA_ "SigType" SG_ 2147548737 AltBeamHeadLightCmd "DISCRETE";
BA_ "SPN" SG_ 2147548737 AltBeamHeadLightCmd 2351;
BA_ "SigType" SG_ 2147548737 RunningLightCmd "DISCRETE";
BA_ "SPN" SG_ 2147548737 RunningLightCmd 2403;
BA_ "SigType" SG_ 2147548786 BladeCtrlMode "RANGE";
BA_ "SPN" SG_ 2147548786 BladeCtrlMode 1578;
BA_ "SigType" SG_ 2147548786 BladeDurationAndDirection "RANGE";
BA_ "SPN" SG_ 2147548786 BladeDurationAndDirection 1577;
BA_ "SigType" SG_ 2147548807 EngActualIgntTiming "RANGE";
BA_ "SPN" SG_ 2147548807 EngActualIgntTiming 1436;
BA_ "SigType" SG_ 2147548807 EngDesiredIgntTiming3 "RANGE";
BA_ "SPN" SG_ 2147548807 EngDesiredIgntTiming3 1435;
BA_ "SigType" SG_ 2147548807 EngDesiredIgntTiming2 "RANGE";
BA_ "SPN" SG_ 2147548807 EngDesiredIgntTiming2 1434;
BA_ "SigType" SG_ 2147548807 EngDesiredIgntTiming1 "RANGE";
BA_ "SPN" SG_ 2147548807 EngDesiredIgntTiming1 1433;
BA_ "SigType" SG_ 2147548806 EngCyl20IgntTiming "RANGE";
BA_ "SPN" SG_ 2147548806 EngCyl20IgntTiming 1432;
BA_ "SigType" SG_ 2147548806 EngCyl19IgntTiming "RANGE";
BA_ "SPN" SG_ 2147548806 EngCyl19IgntTiming 1431;
BA_ "SigType" SG_ 2147548806 EngCyl18IgntTiming "RANGE";
BA_ "SPN" SG_ 2147548806 EngCyl18IgntTiming 1430;
BA_ "SigType" SG_ 2147548806 EngCyl17IgntTiming "RANGE";
BA_ "SPN" SG_ 2147548806 EngCyl17IgntTiming 1429;
BA_ "SigType" SG_ 2147548805 EngCyl16IgntTiming "RANGE";
BA_ "SPN" SG_ 2147548805 EngCyl16IgntTiming 1428;
BA_ "SigType" SG_ 2147548805 EngCyl15IgntTiming "RANGE";
BA_ "SPN" SG_ 2147548805 EngCyl15IgntTiming 1427;
BA_ "SigType" SG_ 2147548805 EngCyl14IgntTiming "RANGE";
BA_ "SPN" SG_ 2147548805 EngCyl14IgntTiming 1426;
BA_ "SigType" SG_ 2147548805 EngCyl13IgntTiming "RANGE";
BA_ "SPN" SG_ 2147548805 EngCyl13IgntTiming 1425;
BA_ "SigType" SG_ 2147548804 EngCyl12IgntTiming "RANGE";
BA_ "SPN" SG_ 2147548804 EngCyl12IgntTiming 1424;
BA_ "SigType" SG_ 2147548804 EngCyl11IgntTiming "RANGE";
BA_ "SPN" SG_ 2147548804 EngCyl11IgntTiming 1423;
BA_ "SigType" SG_ 2147548804 EngCyl10IgntTiming "RANGE";
BA_ "SPN" SG_ 2147548804 EngCyl10IgntTiming 1422;
BA_ "SigType" SG_ 2147548804 EngCyl9IgntTiming "RANGE";
BA_ "SPN" SG_ 2147548804 EngCyl9IgntTiming 1421;
BA_ "SigType" SG_ 2147548803 EngCyl8IgntTiming "RANGE";
BA_ "SPN" SG_ 2147548803 EngCyl8IgntTiming 1420;
BA_ "SigType" SG_ 2147548803 EngCyl7IgntTiming "RANGE";
BA_ "SPN" SG_ 2147548803 EngCyl7IgntTiming 1419;
BA_ "SigType" SG_ 2147548803 EngCyl6IgntTiming "RANGE";
BA_ "SPN" SG_ 2147548803 EngCyl6IgntTiming 1418;
BA_ "SigType" SG_ 2147548803 EngCyl5IgntTiming "RANGE";
BA_ "SPN" SG_ 2147548803 EngCyl5IgntTiming 1417;
BA_ "SigType" SG_ 2147548802 EngCyl4IgntTiming "RANGE";
BA_ "SPN" SG_ 2147548802 EngCyl4IgntTiming 1416;
BA_ "SigType" SG_ 2147548802 EngCyl3IgntTiming "RANGE";
BA_ "SPN" SG_ 2147548802 EngCyl3IgntTiming 1415;
BA_ "SigType" SG_ 2147548802 EngCyl2IgntTiming "RANGE";
BA_ "SPN" SG_ 2147548802 EngCyl2IgntTiming 1414;
BA_ "SigType" SG_ 2147548802 EngCyl1IgntTiming "RANGE";
BA_ "SPN" SG_ 2147548802 EngCyl1IgntTiming 1413;
BA_ "SigType" SG_ 2147548810 EngCyl20IgntTransSecondOutput "RANGE";
BA_ "SPN" SG_ 2147548810 EngCyl20IgntTransSecondOutput 1412;
BA_ "SigType" SG_ 2147548810 EngCyl19IgntTransSecondOutput "RANGE";
BA_ "SPN" SG_ 2147548810 EngCyl19IgntTransSecondOutput 1411;
BA_ "SigType" SG_ 2147548810 EngCyl18IgntTransSecondOutput "RANGE";
BA_ "SPN" SG_ 2147548810 EngCyl18IgntTransSecondOutput 1410;
BA_ "SigType" SG_ 2147548810 EngCyl17IgntTransSecondOutput "RANGE";
BA_ "SPN" SG_ 2147548810 EngCyl17IgntTransSecondOutput 1409;
BA_ "SigType" SG_ 2147548809 EngCyl16IgntTransSecondOutput "RANGE";
BA_ "SPN" SG_ 2147548809 EngCyl16IgntTransSecondOutput 1408;
BA_ "SigType" SG_ 2147548809 EngCyl15IgntTransSecondOutput "RANGE";
BA_ "SPN" SG_ 2147548809 EngCyl15IgntTransSecondOutput 1407;
BA_ "SigType" SG_ 2147548809 EngCyl14IgntTransSecondOutput "RANGE";
BA_ "SPN" SG_ 2147548809 EngCyl14IgntTransSecondOutput 1406;
BA_ "SigType" SG_ 2147548809 EngCyl13IgntTransSecondOutput "RANGE";
BA_ "SPN" SG_ 2147548809 EngCyl13IgntTransSecondOutput 1405;
BA_ "SigType" SG_ 2147548809 EngCyl12IgntTransSecondOutput "RANGE";
BA_ "SPN" SG_ 2147548809 EngCyl12IgntTransSecondOutput 1404;
BA_ "SigType" SG_ 2147548809 EngCyl11IgntTransSecondOutput "RANGE";
BA_ "SPN" SG_ 2147548809 EngCyl11IgntTransSecondOutput 1403;
BA_ "SigType" SG_ 2147548809 EngCyl10IgntTransSecondOutput "RANGE";
BA_ "SPN" SG_ 2147548809 EngCyl10IgntTransSecondOutput 1402;
BA_ "SigType" SG_ 2147548809 EngCyl9IgntTransSecondOutput "RANGE";
BA_ "SPN" SG_ 2147548809 EngCyl9IgntTransSecondOutput 1401;
BA_ "SigType" SG_ 2147548808 EngCyl8IgntTransSecondOutput "RANGE";
BA_ "SPN" SG_ 2147548808 EngCyl8IgntTransSecondOutput 1400;
BA_ "SigType" SG_ 2147548808 EngCyl7IgntTransSecondOutput "RANGE";
BA_ "SPN" SG_ 2147548808 EngCyl7IgntTransSecondOutput 1399;
BA_ "SigType" SG_ 2147548808 EngCyl6IgntTransSecondOutput "RANGE";
BA_ "SPN" SG_ 2147548808 EngCyl6IgntTransSecondOutput 1398;
BA_ "SigType" SG_ 2147548808 EngCyl5IgntTransSecondOutput "RANGE";
BA_ "SPN" SG_ 2147548808 EngCyl5IgntTransSecondOutput 1397;
BA_ "SigType" SG_ 2147548808 EngCyl4IgntTransSecondOutput "RANGE";
BA_ "SPN" SG_ 2147548808 EngCyl4IgntTransSecondOutput 1396;
BA_ "SigType" SG_ 2147548808 EngCyl3IgntTransSecondOutput "RANGE";
BA_ "SPN" SG_ 2147548808 EngCyl3IgntTransSecondOutput 1395;
BA_ "SigType" SG_ 2147548808 EngCyl2IgntTransSecondOutput "RANGE";
BA_ "SPN" SG_ 2147548808 EngCyl2IgntTransSecondOutput 1394;
BA_ "SigType" SG_ 2147548808 EngCyl1IgntTransSecondOutput "RANGE";
BA_ "SPN" SG_ 2147548808 EngCyl1IgntTransSecondOutput 1393;
BA_ "SigType" SG_ 2147548616 EngOprtrPrmryIntrmdtSpdSlctStte "DISCRETE";
BA_ "SPN" SG_ 2147548616 EngOprtrPrmryIntrmdtSpdSlctStte 2892;
BA_ "SigType" SG_ 2147548618 EngOprtrPrmryIntrmdtSpeedSelect "DISCRETE";
BA_ "SPN" SG_ 2147548618 EngOprtrPrmryIntrmdtSpeedSelect 2880;
BA_ "SigType" SG_ 2147548892 EngTotalIdleHours "RANGE";
BA_ "SPN" SG_ 2147548892 EngTotalIdleHours 235;
BA_ "SigType" SG_ 2147548892 EngTotalIdleFuelUsed "RANGE";
BA_ "SPN" SG_ 2147548892 EngTotalIdleFuelUsed 236;
BA_ "SigType" SG_ 2147548837 EngIntakeManifold6Temp "RANGE";
BA_ "SPN" SG_ 2147548837 EngIntakeManifold6Temp 1803;
BA_ "SigType" SG_ 2147548837 EngIntakeManifold5Temp "RANGE";
BA_ "SPN" SG_ 2147548837 EngIntakeManifold5Temp 1802;
BA_ "SigType" SG_ 2147548837 EngIntakeManifold4Temp "RANGE";
BA_ "SPN" SG_ 2147548837 EngIntakeManifold4Temp 1133;
BA_ "SigType" SG_ 2147548837 EngIntakeManifold3Temp "RANGE";
BA_ "SPN" SG_ 2147548837 EngIntakeManifold3Temp 1132;
BA_ "SigType" SG_ 2147548837 EngIntakeManifold2Temp "RANGE";
BA_ "SPN" SG_ 2147548837 EngIntakeManifold2Temp 1131;
BA_ "SigType" SG_ 2147548838 EngTurbo4BoostPress "DISCRETE";
BA_ "SPN" SG_ 2147548838 EngTurbo4BoostPress 1130;
BA_ "SigType" SG_ 2147548838 EngTurbo3BoostPress "DISCRETE";
BA_ "SPN" SG_ 2147548838 EngTurbo3BoostPress 1129;
BA_ "SigType" SG_ 2147548838 EngTurbo2BoostPress "DISCRETE";
BA_ "SPN" SG_ 2147548838 EngTurbo2BoostPress 1128;
BA_ "SigType" SG_ 2147548838 EngTurbo1BoostPress "DISCRETE";
BA_ "SPN" SG_ 2147548838 EngTurbo1BoostPress 1127;
BA_ "SigType" SG_ 2147548624 EngAirFilter4DiffPress "DISCRETE";
BA_ "SPN" SG_ 2147548624 EngAirFilter4DiffPress 2811;
BA_ "SigType" SG_ 2147548624 EngAirFilter3DiffPress "DISCRETE";
BA_ "SPN" SG_ 2147548624 EngAirFilter3DiffPress 2810;
BA_ "SigType" SG_ 2147548624 EngAirFilter2DiffPress "DISCRETE";
BA_ "SPN" SG_ 2147548624 EngAirFilter2DiffPress 2809;
BA_ "SigType" SG_ 2147548918 EngCoolantFilterDiffPress "RANGE";
BA_ "SPN" SG_ 2147548918 EngCoolantFilterDiffPress 112;
BA_ "SigType" SG_ 2147548918 EngExhaustGasTemp "RANGE";
BA_ "SPN" SG_ 2147548918 EngExhaustGasTemp 173;
BA_ "SigType" SG_ 2147548918 EngAirFilter1DiffPress "DISCRETE";
BA_ "SPN" SG_ 2147548918 EngAirFilter1DiffPress 107;
BA_ "SigType" SG_ 2147548918 EngAirInletPress "RANGE";
BA_ "SPN" SG_ 2147548918 EngAirInletPress 106;
BA_ "SigType" SG_ 2147548918 EngIntakeManifold1Temp "RANGE";
BA_ "SPN" SG_ 2147548918 EngIntakeManifold1Temp 105;
BA_ "SigType" SG_ 2147548918 EngTurboBoostPress "RANGE";
BA_ "SPN" SG_ 2147548918 EngTurboBoostPress 102;
BA_ "SigType" SG_ 2147548918 EngParticulateTrapInletPress "RANGE";
BA_ "SPN" SG_ 2147548918 EngParticulateTrapInletPress 81;
BA_ "SigType" SG_ 2147548781 CabHeatingZone "DISCRETE";
BA_ "SPN" SG_ 2147548781 CabHeatingZone 1680;
BA_ "SigType" SG_ 2147548781 EngHeatingZone "DISCRETE";
BA_ "SPN" SG_ 2147548781 EngHeatingZone 1679;
BA_ "SigType" SG_ 2147548781 CabVentilation "DISCRETE";
BA_ "SPN" SG_ 2147548781 CabVentilation 1678;
BA_ "SigType" SG_ 2147548781 AuxilaryHeaterWaterPumpStatus "DISCRETE";
BA_ "SPN" SG_ 2147548781 AuxilaryHeaterWaterPumpStatus 1676;
BA_ "SigType" SG_ 2147548781 AuxHeaterMode "DISCRETE";
BA_ "SPN" SG_ 2147548781 AuxHeaterMode 1677;
BA_ "SigType" SG_ 2147548781 AuxHeaterOutputPowerPercent "RANGE";
BA_ "SPN" SG_ 2147548781 AuxHeaterOutputPowerPercent 1689;
BA_ "SigType" SG_ 2147548781 AuxHeaterInputAirTemp "RANGE";
BA_ "SPN" SG_ 2147548781 AuxHeaterInputAirTemp 1688;
BA_ "SigType" SG_ 2147548781 AuxHeaterOutputCoolantTemp "RANGE";
BA_ "SPN" SG_ 2147548781 AuxHeaterOutputCoolantTemp 1687;
BA_ "SigType" SG_ 2147548782 RearAxleRightWheelSpeed "RANGE";
BA_ "SPN" SG_ 2147548782 RearAxleRightWheelSpeed 1595;
BA_ "SigType" SG_ 2147548782 RearAxleLeftWheelSpeed "RANGE";
BA_ "SPN" SG_ 2147548782 RearAxleLeftWheelSpeed 1594;
BA_ "SigType" SG_ 2147548782 FrontAxleRightWheelSpeed "RANGE";
BA_ "SPN" SG_ 2147548782 FrontAxleRightWheelSpeed 1593;
BA_ "SigType" SG_ 2147548782 FrontAxleLeftWheelSpeed "RANGE";
BA_ "SPN" SG_ 2147548782 FrontAxleLeftWheelSpeed 1592;
BA_ "SigType" SG_ 2147545096 FireApparatusPumpEngagement "DISCRETE";
BA_ "SPN" SG_ 2147545096 FireApparatusPumpEngagement 2599;
BA_ "SigType" SG_ 2147545096 EngHydPressGovernorSwitch "DISCRETE";
BA_ "SPN" SG_ 2147545096 EngHydPressGovernorSwitch 1764;
BA_ "SigType" SG_ 2147545096 EngHydPrssGovernorModeIndicator "DISCRETE";
BA_ "SPN" SG_ 2147545096 EngHydPrssGovernorModeIndicator 1763;
BA_ "SigType" SG_ 2147545096 HydPress "RANGE";
BA_ "SPN" SG_ 2147545096 HydPress 1762;
BA_ "SigType" SG_ 2147548901 EngTotalRevolutions "RANGE";
BA_ "SPN" SG_ 2147548901 EngTotalRevolutions 249;
BA_ "SigType" SG_ 2147548901 EngTotalHoursOfOperation "RANGE";
BA_ "SPN" SG_ 2147548901 EngTotalHoursOfOperation 247;
BA_ "SigType" SG_ 2147548646 HydBrakeFluidLevelSwitch "DISCRETE";
BA_ "SPN" SG_ 2147548646 HydBrakeFluidLevelSwitch 2931;
BA_ "SigType" SG_ 2147548646 HydBrakeSystemAudibleWarningCmd "DISCRETE";
BA_ "SPN" SG_ 2147548646 HydBrakeSystemAudibleWarningCmd 2930;
BA_ "SigType" SG_ 2147548646 HydBrkePressSupplyStateCircuit2 "DISCRETE";
BA_ "SPN" SG_ 2147548646 HydBrkePressSupplyStateCircuit2 2583;
BA_ "SigType" SG_ 2147548646 HydBrkePressSupplyStateCircuit1 "DISCRETE";
BA_ "SPN" SG_ 2147548646 HydBrkePressSupplyStateCircuit1 2582;
BA_ "SigType" SG_ 2147548646 HydBrkPressWarningStateCircuit2 "DISCRETE";
BA_ "SPN" SG_ 2147548646 HydBrkPressWarningStateCircuit2 2585;
BA_ "SigType" SG_ 2147548646 HydBrkPressWarningStateCircuit1 "DISCRETE";
BA_ "SPN" SG_ 2147548646 HydBrkPressWarningStateCircuit1 2584;
BA_ "SigType" SG_ 2147548646 HydBrakePressCircuit2 "RANGE";
BA_ "SPN" SG_ 2147548646 HydBrakePressCircuit2 2581;
BA_ "SigType" SG_ 2147548646 HydBrakePressCircuit1 "RANGE";
BA_ "SPN" SG_ 2147548646 HydBrakePressCircuit1 2580;
BA_ "SigType" SG_ 2147548856 TripDriveFuelEconomy "RANGE";
BA_ "SPN" SG_ 2147548856 TripDriveFuelEconomy 1012;
BA_ "SigType" SG_ 2147548856 TripCruiseFuelUsed "RANGE";
BA_ "SPN" SG_ 2147548856 TripCruiseFuelUsed 1011;
BA_ "SigType" SG_ 2147548856 TripVehicleIdleFuelUsed "RANGE";
BA_ "SPN" SG_ 2147548856 TripVehicleIdleFuelUsed 1010;
BA_ "SigType" SG_ 2147548856 TripPTONonmovingFuelUsed "RANGE";
BA_ "SPN" SG_ 2147548856 TripPTONonmovingFuelUsed 1009;
BA_ "SigType" SG_ 2147548856 TripPTOMovingFuelUsed "RANGE";
BA_ "SPN" SG_ 2147548856 TripPTOMovingFuelUsed 1008;
BA_ "SigType" SG_ 2147548856 TripDriveFuelUsed "RANGE";
BA_ "SPN" SG_ 2147548856 TripDriveFuelUsed 1007;
BA_ "SigType" SG_ 2147548811 EngAirToFuelDiffPress "RANGE";
BA_ "SPN" SG_ 2147548811 EngAirToFuelDiffPress 1392;
BA_ "SigType" SG_ 2147548811 EngFuelValveDiffPress "RANGE";
BA_ "SPN" SG_ 2147548811 EngFuelValveDiffPress 1391;
BA_ "SigType" SG_ 2147548811 EngFuelValveInletAbsPress "RANGE";
BA_ "SPN" SG_ 2147548811 EngFuelValveInletAbsPress 1390;
BA_ "SigType" SG_ 2147548801 EngFuelFlowRate2 "RANGE";
BA_ "SPN" SG_ 2147548801 EngFuelFlowRate2 1441;
BA_ "SigType" SG_ 2147548801 EngFuelFlowRate1 "RANGE";
BA_ "SPN" SG_ 2147548801 EngFuelFlowRate1 1440;
BA_ "SigType" SG_ 2147548801 EngRqedFuelValve2Pos "RANGE";
BA_ "SPN" SG_ 2147548801 EngRqedFuelValve2Pos 1766;
BA_ "SigType" SG_ 2147548801 EngRqedFuelValve1Pos "RANGE";
BA_ "SPN" SG_ 2147548801 EngRqedFuelValve1Pos 1765;
BA_ "SigType" SG_ 2147548801 EngFuelValve2Pos "RANGE";
BA_ "SPN" SG_ 2147548801 EngFuelValve2Pos 1443;
BA_ "SigType" SG_ 2147548801 EngFuelValve1Pos "RANGE";
BA_ "SPN" SG_ 2147548801 EngFuelValve1Pos 1442;
BA_ "SigType" SG_ 2147548850 EngFuelSpecificGravity "DISCRETE";
BA_ "SPN" SG_ 2147548850 EngFuelSpecificGravity 1389;
BA_ "SigType" SG_ 2147548850 TripAverageFuelRate "RANGE";
BA_ "SPN" SG_ 2147548850 TripAverageFuelRate 1031;
BA_ "SigType" SG_ 2147548850 TotalEngPTOFuelUsed "RANGE";
BA_ "SPN" SG_ 2147548850 TotalEngPTOFuelUsed 1030;
BA_ "SigType" SG_ 2147548757 SpecificHeatRatio "RANGE";
BA_ "SPN" SG_ 2147548757 SpecificHeatRatio 1767;
BA_ "SigType" SG_ 2147548847 TotalFuelUsed "RANGE";
BA_ "SPN" SG_ 2147548847 TotalFuelUsed 1040;
BA_ "SigType" SG_ 2147548847 TripFuel "RANGE";
BA_ "SPN" SG_ 2147548847 TripFuel 1039;
BA_ "SigType" SG_ 2147544320 ControlByte "RANGE";
BA_ "SigType" SG_ 2147544320 FilterMode "DISCRETE";
BA_ "SigType" SG_ 2147484672 XBRMessageChecksum "DISCRETE";
BA_ "SPN" SG_ 2147484672 XBRMessageChecksum 3188;
BA_ "SigType" SG_ 2147484672 XBRMessageCounter "DISCRETE";
BA_ "SPN" SG_ 2147484672 XBRMessageCounter 3189;
BA_ "SigType" SG_ 2147484672 XBRCtrlMode "DISCRETE";
BA_ "SPN" SG_ 2147484672 XBRCtrlMode 2916;
BA_ "SigType" SG_ 2147484672 XBRPriority "DISCRETE";
BA_ "SPN" SG_ 2147484672 XBRPriority 2915;
BA_ "SigType" SG_ 2147484672 XBREBIMode "DISCRETE";
BA_ "SPN" SG_ 2147484672 XBREBIMode 2914;
BA_ "SigType" SG_ 2147484672 ExtlAccelerationDemand "RANGE";
BA_ "SPN" SG_ 2147484672 ExtlAccelerationDemand 2920;
BA_ "SigType" SG_ 2147548927 WaterInFuelIndicator "DISCRETE";
BA_ "SPN" SG_ 2147548927 WaterInFuelIndicator 97;
BA_ "SigType" SG_ 2147548906 CargoWeight "RANGE";
BA_ "SPN" SG_ 2147548906 CargoWeight 181;
BA_ "SigType" SG_ 2147548906 TrailerWeight "RANGE";
BA_ "SPN" SG_ 2147548906 TrailerWeight 180;
BA_ "SigType" SG_ 2147548906 AxleWeight "RANGE";
BA_ "SPN" SG_ 2147548906 AxleWeight 582;
BA_ "SigType" SG_ 2147548906 AxleLocation "RANGE";
BA_ "SPN" SG_ 2147548906 AxleLocation 2928;
BA_ "SigType" SG_ 2147548754 NetBatteryCurrentHiRes "RANGE";
BA_ "SPN" SG_ 2147548754 NetBatteryCurrentHiRes 2579;
BA_ "SigType" SG_ 2147548754 AltCurrentHiRes "RANGE";
BA_ "SPN" SG_ 2147548754 AltCurrentHiRes 1795;
BA_ "SigType" SG_ 2147548813 Battery2Potential "RANGE";
BA_ "SPN" SG_ 2147548813 Battery2Potential 444;
BA_ "SigType" SG_ 2147548915 Longitude "RANGE";
BA_ "SPN" SG_ 2147548915 Longitude 585;
BA_ "SigType" SG_ 2147548915 Latitude "RANGE";
BA_ "SPN" SG_ 2147548915 Latitude 584;
BA_ "SigType" SG_ 2147548903 TotalPowerTakeoffHours "RANGE";
BA_ "SPN" SG_ 2147548903 TotalPowerTakeoffHours 248;
BA_ "SigType" SG_ 2147548903 TotalVehicleHours "RANGE";
BA_ "SPN" SG_ 2147548903 TotalVehicleHours 246;
BA_ "SigType" SG_ 2147548776 WinchOilPressSwitch "DISCRETE";
BA_ "SPN" SG_ 2147548776 WinchOilPressSwitch 1857;
BA_ "SigType" SG_ 2147548776 HydOilLevel "RANGE";
BA_ "SPN" SG_ 2147548776 HydOilLevel 2602;
BA_ "SigType" SG_ 2147548776 HydOilFilterRestrictionSwitch "DISCRETE";
BA_ "SPN" SG_ 2147548776 HydOilFilterRestrictionSwitch 1713;
BA_ "SigType" SG_ 2147548776 HydTemp "RANGE";
BA_ "SPN" SG_ 2147548776 HydTemp 1638;
BA_ "SigType" SG_ 2147548919 NetBatteryCurrent "RANGE";
BA_ "SPN" SG_ 2147548919 NetBatteryCurrent 114;
BA_ "SigType" SG_ 2147548919 AltCurrent "RANGE";
BA_ "SPN" SG_ 2147548919 AltCurrent 115;
BA_ "SigType" SG_ 2147548919 BatteryPotentialSwitched "RANGE";
BA_ "SPN" SG_ 2147548919 BatteryPotentialSwitched 158;
BA_ "SigType" SG_ 2147548919 ElectricalPotential "RANGE";
BA_ "SPN" SG_ 2147548919 ElectricalPotential 168;
BA_ "SigType" SG_ 2147548919 AltPotential "RANGE";
BA_ "SPN" SG_ 2147548919 AltPotential 167;
BA_ "SigType" SG_ 2147548904 Altitude "RANGE";
BA_ "SPN" SG_ 2147548904 Altitude 580;
BA_ "SigType" SG_ 2147548904 Pitch "RANGE";
BA_ "SPN" SG_ 2147548904 Pitch 583;
BA_ "SigType" SG_ 2147548904 NavigationBasedVehicleSpeed "RANGE";
BA_ "SPN" SG_ 2147548904 NavigationBasedVehicleSpeed 517;
BA_ "SigType" SG_ 2147548904 CompassBearing "RANGE";
BA_ "SPN" SG_ 2147548904 CompassBearing 165;
BA_ "SigType" SG_ 2147548865 HighResolutionTripDistance "RANGE";
BA_ "SPN" SG_ 2147548865 HighResolutionTripDistance 918;
BA_ "SigType" SG_ 2147548865 HghRslutionTotalVehicleDistance "RANGE";
BA_ "SPN" SG_ 2147548865 HghRslutionTotalVehicleDistance 917;
BA_ "SigType" SG_ 2147545097 LongitudinalAcceleration "RANGE";
BA_ "SPN" SG_ 2147545097 LongitudinalAcceleration 1810;
BA_ "SigType" SG_ 2147545097 LateralAcceleration "RANGE";
BA_ "SPN" SG_ 2147545097 LateralAcceleration 1809;
BA_ "SigType" SG_ 2147545097 YawRate "RANGE";
BA_ "SPN" SG_ 2147545097 YawRate 1808;
BA_ "SigType" SG_ 2147545097 SteerWheelAngleSensorType "DISCRETE";
BA_ "SPN" SG_ 2147545097 SteerWheelAngleSensorType 1812;
BA_ "SigType" SG_ 2147545097 SteerWheelTurnCounter "RANGE";
BA_ "SPN" SG_ 2147545097 SteerWheelTurnCounter 1811;
BA_ "SigType" SG_ 2147545097 SteerWheelAngle "RANGE";
BA_ "SPN" SG_ 2147545097 SteerWheelAngle 1807;
BA_ "SigType" SG_ 2147548751 YCBrakeCtrlActive "DISCRETE";
BA_ "SPN" SG_ 2147548751 YCBrakeCtrlActive 1819;
BA_ "SigType" SG_ 2147548751 YCEngCtrlActive "DISCRETE";
BA_ "SPN" SG_ 2147548751 YCEngCtrlActive 1817;
BA_ "SigType" SG_ 2147548751 ROPBrakeCtrlActive "DISCRETE";
BA_ "SPN" SG_ 2147548751 ROPBrakeCtrlActive 1818;
BA_ "SigType" SG_ 2147548751 ROPEngCtrlActive "DISCRETE";
BA_ "SPN" SG_ 2147548751 ROPEngCtrlActive 1816;
BA_ "SigType" SG_ 2147548751 VDCBrakeLightRq "DISCRETE";
BA_ "SPN" SG_ 2147548751 VDCBrakeLightRq 1815;
BA_ "SigType" SG_ 2147548751 VDCFullyOperational "DISCRETE";
BA_ "SPN" SG_ 2147548751 VDCFullyOperational 1814;
BA_ "SigType" SG_ 2147548751 VDCInformationSignal "DISCRETE";
BA_ "SPN" SG_ 2147548751 VDCInformationSignal 1813;
BA_ "SigType" SG_ 2147548896 TotalVehicleDistance "RANGE";
BA_ "SPN" SG_ 2147548896 TotalVehicleDistance 245;
BA_ "SigType" SG_ 2147548896 TripDistance "RANGE";
BA_ "SPN" SG_ 2147548896 TripDistance 244;
BA_ "SigType" SG_ 2147548854 TripCruiseDistance "RANGE";
BA_ "SPN" SG_ 2147548854 TripCruiseDistance 1019;
BA_ "SigType" SG_ 2147548854 TripMaxVehicleSpeed "RANGE";
BA_ "SPN" SG_ 2147548854 TripMaxVehicleSpeed 1018;
BA_ "SigType" SG_ 2147548848 TripAirCompressorOnTime "RANGE";
BA_ "SPN" SG_ 2147548848 TripAirCompressorOnTime 1038;
BA_ "SigType" SG_ 2147548848 TripIdleTime "RANGE";
BA_ "SPN" SG_ 2147548848 TripIdleTime 1037;
BA_ "SigType" SG_ 2147548848 TripEngRunningTime "RANGE";
BA_ "SPN" SG_ 2147548848 TripEngRunningTime 1036;
BA_ "SigType" SG_ 2147548848 TripPTOTime "RANGE";
BA_ "SPN" SG_ 2147548848 TripPTOTime 1035;
BA_ "SigType" SG_ 2147548848 TripCruiseTime "RANGE";
BA_ "SPN" SG_ 2147548848 TripCruiseTime 1034;
BA_ "SigType" SG_ 2147548852 TripTimeInDerateByEng "RANGE";
BA_ "SPN" SG_ 2147548852 TripTimeInDerateByEng 1027;
BA_ "SigType" SG_ 2147548852 TripTimeInGearDown "RANGE";
BA_ "SPN" SG_ 2147548852 TripTimeInGearDown 1026;
BA_ "SigType" SG_ 2147548852 TripTimeInTopGear "RANGE";
BA_ "SPN" SG_ 2147548852 TripTimeInTopGear 1025;
BA_ "SigType" SG_ 2147548852 TripTimeInVSL "RANGE";
BA_ "SPN" SG_ 2147548852 TripTimeInVSL 1024;
BA_ "SigType" SG_ 2147548853 TripSuddenDecelerations "RANGE";
BA_ "SPN" SG_ 2147548853 TripSuddenDecelerations 1023;
BA_ "SigType" SG_ 2147548853 TrpNmberOfIdleShutdownOverrides "RANGE";
BA_ "SPN" SG_ 2147548853 TrpNmberOfIdleShutdownOverrides 1022;
BA_ "SigType" SG_ 2147548853 TripNumberOfIdleShutdowns "RANGE";
BA_ "SPN" SG_ 2147548853 TripNumberOfIdleShutdowns 1021;
BA_ "SigType" SG_ 2147548853 TripNumberOfHotShutdowns "RANGE";
BA_ "SPN" SG_ 2147548853 TripNumberOfHotShutdowns 1020;
BA_ "SigType" SG_ 2147483648 EngRqedTorque_TorqueLimit "RANGE";
BA_ "SPN" SG_ 2147483648 EngRqedTorque_TorqueLimit 518;
BA_ "SigType" SG_ 2147483648 EngRqedSpeed_SpeedLimit "RANGE";
BA_ "SPN" SG_ 2147483648 EngRqedSpeed_SpeedLimit 898;
BA_ "SigType" SG_ 2147483648 OverrideCtrlModePriority "DISCRETE";
BA_ "SPN" SG_ 2147483648 OverrideCtrlModePriority 897;
BA_ "SigType" SG_ 2147483648 EngRqedSpeedCtrlConditions "DISCRETE";
BA_ "SPN" SG_ 2147483648 EngRqedSpeedCtrlConditions 696;
BA_ "SigType" SG_ 2147483648 EngOverrideCtrlMode "DISCRETE";
BA_ "SPN" SG_ 2147483648 EngOverrideCtrlMode 695;
BA_ "SigType" SG_ 2147548608 TransitRunStatus "DISCRETE";
BA_ "SPN" SG_ 2147548608 TransitRunStatus 3046;
BA_ "SigType" SG_ 2147548608 VehicleUseStatus "DISCRETE";
BA_ "SPN" SG_ 2147548608 VehicleUseStatus 3045;
BA_ "SigType" SG_ 2147548608 SilentAlarmStatus "DISCRETE";
BA_ "SPN" SG_ 2147548608 SilentAlarmStatus 3044;
BA_ "SigType" SG_ 2147548608 PatronCount "RANGE";
BA_ "SPN" SG_ 2147548608 PatronCount 3047;
BA_ "SigType" SG_ 2147548608 TypeOfPassengerCount "RANGE";
BA_ "SPN" SG_ 2147548608 TypeOfPassengerCount 3043;
BA_ "SigType" SG_ 2147548602 FareboxAlarmIdentifier "RANGE";
BA_ "SPN" SG_ 2147548602 FareboxAlarmIdentifier 3181;
BA_ "SigType" SG_ 2147548602 FareboxEmergencyStatus "DISCRETE";
BA_ "SPN" SG_ 2147548602 FareboxEmergencyStatus 3179;
BA_ "SigType" SG_ 2147548603 TransferSold "RANGE";
BA_ "SPN" SG_ 2147548603 TransferSold 3168;
BA_ "SigType" SG_ 2147548603 RouteNumber "RANGE";
BA_ "SPN" SG_ 2147548603 RouteNumber 3169;
BA_ "SigType" SG_ 2147548603 TransferType "RANGE";
BA_ "SPN" SG_ 2147548603 TransferType 3173;
BA_ "SigType" SG_ 2147548603 TypeOfService "DISCRETE";
BA_ "SPN" SG_ 2147548603 TypeOfService 3172;
BA_ "SigType" SG_ 2147548603 InitialFareAgency "RANGE";
BA_ "SPN" SG_ 2147548603 InitialFareAgency 3167;
BA_ "SigType" SG_ 2147548603 PassCategory "DISCRETE";
BA_ "SPN" SG_ 2147548603 PassCategory 3166;
BA_ "SigType" SG_ 2147548603 FareValidity "DISCRETE";
BA_ "SPN" SG_ 2147548603 FareValidity 3165;
BA_ "SigType" SG_ 2147548603 PaymentDetails "DISCRETE";
BA_ "SPN" SG_ 2147548603 PaymentDetails 3177;
BA_ "SigType" SG_ 2147548603 TypeOfFare "DISCRETE";
BA_ "SPN" SG_ 2147548603 TypeOfFare 3176;
BA_ "SigType" SG_ 2147548603 PassengerType "DISCRETE";
BA_ "SPN" SG_ 2147548603 PassengerType 3171;
BA_ "SigType" SG_ 2147548603 TransactionType "DISCRETE";
BA_ "SPN" SG_ 2147548603 TransactionType 3170;
BA_ "SigType" SG_ 2147548604 DriversFareboxSecurityCode "RANGE";
BA_ "SPN" SG_ 2147548604 DriversFareboxSecurityCode 3164;
BA_ "SigType" SG_ 2147548604 AssignedBlock "RANGE";
BA_ "SPN" SG_ 2147548604 AssignedBlock 3163;
BA_ "SigType" SG_ 2147548604 AssignedRun "RANGE";
BA_ "SPN" SG_ 2147548604 AssignedRun 3162;
BA_ "SigType" SG_ 2147548604 AssignedRoute "RANGE";
BA_ "SPN" SG_ 2147548604 AssignedRoute 3160;
BA_ "SigType" SG_ 2147548604 PatternNumber "RANGE";
BA_ "SPN" SG_ 2147548604 PatternNumber 3161;
BA_ "SigType" SG_ 2147548604 TripNumber "RANGE";
BA_ "SPN" SG_ 2147548604 TripNumber 3159;
BA_ "SigType" SG_ 2147548604 FarePresets "RANGE";
BA_ "SPN" SG_ 2147548604 FarePresets 3175;
BA_ "SigType" SG_ 2147548604 TripDirection "DISCRETE";
BA_ "SPN" SG_ 2147548604 TripDirection 3174;
BA_ "SigType" SG_ 2147548604 TripStatus "DISCRETE";
BA_ "SPN" SG_ 2147548604 TripStatus 3180;
BA_ "SigType" SG_ 2147548604 FareboxServiceStatus "DISCRETE";
BA_ "SPN" SG_ 2147548604 FareboxServiceStatus 3178;
BA_ "SigType" SG_ 2147548605 VehicleID "RANGE";
BA_ "SPN" SG_ 2147548605 VehicleID 3085;
BA_ "SigType" SG_ 2147548605 StrobeActivationCtrlStatus "DISCRETE";
BA_ "SPN" SG_ 2147548605 StrobeActivationCtrlStatus 3082;
BA_ "SigType" SG_ 2147548605 TransitDoorEnable "DISCRETE";
BA_ "SPN" SG_ 2147548605 TransitDoorEnable 3083;
BA_ "SigType" SG_ 2147548605 PriorityOfRespSentByEmitter "DISCRETE";
BA_ "SPN" SG_ 2147548605 PriorityOfRespSentByEmitter 3084;
BA_ "SigType" SG_ 2147548605 IntersectionPreemptionRq_Resp "DISCRETE";
BA_ "SPN" SG_ 2147548605 IntersectionPreemptionRq_Resp 3079;
BA_ "SigType" SG_ 2147548605 TransitRouteIDUsage "DISCRETE";
BA_ "SPN" SG_ 2147548605 TransitRouteIDUsage 3080;
BA_ "SigType" SG_ 2147548605 RangeCodeEnable "DISCRETE";
BA_ "SPN" SG_ 2147548605 RangeCodeEnable 3081;
BA_ "SigType" SG_ 2147548607 NmbrOfBytsInMlpstIdentification "RANGE";
BA_ "SPN" SG_ 2147548607 NmbrOfBytsInMlpstIdentification 3070;
BA_ "SigType" SG_ 2147548606 Agency "RANGE";
BA_ "SPN" SG_ 2147548606 Agency 3078;
BA_ "SigType" SG_ 2147548606 NmbrOfBytsInTrnstAssgndBlckIdntt "RANGE";
BA_ "SPN" SG_ 2147548606 NmbrOfBytsInTrnstAssgndBlckIdntt 3073;
BA_ "SigType" SG_ 2147548606 NmbrOfBytsInTrnstAssgndRnIdntty "RANGE";
BA_ "SPN" SG_ 2147548606 NmbrOfBytsInTrnstAssgndRnIdntty 3072;
BA_ "SigType" SG_ 2147548606 NmbrOfBytsInTrnstAssgndRtIdntty "RANGE";
BA_ "SPN" SG_ 2147548606 NmbrOfBytsInTrnstAssgndRtIdntty 3071;
BA_ "SigType" SG_ 2147528192 ReferenceTirePressSetting "RANGE";
BA_ "SPN" SG_ 2147528192 ReferenceTirePressSetting 3193;
BA_ "SigType" SG_ 2147528192 TireLocation "RANGE";
BA_ "SPN" SG_ 2147528192 TireLocation 3192;
BA_ "SigType" SG_ 2147548601 ReferenceTirePress "RANGE";
BA_ "SPN" SG_ 2147548601 ReferenceTirePress 3191;
BA_ "SigType" SG_ 2147548601 TireLocation "RANGE";
BA_ "SPN" SG_ 2147548601 TireLocation 3192;
BA_ "SigType" SG_ 2147548794 SteerChannelTirePress "RANGE";
BA_ "SPN" SG_ 2147548794 SteerChannelTirePress 146;
BA_ "SigType" SG_ 2147548794 DriveChannelTirePress "RANGE";
BA_ "SPN" SG_ 2147548794 DriveChannelTirePress 145;
BA_ "SigType" SG_ 2147548794 TrailerTagPushChannelTirePress "RANGE";
BA_ "SPN" SG_ 2147548794 TrailerTagPushChannelTirePress 144;
BA_ "SigType" SG_ 2147548793 SteerChannelTirePressTarget "RANGE";
BA_ "SPN" SG_ 2147548793 SteerChannelTirePressTarget 143;
BA_ "SigType" SG_ 2147548793 DriveChannelTirePressTarget "RANGE";
BA_ "SPN" SG_ 2147548793 DriveChannelTirePressTarget 142;
BA_ "SigType" SG_ 2147548793 TrlrTgPshChannelTirePressTarget "RANGE";
BA_ "SPN" SG_ 2147548793 TrlrTgPshChannelTirePressTarget 141;
BA_ "SigType" SG_ 2147548792 PCUSupplySolenoidStatus "DISCRETE";
BA_ "SPN" SG_ 2147548792 PCUSupplySolenoidStatus 1474;
BA_ "SigType" SG_ 2147548792 PCUCtrlSolenoidStatus "DISCRETE";
BA_ "SPN" SG_ 2147548792 PCUCtrlSolenoidStatus 1473;
BA_ "SigType" SG_ 2147548792 PCUDeflateSolenoidStatus "DISCRETE";
BA_ "SPN" SG_ 2147548792 PCUDeflateSolenoidStatus 1472;
BA_ "SigType" SG_ 2147548792 TirePressSupplySwitchStatus "DISCRETE";
BA_ "SPN" SG_ 2147548792 TirePressSupplySwitchStatus 1471;
BA_ "SigType" SG_ 2147548792 PCUSteerSolenoidStatus "DISCRETE";
BA_ "SPN" SG_ 2147548792 PCUSteerSolenoidStatus 1470;
BA_ "SigType" SG_ 2147548792 PCUDriveSolenoidStatus "DISCRETE";
BA_ "SPN" SG_ 2147548792 PCUDriveSolenoidStatus 1469;
BA_ "SigType" SG_ 2147548792 DriveChannelMode "DISCRETE";
BA_ "SPN" SG_ 2147548792 DriveChannelMode 1468;
BA_ "SigType" SG_ 2147548792 Trailer_TagChannelMode "DISCRETE";
BA_ "SPN" SG_ 2147548792 Trailer_TagChannelMode 1467;
BA_ "SigType" SG_ 2147548792 SteerChannelMode "DISCRETE";
BA_ "SPN" SG_ 2147548792 SteerChannelMode 1466;
BA_ "SigType" SG_ 2147548792 TirePressCheckInterval "RANGE";
BA_ "SPN" SG_ 2147548792 TirePressCheckInterval 39;
BA_ "SigType" SG_ 2147548792 PCUTrailerTagPushSolenoidStatus "DISCRETE";
BA_ "SPN" SG_ 2147548792 PCUTrailerTagPushSolenoidStatus 1475;
BA_ "SigType" SG_ 2147548916 TirePressThresholdDetection "DISCRETE";
BA_ "SPN" SG_ 2147548916 TirePressThresholdDetection 2587;
BA_ "SigType" SG_ 2147548916 TireAirLeakageRate "DISCRETE";
BA_ "SPN" SG_ 2147548916 TireAirLeakageRate 2586;
BA_ "SigType" SG_ 2147548916 CTIWheelEndElectricalFault "DISCRETE";
BA_ "SPN" SG_ 2147548916 CTIWheelEndElectricalFault 1697;
BA_ "SigType" SG_ 2147548916 CTITireStatus "DISCRETE";
BA_ "SPN" SG_ 2147548916 CTITireStatus 1698;
BA_ "SigType" SG_ 2147548916 CTIWheelSensorStatus "DISCRETE";
BA_ "SPN" SG_ 2147548916 CTIWheelSensorStatus 1699;
BA_ "SigType" SG_ 2147548916 TireTemp "RANGE";
BA_ "SPN" SG_ 2147548916 TireTemp 242;
BA_ "SigType" SG_ 2147548916 TirePress "RANGE";
BA_ "SPN" SG_ 2147548916 TirePress 241;
BA_ "SigType" SG_ 2147548916 TireLocation "RANGE";
BA_ "SPN" SG_ 2147548916 TireLocation 3192;
BA_ "SigType" SG_ 2147548758 CatalystTankTemp "RANGE";
BA_ "SPN" SG_ 2147548758 CatalystTankTemp 3031;
BA_ "SigType" SG_ 2147548758 CatalystTankLevel "RANGE";
BA_ "SPN" SG_ 2147548758 CatalystTankLevel 1761;
BA_ "SigType" SG_ 2147548859 TripFanOnTimeDueToAManualSwitch "RANGE";
BA_ "SPN" SG_ 2147548859 TripFanOnTimeDueToAManualSwitch 996;
BA_ "SigType" SG_ 2147548859 TripFanOnTime "RANGE";
BA_ "SPN" SG_ 2147548859 TripFanOnTime 994;
BA_ "SigType" SG_ 2147548859 TripFanOnTimeDueToA_CSystem "RANGE";
BA_ "SPN" SG_ 2147548859 TripFanOnTimeDueToA_CSystem 997;
BA_ "SigType" SG_ 2147548859 TripFanOnTimeDueToEngSystem "RANGE";
BA_ "SPN" SG_ 2147548859 TripFanOnTimeDueToEngSystem 995;
BA_ "SigType" SG_ 2147548920 TransOilLevelMeasurementStatus "DISCRETE";
BA_ "SPN" SG_ 2147548920 TransOilLevelMeasurementStatus 3026;
BA_ "SigType" SG_ 2147548920 TransOilLevelCountdownTimer "DISCRETE";
BA_ "SPN" SG_ 2147548920 TransOilLevelCountdownTimer 3028;
BA_ "SigType" SG_ 2147548920 TransOilLevelHigh_Low "RANGE";
BA_ "SPN" SG_ 2147548920 TransOilLevelHigh_Low 3027;
BA_ "SigType" SG_ 2147548920 TransOilTemp "RANGE";
BA_ "SPN" SG_ 2147548920 TransOilTemp 177;
BA_ "SigType" SG_ 2147548920 TransOilPress "RANGE";
BA_ "SPN" SG_ 2147548920 TransOilPress 127;
BA_ "SigType" SG_ 2147548920 TransFilterDiffPress "RANGE";
BA_ "SPN" SG_ 2147548920 TransFilterDiffPress 126;
BA_ "SigType" SG_ 2147548920 TransOilLevel "RANGE";
BA_ "SPN" SG_ 2147548920 TransOilLevel 124;
BA_ "SigType" SG_ 2147548920 ClutchPress "RANGE";
BA_ "SPN" SG_ 2147548920 ClutchPress 123;
BA_ "SigType" SG_ 2147548858 TripDistanceInTopGear "RANGE";
BA_ "SPN" SG_ 2147548858 TripDistanceInTopGear 1000;
BA_ "SigType" SG_ 2147548858 TripGearDownDistance "RANGE";
BA_ "SPN" SG_ 2147548858 TripGearDownDistance 999;
BA_ "SigType" SG_ 2147548858 TripDistanceOnVSL "RANGE";
BA_ "SPN" SG_ 2147548858 TripDistanceOnVSL 998;
BA_ "SigType" SG_ 2147538176 AdjustLocalHourOffset "RANGE";
BA_ "SPN" SG_ 2147538176 AdjustLocalHourOffset 1610;
BA_ "SigType" SG_ 2147538176 AdjustLocalMinuteOffset "RANGE";
BA_ "SPN" SG_ 2147538176 AdjustLocalMinuteOffset 1609;
BA_ "SigType" SG_ 2147538176 AdjustYear "RANGE";
BA_ "SPN" SG_ 2147538176 AdjustYear 1608;
BA_ "SigType" SG_ 2147538176 AdjustDay "RANGE";
BA_ "SPN" SG_ 2147538176 AdjustDay 1607;
BA_ "SigType" SG_ 2147538176 AdjustMonth "RANGE";
BA_ "SPN" SG_ 2147538176 AdjustMonth 1606;
BA_ "SigType" SG_ 2147538176 AdjustHours "RANGE";
BA_ "SPN" SG_ 2147538176 AdjustHours 1605;
BA_ "SigType" SG_ 2147538176 AdjustMinutes "RANGE";
BA_ "SPN" SG_ 2147538176 AdjustMinutes 1604;
BA_ "SigType" SG_ 2147538176 AdjustSeconds "RANGE";
BA_ "SPN" SG_ 2147538176 AdjustSeconds 1603;
BA_ "SigType" SG_ 2147548902 LocalHourOffset "RANGE";
BA_ "SPN" SG_ 2147548902 LocalHourOffset 1602;
BA_ "SigType" SG_ 2147548902 LocalMinuteOffset "RANGE";
BA_ "SPN" SG_ 2147548902 LocalMinuteOffset 1601;
BA_ "SigType" SG_ 2147548902 Year "RANGE";
BA_ "SPN" SG_ 2147548902 Year 964;
BA_ "SigType" SG_ 2147548902 Day "RANGE";
BA_ "SPN" SG_ 2147548902 Day 962;
BA_ "SigType" SG_ 2147548902 Month "RANGE";
BA_ "SPN" SG_ 2147548902 Month 963;
BA_ "SigType" SG_ 2147548902 Hours "RANGE";
BA_ "SPN" SG_ 2147548902 Hours 961;
BA_ "SigType" SG_ 2147548902 Minutes "RANGE";
BA_ "SPN" SG_ 2147548902 Minutes 960;
BA_ "SigType" SG_ 2147548902 Seconds "RANGE";
BA_ "SPN" SG_ 2147548902 Seconds 959;
BA_ "SigType" SG_ 2147548822 EngTrbWstgtActuatorCtrlAirPress "RANGE";
BA_ "SPN" SG_ 2147548822 EngTrbWstgtActuatorCtrlAirPress 1192;
BA_ "SigType" SG_ 2147548822 EngTurbo4WastegateDrive "RANGE";
BA_ "SPN" SG_ 2147548822 EngTurbo4WastegateDrive 1191;
BA_ "SigType" SG_ 2147548822 EngTurbo3WastegateDrive "RANGE";
BA_ "SPN" SG_ 2147548822 EngTurbo3WastegateDrive 1190;
BA_ "SigType" SG_ 2147548822 EngTurbo2WastegateDrive "RANGE";
BA_ "SPN" SG_ 2147548822 EngTurbo2WastegateDrive 1189;
BA_ "SigType" SG_ 2147548822 EngTurbo1WastegateDrive "RANGE";
BA_ "SPN" SG_ 2147548822 EngTurbo1WastegateDrive 1188;
BA_ "SigType" SG_ 2147548780 TachographVehicleSpeed "RANGE";
BA_ "SPN" SG_ 2147548780 TachographVehicleSpeed 1624;
BA_ "SigType" SG_ 2147548780 TachographOutputShaftSpeed "RANGE";
BA_ "SPN" SG_ 2147548780 TachographOutputShaftSpeed 1623;
BA_ "SigType" SG_ 2147548780 DirectionIndicator "DISCRETE";
BA_ "SPN" SG_ 2147548780 DirectionIndicator 1619;
BA_ "SigType" SG_ 2147548780 TachographPerformance "DISCRETE";
BA_ "SPN" SG_ 2147548780 TachographPerformance 1620;
BA_ "SigType" SG_ 2147548780 HandlingInformation "DISCRETE";
BA_ "SPN" SG_ 2147548780 HandlingInformation 1621;
BA_ "SigType" SG_ 2147548780 SystemEvent "DISCRETE";
BA_ "SPN" SG_ 2147548780 SystemEvent 1622;
BA_ "SigType" SG_ 2147548780 DriverCardDriver2 "DISCRETE";
BA_ "SPN" SG_ 2147548780 DriverCardDriver2 1616;
BA_ "SigType" SG_ 2147548780 Driver2TimeRelatedStates "DISCRETE";
BA_ "SPN" SG_ 2147548780 Driver2TimeRelatedStates 1618;
BA_ "SigType" SG_ 2147548780 Overspeed "DISCRETE";
BA_ "SPN" SG_ 2147548780 Overspeed 1614;
BA_ "SigType" SG_ 2147548780 DriverCardDriver1 "DISCRETE";
BA_ "SPN" SG_ 2147548780 DriverCardDriver1 1615;
BA_ "SigType" SG_ 2147548780 Driver1TimeRelatedStates "DISCRETE";
BA_ "SPN" SG_ 2147548780 Driver1TimeRelatedStates 1617;
BA_ "SigType" SG_ 2147548780 DriveRecognize "DISCRETE";
BA_ "SPN" SG_ 2147548780 DriveRecognize 1611;
BA_ "SigType" SG_ 2147548780 Driver2WorkingState "DISCRETE";
BA_ "SPN" SG_ 2147548780 Driver2WorkingState 1613;
BA_ "SigType" SG_ 2147548780 Driver1WorkingState "DISCRETE";
BA_ "SPN" SG_ 2147548780 Driver1WorkingState 1612;
BA_ "SigType" SG_ 2147548627 EngTurbo4CompressorOutletTemp "RANGE";
BA_ "SPN" SG_ 2147548627 EngTurbo4CompressorOutletTemp 2801;
BA_ "SigType" SG_ 2147548627 EngTurbo3CompressorOutletTemp "RANGE";
BA_ "SPN" SG_ 2147548627 EngTurbo3CompressorOutletTemp 2800;
BA_ "SigType" SG_ 2147548627 EngTurbo2CompressorOutletTemp "RANGE";
BA_ "SPN" SG_ 2147548627 EngTurbo2CompressorOutletTemp 2799;
BA_ "SigType" SG_ 2147548627 EngTurbo1CompressorOutletTemp "RANGE";
BA_ "SPN" SG_ 2147548627 EngTurbo1CompressorOutletTemp 2629;
BA_ "SigType" SG_ 2147548823 EngTurbo4TurbineOutletTemp "RANGE";
BA_ "SPN" SG_ 2147548823 EngTurbo4TurbineOutletTemp 1187;
BA_ "SigType" SG_ 2147548823 EngTurbo3TurbineOutletTemp "RANGE";
BA_ "SPN" SG_ 2147548823 EngTurbo3TurbineOutletTemp 1186;
BA_ "SigType" SG_ 2147548823 EngTurbo2TurbineOutletTemp "RANGE";
BA_ "SPN" SG_ 2147548823 EngTurbo2TurbineOutletTemp 1185;
BA_ "SigType" SG_ 2147548823 EngTurbo1TurbineOutletTemp "RANGE";
BA_ "SPN" SG_ 2147548823 EngTurbo1TurbineOutletTemp 1184;
BA_ "SigType" SG_ 2147548824 EngTurbo4TurbineInletTemp "RANGE";
BA_ "SPN" SG_ 2147548824 EngTurbo4TurbineInletTemp 1183;
BA_ "SigType" SG_ 2147548824 EngTurbo3TurbineInletTemp "RANGE";
BA_ "SPN" SG_ 2147548824 EngTurbo3TurbineInletTemp 1182;
BA_ "SigType" SG_ 2147548824 EngTurbo2TurbineInletTemp "RANGE";
BA_ "SPN" SG_ 2147548824 EngTurbo2TurbineInletTemp 1181;
BA_ "SigType" SG_ 2147548824 EngTurbo1TurbineInletTemp "RANGE";
BA_ "SPN" SG_ 2147548824 EngTurbo1TurbineInletTemp 1180;
BA_ "SigType" SG_ 2147548825 EngTurbo4CompressorInletPress "RANGE";
BA_ "SPN" SG_ 2147548825 EngTurbo4CompressorInletPress 1179;
BA_ "SigType" SG_ 2147548825 EngTurbo3CompressorInletPress "RANGE";
BA_ "SPN" SG_ 2147548825 EngTurbo3CompressorInletPress 1178;
BA_ "SigType" SG_ 2147548825 EngTurbo2CompressorInletPress "RANGE";
BA_ "SPN" SG_ 2147548825 EngTurbo2CompressorInletPress 1177;
BA_ "SigType" SG_ 2147548825 EngTurbo1CompressorInletPress "RANGE";
BA_ "SPN" SG_ 2147548825 EngTurbo1CompressorInletPress 1176;
BA_ "SigType" SG_ 2147548826 EngTurbo4CompressorInletTemp "RANGE";
BA_ "SPN" SG_ 2147548826 EngTurbo4CompressorInletTemp 1175;
BA_ "SigType" SG_ 2147548826 EngTurbo3CompressorInletTemp "RANGE";
BA_ "SPN" SG_ 2147548826 EngTurbo3CompressorInletTemp 1174;
BA_ "SigType" SG_ 2147548826 EngTurbo2CompressorInletTemp "RANGE";
BA_ "SPN" SG_ 2147548826 EngTurbo2CompressorInletTemp 1173;
BA_ "SigType" SG_ 2147548826 EngTurbo1CompressorInletTemp "RANGE";
BA_ "SPN" SG_ 2147548826 EngTurbo1CompressorInletTemp 1172;
BA_ "SigType" SG_ 2147548827 EngTurbo4Speed "RANGE";
BA_ "SPN" SG_ 2147548827 EngTurbo4Speed 1171;
BA_ "SigType" SG_ 2147548827 EngTurbo3Speed "RANGE";
BA_ "SPN" SG_ 2147548827 EngTurbo3Speed 1170;
BA_ "SigType" SG_ 2147548827 EngTurbo2Speed "RANGE";
BA_ "SPN" SG_ 2147548827 EngTurbo2Speed 1169;
BA_ "SigType" SG_ 2147548827 EngTurboLubeOilPress2 "RANGE";
BA_ "SPN" SG_ 2147548827 EngTurboLubeOilPress2 1168;
BA_ "SigType" SG_ 2147548747 TransTorqueLimit "RANGE";
BA_ "SPN" SG_ 2147548747 TransTorqueLimit 1845;
BA_ "SigType" SG_ 2147548898 TransGearRatio "RANGE";
BA_ "SPN" SG_ 2147548898 TransGearRatio 581;
BA_ "SigType" SG_ 2147548898 NumberOfForwardGearRatios "RANGE";
BA_ "SPN" SG_ 2147548898 NumberOfForwardGearRatios 957;
BA_ "SigType" SG_ 2147548898 NumberOfReverseGearRatios "RANGE";
BA_ "SPN" SG_ 2147548898 NumberOfReverseGearRatios 958;
BA_ "SigType" SG_ 2147483904 TrnsShftSlctorDisplayModeSwitch "DISCRETE";
BA_ "SPN" SG_ 2147483904 TrnsShftSlctorDisplayModeSwitch 2985;
BA_ "SigType" SG_ 2147483904 TransMode4 "DISCRETE";
BA_ "SPN" SG_ 2147483904 TransMode4 1855;
BA_ "SigType" SG_ 2147483904 TransMode3 "DISCRETE";
BA_ "SPN" SG_ 2147483904 TransMode3 1854;
BA_ "SigType" SG_ 2147483904 TransMode2 "DISCRETE";
BA_ "SPN" SG_ 2147483904 TransMode2 1853;
BA_ "SigType" SG_ 2147483904 TransMode1 "DISCRETE";
BA_ "SPN" SG_ 2147483904 TransMode1 1852;
BA_ "SigType" SG_ 2147483904 DisengageDiffLockRqCentralRear "DISCRETE";
BA_ "SPN" SG_ 2147483904 DisengageDiffLockRqCentralRear 691;
BA_ "SigType" SG_ 2147483904 DisengageDiffLockRqCentralFront "DISCRETE";
BA_ "SPN" SG_ 2147483904 DisengageDiffLockRqCentralFront 690;
BA_ "SigType" SG_ 2147483904 DisengageDiffLockRqCentral "DISCRETE";
BA_ "SPN" SG_ 2147483904 DisengageDiffLockRqCentral 689;
BA_ "SigType" SG_ 2147483904 DisengageDiffLockRqRearAxle2 "DISCRETE";
BA_ "SPN" SG_ 2147483904 DisengageDiffLockRqRearAxle2 688;
BA_ "SigType" SG_ 2147483904 DisengageDiffLockRqRearAxle1 "DISCRETE";
BA_ "SPN" SG_ 2147483904 DisengageDiffLockRqRearAxle1 687;
BA_ "SigType" SG_ 2147483904 DisengageDiffLockRqFrontAxle2 "DISCRETE";
BA_ "SPN" SG_ 2147483904 DisengageDiffLockRqFrontAxle2 686;
BA_ "SigType" SG_ 2147483904 DisengageDiffLockRqFrontAxle1 "DISCRETE";
BA_ "SPN" SG_ 2147483904 DisengageDiffLockRqFrontAxle1 685;
BA_ "SigType" SG_ 2147483904 TransRqedGear "RANGE";
BA_ "SPN" SG_ 2147483904 TransRqedGear 525;
BA_ "SigType" SG_ 2147483904 RqedPercentClutchSlip "RANGE";
BA_ "SPN" SG_ 2147483904 RqedPercentClutchSlip 684;
BA_ "SigType" SG_ 2147483904 DisengageDrivelineRq "DISCRETE";
BA_ "SPN" SG_ 2147483904 DisengageDrivelineRq 683;
BA_ "SigType" SG_ 2147483904 TorqueConverterLockupDisableRq "DISCRETE";
BA_ "SPN" SG_ 2147483904 TorqueConverterLockupDisableRq 682;
BA_ "SigType" SG_ 2147483904 TransGearShiftInhibitRq "DISCRETE";
BA_ "SPN" SG_ 2147483904 TransGearShiftInhibitRq 681;
BA_ "SigType" SG_ 2147548893 EngTurboOilLevelSwitch "DISCRETE";
BA_ "SPN" SG_ 2147548893 EngTurboOilLevelSwitch 1665;
BA_ "SigType" SG_ 2147548893 EngTurbo1Speed "RANGE";
BA_ "SPN" SG_ 2147548893 EngTurbo1Speed 103;
BA_ "SigType" SG_ 2147548893 EngTurboLubeOilPress1 "RANGE";
BA_ "SPN" SG_ 2147548893 EngTurboLubeOilPress1 104;
BA_ "SigType" SG_ 2147548749 EngTotalAverageFuelEconomy "RANGE";
BA_ "SPN" SG_ 2147548749 EngTotalAverageFuelEconomy 1835;
BA_ "SigType" SG_ 2147548749 EngTotalAverageFuelRate "RANGE";
BA_ "SPN" SG_ 2147548749 EngTotalAverageFuelRate 1834;
BA_ "SigType" SG_ 2147548642 AirSuspensionSupplyPressRq "RANGE";
BA_ "SPN" SG_ 2147548642 AirSuspensionSupplyPressRq 2608;
BA_ "SigType" SG_ 2147548642 AuxEquipmentSupplyPressRq "RANGE";
BA_ "SPN" SG_ 2147548642 AuxEquipmentSupplyPressRq 2607;
BA_ "SigType" SG_ 2147548642 ServiceBrakeAirPressRqCircuit2 "RANGE";
BA_ "SPN" SG_ 2147548642 ServiceBrakeAirPressRqCircuit2 2606;
BA_ "SigType" SG_ 2147548642 ServiceBrakeAirPressRqCircuit1 "RANGE";
BA_ "SPN" SG_ 2147548642 ServiceBrakeAirPressRqCircuit1 2605;
BA_ "SigType" SG_ 2147548642 ParkingAnd_OrTrailerAirPressRq "RANGE";
BA_ "SPN" SG_ 2147548642 ParkingAnd_OrTrailerAirPressRq 2604;
BA_ "SigType" SG_ 2147548642 PneumaticSupplyPressRq "RANGE";
BA_ "SPN" SG_ 2147548642 PneumaticSupplyPressRq 2603;
BA_ "SigType" SG_ 2147548815 EngExtlShutdownAirSupplyPress "RANGE";
BA_ "SPN" SG_ 2147548815 EngExtlShutdownAirSupplyPress 1320;
BA_ "SigType" SG_ 2147548890 NmbrOfSftwrIdentificationFields "RANGE";
BA_ "SPN" SG_ 2147548890 NmbrOfSftwrIdentificationFields 965;
BA_ "SigType" SG_ 2147548900 EngOverspeedTest "DISCRETE";
BA_ "SPN" SG_ 2147548900 EngOverspeedTest 2812;
BA_ "SigType" SG_ 2147548900 EngAirShutoffCmdStatus "DISCRETE";
BA_ "SPN" SG_ 2147548900 EngAirShutoffCmdStatus 2813;
BA_ "SigType" SG_ 2147548900 EngAlarmOutputCmdStatus "DISCRETE";
BA_ "SPN" SG_ 2147548900 EngAlarmOutputCmdStatus 2814;
BA_ "SigType" SG_ 2147548900 EngAlarmAcknowledge "DISCRETE";
BA_ "SPN" SG_ 2147548900 EngAlarmAcknowledge 2815;
BA_ "SigType" SG_ 2147548900 EngProtectionSystemConfig "DISCRETE";
BA_ "SPN" SG_ 2147548900 EngProtectionSystemConfig 1111;
BA_ "SigType" SG_ 2147548900 EngProtectionSystemTimerState "DISCRETE";
BA_ "SPN" SG_ 2147548900 EngProtectionSystemTimerState 1107;
BA_ "SigType" SG_ 2147548900 EngPrtectionSystemTimerOverride "DISCRETE";
BA_ "SPN" SG_ 2147548900 EngPrtectionSystemTimerOverride 1108;
BA_ "SigType" SG_ 2147548900 EngPrtctnSystmApprchingShutdown "DISCRETE";
BA_ "SPN" SG_ 2147548900 EngPrtctnSystmApprchingShutdown 1109;
BA_ "SigType" SG_ 2147548900 EngPrtctionSystemHasShutdownEng "DISCRETE";
BA_ "SPN" SG_ 2147548900 EngPrtctionSystemHasShutdownEng 1110;
BA_ "SigType" SG_ 2147548900 EngWaitToStartLamp "DISCRETE";
BA_ "SPN" SG_ 2147548900 EngWaitToStartLamp 1081;
BA_ "SigType" SG_ 2147548900 RefrigerantHighPressSwitch "DISCRETE";
BA_ "SPN" SG_ 2147548900 RefrigerantHighPressSwitch 605;
BA_ "SigType" SG_ 2147548900 RefrigerantLowPressSwitch "DISCRETE";
BA_ "SPN" SG_ 2147548900 RefrigerantLowPressSwitch 875;
BA_ "SigType" SG_ 2147548900 A_CHighPressFanSwitch "DISCRETE";
BA_ "SPN" SG_ 2147548900 A_CHighPressFanSwitch 985;
BA_ "SigType" SG_ 2147548900 EngIdleShutdownTimerFunction "DISCRETE";
BA_ "SPN" SG_ 2147548900 EngIdleShutdownTimerFunction 591;
BA_ "SigType" SG_ 2147548900 EngIdleShutdownTimerState "DISCRETE";
BA_ "SPN" SG_ 2147548900 EngIdleShutdownTimerState 590;
BA_ "SigType" SG_ 2147548900 EngIdleShutdownTimerOverride "DISCRETE";
BA_ "SPN" SG_ 2147548900 EngIdleShutdownTimerOverride 592;
BA_ "SigType" SG_ 2147548900 EngIdleShutdownDriverAlertMode "DISCRETE";
BA_ "SPN" SG_ 2147548900 EngIdleShutdownDriverAlertMode 594;
BA_ "SigType" SG_ 2147548900 EngIdleShutdownHasShutdownEng "DISCRETE";
BA_ "SPN" SG_ 2147548900 EngIdleShutdownHasShutdownEng 593;
BA_ "SigType" SG_ 2147548864 ServiceComponentIdentificationB "RANGE";
BA_ "SPN" SG_ 2147548864 ServiceComponentIdentificationB 912;
BA_ "SigType" SG_ 2147548864 ServiceComponentIdentificationA "RANGE";
BA_ "SPN" SG_ 2147548864 ServiceComponentIdentificationA 911;
BA_ "SigType" SG_ 2147548864 SrvceDelay_OperationalTimeBased "RANGE";
BA_ "SPN" SG_ 2147548864 SrvceDelay_OperationalTimeBased 916;
BA_ "SigType" SG_ 2147548864 ServiceDelay_CalendarTimeBased "RANGE";
BA_ "SPN" SG_ 2147548864 ServiceDelay_CalendarTimeBased 915;
BA_ "SigType" SG_ 2147548864 ServiceDistance "RANGE";
BA_ "SPN" SG_ 2147548864 ServiceDistance 914;
BA_ "SigType" SG_ 2147548864 ServiceComponentIdentification "RANGE";
BA_ "SPN" SG_ 2147548864 ServiceComponentIdentification 911;
BA_ "SigType" SG_ 2147548814 TimeSinceLastService "RANGE";
BA_ "SPN" SG_ 2147548814 TimeSinceLastService 1350;
BA_ "SigType" SG_ 2147548814 ServiceComponentIdentification "RANGE";
BA_ "SPN" SG_ 2147548814 ServiceComponentIdentification 911;
BA_ "SigType" SG_ 2147548755 MaxContinuousRetarderTorque "RANGE";
BA_ "SPN" SG_ 2147548755 MaxContinuousRetarderTorque 1782;
BA_ "SigType" SG_ 2147548755 MinContinuousRetarderSpeed "RANGE";
BA_ "SPN" SG_ 2147548755 MinContinuousRetarderSpeed 1781;
BA_ "SigType" SG_ 2147548755 MaxContinuousRetarderSpeed "RANGE";
BA_ "SPN" SG_ 2147548755 MaxContinuousRetarderSpeed 1780;
BA_ "SigType" SG_ 2147548755 HghLmtThrshhldFrMnCntnsTrqFrmRtr "RANGE";
BA_ "SPN" SG_ 2147548755 HghLmtThrshhldFrMnCntnsTrqFrmRtr 1779;
BA_ "SigType" SG_ 2147548755 LwLmtThrshhldFrMxTrqFrmRetarder "RANGE";
BA_ "SPN" SG_ 2147548755 LwLmtThrshhldFrMxTrqFrmRetarder 1778;
BA_ "SigType" SG_ 2147548755 HghLmtThrshhldFrMnCntnsRPMFrmRtr "RANGE";
BA_ "SPN" SG_ 2147548755 HghLmtThrshhldFrMnCntnsRPMFrmRtr 1777;
BA_ "SigType" SG_ 2147548755 LwLmtThrshhldFrMxRPMFrmRetarder "RANGE";
BA_ "SPN" SG_ 2147548755 LwLmtThrshhldFrMxRPMFrmRetarder 1776;
BA_ "SigType" SG_ 2147548755 MinContinuousRetarderTorque "RANGE";
BA_ "SPN" SG_ 2147548755 MinContinuousRetarderTorque 1783;
BA_ "SigType" SG_ 2147548923 HydRetarderOilTemp "RANGE";
BA_ "SPN" SG_ 2147548923 HydRetarderOilTemp 120;
BA_ "SigType" SG_ 2147548923 HydRetarderPress "RANGE";
BA_ "SPN" SG_ 2147548923 HydRetarderPress 119;
BA_ "SigType" SG_ 2147540480 EngBuildHoursReset "DISCRETE";
BA_ "SPN" SG_ 2147540480 EngBuildHoursReset 1211;
BA_ "SigType" SG_ 2147540480 ServiceComponentIdentification "RANGE";
BA_ "SPN" SG_ 2147540480 ServiceComponentIdentification 911;
BA_ "SigType" SG_ 2147540480 TripGroup2Proprietary "DISCRETE";
BA_ "SPN" SG_ 2147540480 TripGroup2Proprietary 989;
BA_ "SigType" SG_ 2147540480 TripGroup1 "DISCRETE";
BA_ "SPN" SG_ 2147540480 TripGroup1 988;
BA_ "SigType" SG_ 2147548897 PercentTorqueAtPeakTorquePoint5 "RANGE";
BA_ "SPN" SG_ 2147548897 PercentTorqueAtPeakTorquePoint5 555;
BA_ "SigType" SG_ 2147548897 ReferenceRetarderTorque "RANGE";
BA_ "SPN" SG_ 2147548897 ReferenceRetarderTorque 556;
BA_ "SigType" SG_ 2147548897 RetarderSpeedAtPeakTorquePoint5 "RANGE";
BA_ "SPN" SG_ 2147548897 RetarderSpeedAtPeakTorquePoint5 547;
BA_ "SigType" SG_ 2147548897 PercentTorqueAtPoint4 "RANGE";
BA_ "SPN" SG_ 2147548897 PercentTorqueAtPoint4 554;
BA_ "SigType" SG_ 2147548897 RetarderSpeedAtPoint4 "RANGE";
BA_ "SPN" SG_ 2147548897 RetarderSpeedAtPoint4 550;
BA_ "SigType" SG_ 2147548897 PercentTorqueAtPoint3 "RANGE";
BA_ "SPN" SG_ 2147548897 PercentTorqueAtPoint3 553;
BA_ "SigType" SG_ 2147548897 RetarderSpeedAtPoint3 "RANGE";
BA_ "SPN" SG_ 2147548897 RetarderSpeedAtPoint3 549;
BA_ "SigType" SG_ 2147548897 PercentTorqueAtMaxSpeedPoint2 "RANGE";
BA_ "SPN" SG_ 2147548897 PercentTorqueAtMaxSpeedPoint2 552;
BA_ "SigType" SG_ 2147548897 MaxRetarderSpeedPoint2 "RANGE";
BA_ "SPN" SG_ 2147548897 MaxRetarderSpeedPoint2 548;
BA_ "SigType" SG_ 2147548897 PercentTorqueAtIdlePoint1 "RANGE";
BA_ "SPN" SG_ 2147548897 PercentTorqueAtIdlePoint1 551;
BA_ "SigType" SG_ 2147548897 RetarderSpeedAtIdlePoint1 "RANGE";
BA_ "SPN" SG_ 2147548897 RetarderSpeedAtIdlePoint1 546;
BA_ "SigType" SG_ 2147548897 RetarderCtrlMethod "RANGE";
BA_ "SPN" SG_ 2147548897 RetarderCtrlMethod 557;
BA_ "SigType" SG_ 2147548897 RetarderLocation "DISCRETE";
BA_ "SPN" SG_ 2147548897 RetarderLocation 902;
BA_ "SigType" SG_ 2147548897 RetarderType "DISCRETE";
BA_ "SPN" SG_ 2147548897 RetarderType 901;
BA_ "SigType" SG_ 2147548821 EngOperationTimeSinceRebuild "RANGE";
BA_ "SPN" SG_ 2147548821 EngOperationTimeSinceRebuild 1193;
BA_ "SigType" SG_ 2147548912 OperatorPTOMemorySelectSwitch "DISCRETE";
BA_ "SPN" SG_ 2147548912 OperatorPTOMemorySelectSwitch 2897;
BA_ "SigType" SG_ 2147548912 EngPTOAccelerateSwitch "DISCRETE";
BA_ "SPN" SG_ 2147548912 EngPTOAccelerateSwitch 981;
BA_ "SigType" SG_ 2147548912 EngPTOResumeSwitch "DISCRETE";
BA_ "SPN" SG_ 2147548912 EngPTOResumeSwitch 982;
BA_ "SigType" SG_ 2147548912 EngPTOCoast_DecelerateSwitch "DISCRETE";
BA_ "SPN" SG_ 2147548912 EngPTOCoast_DecelerateSwitch 983;
BA_ "SigType" SG_ 2147548912 EngPTOSetSwitch "DISCRETE";
BA_ "SPN" SG_ 2147548912 EngPTOSetSwitch 984;
BA_ "SigType" SG_ 2147548912 EngRmtPTOVriableSpeedCtrlSwitch "DISCRETE";
BA_ "SPN" SG_ 2147548912 EngRmtPTOVriableSpeedCtrlSwitch 978;
BA_ "SigType" SG_ 2147548912 EngRmtPTOPrprgrmmdSpdCtrlSwitch "DISCRETE";
BA_ "SPN" SG_ 2147548912 EngRmtPTOPrprgrmmdSpdCtrlSwitch 979;
BA_ "SigType" SG_ 2147548912 EngPTOEnableSwitch "DISCRETE";
BA_ "SPN" SG_ 2147548912 EngPTOEnableSwitch 980;
BA_ "SigType" SG_ 2147548912 PowerTakeoffSetSpeed "RANGE";
BA_ "SPN" SG_ 2147548912 PowerTakeoffSetSpeed 187;
BA_ "SigType" SG_ 2147548912 PowerTakeoffSpeed "RANGE";
BA_ "SPN" SG_ 2147548912 PowerTakeoffSpeed 186;
BA_ "SigType" SG_ 2147548912 PowerTakeoffOilTemp "RANGE";
BA_ "SPN" SG_ 2147548912 PowerTakeoffOilTemp 90;
BA_ "SigType" SG_ 2147548621 RearWasherFunction "DISCRETE";
BA_ "SPN" SG_ 2147548621 RearWasherFunction 2868;
BA_ "SigType" SG_ 2147548621 FrontOperatorWasherSwitch "DISCRETE";
BA_ "SPN" SG_ 2147548621 FrontOperatorWasherSwitch 2866;
BA_ "SigType" SG_ 2147548621 FrontNonoperatorWasherSwitch "DISCRETE";
BA_ "SPN" SG_ 2147548621 FrontNonoperatorWasherSwitch 2867;
BA_ "SigType" SG_ 2147548621 RearWiperDelayCtrl "RANGE";
BA_ "SPN" SG_ 2147548621 RearWiperDelayCtrl 2871;
BA_ "SigType" SG_ 2147548621 FrontNonoperatorWiperDelayCtrl "RANGE";
BA_ "SPN" SG_ 2147548621 FrontNonoperatorWiperDelayCtrl 2870;
BA_ "SigType" SG_ 2147548621 FrontOperatorWiperDelayCtrl "RANGE";
BA_ "SPN" SG_ 2147548621 FrontOperatorWiperDelayCtrl 2869;
BA_ "SigType" SG_ 2147548621 RearWiperSwitch "DISCRETE";
BA_ "SPN" SG_ 2147548621 RearWiperSwitch 2865;
BA_ "SigType" SG_ 2147548621 FrontOperatorWiperSwitch "DISCRETE";
BA_ "SPN" SG_ 2147548621 FrontOperatorWiperSwitch 2863;
BA_ "SigType" SG_ 2147548621 FrontNonoperatorWiperSwitch "DISCRETE";
BA_ "SPN" SG_ 2147548621 FrontNonoperatorWiperSwitch 2864;
BA_ "SigType" SG_ 2147548619 EngAltDroopAuxInputSelect "DISCRETE";
BA_ "SPN" SG_ 2147548619 EngAltDroopAuxInputSelect 2885;
BA_ "SigType" SG_ 2147548619 EngAltDroopRemoteAccelSelect "DISCRETE";
BA_ "SPN" SG_ 2147548619 EngAltDroopRemoteAccelSelect 2886;
BA_ "SigType" SG_ 2147548619 EngAltDroopAccel2Select "DISCRETE";
BA_ "SPN" SG_ 2147548619 EngAltDroopAccel2Select 2879;
BA_ "SigType" SG_ 2147548619 EngAltDroopAccel1Select "DISCRETE";
BA_ "SPN" SG_ 2147548619 EngAltDroopAccel1Select 2881;
BA_ "SigType" SG_ 2147548619 EngAltRatingSelect "RANGE";
BA_ "SPN" SG_ 2147548619 EngAltRatingSelect 2882;
BA_ "SigType" SG_ 2147548619 EngAltLowIdleSwitch "DISCRETE";
BA_ "SPN" SG_ 2147548619 EngAltLowIdleSwitch 2883;
BA_ "SigType" SG_ 2147548619 EngSynchronizationSwitch "DISCRETE";
BA_ "SPN" SG_ 2147548619 EngSynchronizationSwitch 1377;
BA_ "SigType" SG_ 2147548619 EngAuxGovernorSwitch "DISCRETE";
BA_ "SPN" SG_ 2147548619 EngAuxGovernorSwitch 2884;
BA_ "SigType" SG_ 2147548615 EngAltDroopAuxInputSelectState "DISCRETE";
BA_ "SPN" SG_ 2147548615 EngAltDroopAuxInputSelectState 2895;
BA_ "SigType" SG_ 2147548615 EngAltDrpRemoteAccelSelectState "DISCRETE";
BA_ "SPN" SG_ 2147548615 EngAltDrpRemoteAccelSelectState 2894;
BA_ "SigType" SG_ 2147548615 EngAltDroopAccel2SelectState "DISCRETE";
BA_ "SPN" SG_ 2147548615 EngAltDroopAccel2SelectState 2893;
BA_ "SigType" SG_ 2147548615 EngAltDroopAccel1SelectState "DISCRETE";
BA_ "SPN" SG_ 2147548615 EngAltDroopAccel1SelectState 2889;
BA_ "SigType" SG_ 2147548615 EngAltRatingSelectState "RANGE";
BA_ "SPN" SG_ 2147548615 EngAltRatingSelectState 2888;
BA_ "SigType" SG_ 2147548615 EngAltLowIdleSelectState "DISCRETE";
BA_ "SPN" SG_ 2147548615 EngAltLowIdleSelectState 2891;
BA_ "SigType" SG_ 2147548615 EngMultiUnitSyncState "DISCRETE";
BA_ "SPN" SG_ 2147548615 EngMultiUnitSyncState 2890;
BA_ "SigType" SG_ 2147548615 EngAuxGovernorState "DISCRETE";
BA_ "SPN" SG_ 2147548615 EngAuxGovernorState 2896;
BA_ "SigType" SG_ 2147548620 OprtrsDesiredDelayedLampOffTime "RANGE";
BA_ "SPN" SG_ 2147548620 OprtrsDesiredDelayedLampOffTime 2877;
BA_ "SigType" SG_ 2147548620 OperatorsDesiredBacklight "RANGE";
BA_ "SPN" SG_ 2147548620 OperatorsDesiredBacklight 2878;
BA_ "SigType" SG_ 2147548620 HighLowBeamSwitch "DISCRETE";
BA_ "SPN" SG_ 2147548620 HighLowBeamSwitch 2874;
BA_ "SigType" SG_ 2147548620 HazardLightSwitch "DISCRETE";
BA_ "SPN" SG_ 2147548620 HazardLightSwitch 2875;
BA_ "SigType" SG_ 2147548620 TurnSignalSwitch "DISCRETE";
BA_ "SPN" SG_ 2147548620 TurnSignalSwitch 2876;
BA_ "SigType" SG_ 2147548620 MainLightSwitch "DISCRETE";
BA_ "SPN" SG_ 2147548620 MainLightSwitch 2872;
BA_ "SigType" SG_ 2147548620 WorkLightSwitch "DISCRETE";
BA_ "SPN" SG_ 2147548620 WorkLightSwitch 2873;
BA_ "SigType" SG_ 2147548645 AppliedVehicleSpeedLimit "RANGE";
BA_ "SPN" SG_ 2147548645 AppliedVehicleSpeedLimit 2595;
BA_ "SigType" SG_ 2147548645 MaxVehicleSpeedLimit7 "RANGE";
BA_ "SPN" SG_ 2147548645 MaxVehicleSpeedLimit7 2594;
BA_ "SigType" SG_ 2147548645 MaxVehicleSpeedLimit6 "RANGE";
BA_ "SPN" SG_ 2147548645 MaxVehicleSpeedLimit6 2593;
BA_ "SigType" SG_ 2147548645 MaxVehicleSpeedLimit5 "RANGE";
BA_ "SPN" SG_ 2147548645 MaxVehicleSpeedLimit5 2592;
BA_ "SigType" SG_ 2147548645 MaxVehicleSpeedLimit4 "RANGE";
BA_ "SPN" SG_ 2147548645 MaxVehicleSpeedLimit4 2591;
BA_ "SigType" SG_ 2147548645 MaxVehicleSpeedLimit3 "RANGE";
BA_ "SPN" SG_ 2147548645 MaxVehicleSpeedLimit3 2590;
BA_ "SigType" SG_ 2147548645 MaxVehicleSpeedLimit2 "RANGE";
BA_ "SPN" SG_ 2147548645 MaxVehicleSpeedLimit2 2589;
BA_ "SigType" SG_ 2147548645 MaxVehicleSpeedLimit1 "RANGE";
BA_ "SPN" SG_ 2147548645 MaxVehicleSpeedLimit1 2588;
BA_ "SigType" SG_ 2147548748 OprtrsBlckOutIntensitySelection "RANGE";
BA_ "SPN" SG_ 2147548748 OprtrsBlckOutIntensitySelection 1844;
BA_ "SigType" SG_ 2147548748 BlackOutWorkLampSelect "DISCRETE";
BA_ "SPN" SG_ 2147548748 BlackOutWorkLampSelect 1842;
BA_ "SigType" SG_ 2147548748 NightVisionIlluminatorSelect "DISCRETE";
BA_ "SPN" SG_ 2147548748 NightVisionIlluminatorSelect 1843;
BA_ "SigType" SG_ 2147548748 BlackOutBrake_StopLampSelect "DISCRETE";
BA_ "SPN" SG_ 2147548748 BlackOutBrake_StopLampSelect 1841;
BA_ "SigType" SG_ 2147548748 ConvoyDrivingLampSelect "DISCRETE";
BA_ "SPN" SG_ 2147548748 ConvoyDrivingLampSelect 1837;
BA_ "SigType" SG_ 2147548748 ConvoyLampSelect "DISCRETE";
BA_ "SPN" SG_ 2147548748 ConvoyLampSelect 1838;
BA_ "SigType" SG_ 2147548748 FrontBlackOutMarkerLampSelect "DISCRETE";
BA_ "SPN" SG_ 2147548748 FrontBlackOutMarkerLampSelect 1839;
BA_ "SigType" SG_ 2147548748 RearBlackOutMarkerSelect "DISCRETE";
BA_ "SPN" SG_ 2147548748 RearBlackOutMarkerSelect 1840;
VAL_ 2147537920 SecurityEntityType 3 "DataIsCertificate" 2 "DataIsSessionKey" 1 "DataIsLongKey" 0 "DataIsLongSeed" ;
VAL_ 2147548736 ImplementRearWorkLight 3 "NotAvailable" 2 "FaultDetected" 1 "Activate" 0 "Deactivate" ;
VAL_ 2147548736 ImplementLeftForwardWorkLight 3 "NotAvailable" 2 "FaultDetected" 1 "Activate" 0 "Deactivate" ;
VAL_ 2147548736 ImplementRightForwardWorkLight 3 "NotAvailable" 2 "FaultDetected" 1 "Activate" 0 "Deactivate" ;
VAL_ 2147548736 ImplementLeftFacingWorkLight 3 "NotAvailable" 2 "FaultDetected" 1 "Activate" 0 "Deactivate" ;
VAL_ 2147548736 ImplementRightFacingWorkLight 3 "NotAvailable" 2 "FaultDetected" 1 "Activate" 0 "Deactivate" ;
VAL_ 2147548736 ImplementOEMOption1Light 3 "NotAvailable" 2 "FaultDetected" 1 "Activate" 0 "Deactivate" ;
VAL_ 2147548736 ImplementOEMOption2Light 3 "NotAvailable" 2 "FaultDetected" 1 "Activate" 0 "Deactivate" ;
VAL_ 2147548736 TrctrFrontHighMountedWorkLights 3 "NotAvailable" 2 "FaultDetected" 1 "Activate" 0 "Deactivate" ;
VAL_ 2147548736 TrctorFrontLowMountedWorkLights 3 "NotAvailable" 2 "FaultDetected" 1 "Activate" 0 "Deactivate" ;
VAL_ 2147548736 TrctorSideHighMountedWorkLights 3 "NotAvailable" 2 "FaultDetected" 1 "Activated" 0 "Deactivated" ;
VAL_ 2147548736 TractorSideLowMountedWorkLights 3 "NotAvailable" 2 "FaultDetected" 1 "Activated" 0 "Deactivated" ;
VAL_ 2147548736 TrctorRearHighMountedWorkLights 3 "NotAvailable" 2 "FaultDetected" 1 "Activated" 0 "Deactivated" ;
VAL_ 2147548736 TractorRearLowMountedWorkLights 3 "NotAvailable" 2 "FaultDetected" 1 "Activate" 0 "Deactivate" ;
VAL_ 2147548736 TrctrUndersideMountedWorkLights 3 "NotAvailable" 2 "FaultDetected" 1 "Activate" 0 "Deactivate" ;
VAL_ 2147548736 RearFogLights 3 "NotAvailable" 2 "FaultDetected" 1 "Activated" 0 "Deactivated" ;
VAL_ 2147548736 TractorMarkerLight 3 "NotAvailable" 2 "FaultDetected" 1 "Activated" 0 "Deactivated" ;
VAL_ 2147548736 ImplementMarkerLight 3 "NotAvailable" 2 "FaultDetected" 1 "Activated" 0 "Deactivated" ;
VAL_ 2147548736 TractorClearanceLight 3 "NotAvailable" 2 "FaultDetected" 1 "Activated" 0 "Deactivated" ;
VAL_ 2147548736 ImplementClearanceLight 3 "NotAvailable" 2 "FaultDetected" 1 "Activated" 0 "Deactivated" ;
VAL_ 2147548736 LeftStopLight 3 "NotAvailable" 2 "FaultDetected" 1 "Activated" 0 "Deactivated" ;
VAL_ 2147548736 RightStopLight 3 "NotAvailable" 2 "FaultDetected" 1 "Activated" 0 "Deactivated" ;
VAL_ 2147548736 CenterStopLight 3 "NotAvailable" 2 "FaultDetected" 1 "Activated" 0 "Deactivated" ;
VAL_ 2147548736 BackUpLightAndAlarmHorn 3 "NotAvailable" 2 "FaultDetected" 1 "Activated" 0 "Deactivated" ;
VAL_ 2147548736 LeftTurnSignalLights 3 "NotAvailable" 2 "FaultDetected" 1 "Activated" 0 "Deactivated" ;
VAL_ 2147548736 RightTurnSignalLights 3 "NotAvailable" 2 "FaultDetected" 1 "Activated" 0 "Deactivated" ;
VAL_ 2147548736 RotatingBeaconLight 3 "NotAvailable" 2 "FaultDetected" 1 "Activated" 0 "Deactivated" ;
VAL_ 2147548736 TractorFrontFogLights 3 "NotAvailable" 2 "FaultDetected" 1 "Activated" 0 "Deactivated" ;
VAL_ 2147548736 HighBeamHeadLightData 3 "NotAvailable" 2 "FaultDetected" 1 "Activate" 0 "Deactivate" ;
VAL_ 2147548736 LowBeamHeadLightData 3 "NotAvailable" 2 "FaultDetected" 1 "Activate" 0 "Deactivate" ;
VAL_ 2147548736 AltBeamHeadLightData 3 "NotAvailable" 2 "FaultDetected" 1 "Activate" 0 "Deactivate" ;
VAL_ 2147548736 RunningLight 3 "NotAvailable" 2 "FaultDetected" 1 "Activate" 0 "Deactivate" ;
VAL_ 2147548737 ImplementRearWorkLightCmd 3 "DonTCare" 2 "Reserved" 1 "Activate" 0 "Deactivate" ;
VAL_ 2147548737 ImplmentLeftForwardWorkLightCmd 3 "DonTCare" 2 "Reserved" 1 "Activate" 0 "Deactivate" ;
VAL_ 2147548737 ImplmntRightForwardWorkLightCmd 3 "DonTCare" 2 "Reserved" 1 "Activate" 0 "Deactivate" ;
VAL_ 2147548737 LightingDataRqCmd 3 "DonTCare" 2 "Reserved" 1 "Activate" 0 "Deactivate" ;
VAL_ 2147548737 ImplementLeftFacingWorkLightCmd 3 "DonTCare" 2 "Reserved" 1 "Activate" 0 "Deactivate" ;
VAL_ 2147548737 ImplmentRightFacingWorkLightCmd 3 "DonTCare" 2 "Reserved" 1 "Activate" 0 "Deactivate" ;
VAL_ 2147548737 ImplementOEMOption1LightCmd 3 "DonTCare" 2 "Reserved" 1 "Activate" 0 "Deactivate" ;
VAL_ 2147548737 ImplementOEMOption2LightCmd 3 "DonTCare" 2 "Reserved" 1 "Activate" 0 "Deactivate" ;
VAL_ 2147548737 TrctrFrntHghMuntedWorkLightsCmd 3 "DonTCare" 2 "Reserved" 1 "Activate" 0 "Deactivate" ;
VAL_ 2147548737 TrctrFrntLwMountedWorkLightsCmd 3 "DonTCare" 2 "Reserved" 1 "Activate" 0 "Deactivate" ;
VAL_ 2147548737 TrctrSdHighMountedWorkLightsCmd 3 "DonTCare" 2 "Reserved" 1 "Activate" 0 "Deactivate" ;
VAL_ 2147548737 TrctrSdeLowMountedWorkLightsCmd 3 "DonTCare" 2 "Reserved" 1 "Activate" 0 "Deactivate" ;
VAL_ 2147548737 TrctrRrHighMountedWorkLightsCmd 3 "DonTCare" 2 "Reserved" 1 "Activate" 0 "Deactivate" ;
VAL_ 2147548737 TrctrRarLowMountedWorkLightsCmd 3 "DonTCare" 2 "Reserved" 1 "Activate" 0 "Deactivate" ;
VAL_ 2147548737 TrctrUndrsdMountedWorkLightsCmd 3 "DonTCare" 2 "Reserved" 1 "Activate" 0 "Deactivate" ;
VAL_ 2147548737 RearFogLightCmd 3 "DonTCare" 2 "Reserved" 1 "Activate" 0 "Deactivate" ;
VAL_ 2147548737 TractorMarkerLightCmd 3 "DonTCare" 2 "Reserved" 1 "Activate" 0 "Deactivate" ;
VAL_ 2147548737 ImplementMarkerLightCmd 3 "DonTCare" 2 "Reserved" 1 "Activate" 0 "Deactivate" ;
VAL_ 2147548737 TractorClearanceLightCmd 3 "DonTCare" 2 "Reserved" 1 "Activate" 0 "Deactivate" ;
VAL_ 2147548737 ImplementClearanceLightCmd 3 "DonTCare" 2 "Reserved" 1 "Activate" 0 "Deactivate" ;
VAL_ 2147548737 LeftStopLightCmd 3 "DonTCare" 2 "Reserved" 1 "Activate" 0 "Deactivate" ;
VAL_ 2147548737 RightStopLightCmd 3 "DonTCare" 2 "Reserved" 1 "Activate" 0 "Deactivate" ;
VAL_ 2147548737 CenterStopLightCmd 3 "DonTCare" 2 "Reserved" 1 "Activate" 0 "Deactivate" ;
VAL_ 2147548737 BackUpLightAndAlarmHornCmd 3 "DonTCare" 2 "Reserved" 1 "Activate" 0 "Deactivate" ;
VAL_ 2147548737 LeftTurnSignalLightsCmd 3 "DonTCare" 2 "Reserved" 1 "Activate" 0 "Deactivate" ;
VAL_ 2147548737 RightTurnSignalLightsCmd 3 "DonTCare" 2 "Reserved" 1 "Activate" 0 "Deactivate" ;
VAL_ 2147548737 RotatingBeaconLightCmd 3 "DonTCare" 2 "Reserved" 1 "Activate" 0 "Deactivate" ;
VAL_ 2147548737 TractorFrontFogLightsCmd 3 "DonTCare" 2 "Reserved" 1 "Activate" 0 "Deactivate" ;
VAL_ 2147548737 HighBeamHeadLightCmd 3 "DonTCare" 2 "Reserved" 1 "Activate" 0 "Deactivate" ;
VAL_ 2147548737 LowBeamHeadLightCmd 3 "DonTCare" 2 "Reserved" 1 "Activate" 0 "Deactivate" ;
VAL_ 2147548737 AltBeamHeadLightCmd 3 "DonTCare" 2 "Reserved" 1 "Activate" 0 "Deactivate" ;
VAL_ 2147548737 RunningLightCmd 3 "DonTCare" 2 "Reserved" 1 "Activate" 0 "Deactivate" ;
VAL_ 2147548786 BladeCtrlMode 2 "InactiveAutomaticMode" 1 "AutomaticMode" 0 "ManualMode" ;
VAL_ 2147548616 EngOprtrPrmryIntrmdtSpdSlctStte 15 "NotAvailable" 14 "SAEReserved" 1 "thr1101CtrlSttIsISCSttng1Thru13" 0 "CtrlSttIsISCFnctnltyIsNtRqdEngO" ;
VAL_ 2147548618 EngOprtrPrmryIntrmdtSpeedSelect 15 "NotAvailable" 14 "ErrorCondition" 1 "thr1101IndctsThtISCSttng1Thr13I" 0 "IndctsThtISCFnctnltyIsNtRqdEngO" ;
VAL_ 2147548781 CabHeatingZone 3 "NotAvailable" 2 "Reserved" 1 "CabHeatingZoneOn" 0 "CabHeatingZoneOff" ;
VAL_ 2147548781 EngHeatingZone 3 "NotAvailable" 2 "Reserved" 1 "EngHeatingZoneOn" 0 "EngHeatingZoneOff" ;
VAL_ 2147548781 CabVentilation 3 "NotAvailable" 2 "Reserved" 1 "CabIsVentilated" 0 "CabNotVentilated" ;
VAL_ 2147548781 AuxilaryHeaterWaterPumpStatus 3 "NotAvailable" 2 "Reserved" 1 "WaterPumpIsRunning" 0 "WaterPumpIsNotRunning" ;
VAL_ 2147548781 AuxHeaterMode 15 "NotAvailable" 14 "Error" 4 "1101NotDefined" 3 "NormalMode" 2 "EconomyMode" 1 "OffDTADRPrErpnRgltnsFrTrnsprtOf" 0 "HeaterNotActive" ;
VAL_ 2147545096 FireApparatusPumpEngagement 3 "NotAvailableNotInstalled" 2 "Error" 1 "PumpEngaged" 0 "PumpNotEngaged" ;
VAL_ 2147545096 EngHydPressGovernorSwitch 3 "NotAvailable" 2 "ErrorIndicator" 1 "PressModeActive" 0 "PressModeInactive" ;
VAL_ 2147545096 EngHydPrssGovernorModeIndicator 3 "NotAvailable" 2 "ErrorIndicator" 1 "Enabled" 0 "Disabled" ;
VAL_ 2147548646 HydBrakeFluidLevelSwitch 3 "NotAvailable" 2 "ErrorIndicator" 1 "FluidLevelIsSufficient" 0 "FluidLevelIsNotSufficient" ;
VAL_ 2147548646 HydBrakeSystemAudibleWarningCmd 3 "DontCare" 2 "Reserved" 1 "AudibleWarningOn" 0 "AudibleWarningOff" ;
VAL_ 2147548646 HydBrkePressSupplyStateCircuit2 3 "NotAvailable" 2 "ErrorIndicator" 1 "SupplyIsReliable" 0 "SupplyIsNotReliable" ;
VAL_ 2147548646 HydBrkePressSupplyStateCircuit1 3 "NotAvailable" 2 "ErrorIndicator" 1 "SupplyIsReliable" 0 "SupplyIsNotReliable" ;
VAL_ 2147548646 HydBrkPressWarningStateCircuit2 3 "NotAvailable" 2 "ErrorIndicator" 1 "PressLevelBelowWarningLevel" 0 "PressLevelSufficient" ;
VAL_ 2147548646 HydBrkPressWarningStateCircuit1 3 "NotAvailable" 2 "ErrorIndicator" 1 "PressLevelBelowWarningLevel" 0 "PressLevelSufficient" ;
VAL_ 2147544320 ControlByte 6 "MFDB_CreateEntry" 5 "MFDB_SetMode" 4 "MFDB_Clear" 3 "MFDB_Delete" 2 "MFDB_Add" 1 "MFDB_Response" 0 "MFDB_Request" ;
VAL_ 2147544320 FilterMode 1 "PassSpecificPGNs" 0 "BlockSpecificPGNs" ;
VAL_ 2147484672 XBRCtrlMode 3 "NotDefined" 2 "AcclrtnCtrlWthMxMdExctXBRAcclrt" 1 "AcclrtnCtrlWthAddtnMdAddXBRAccl" 0 "OvrrdDsbldDsblAnyExstngCtrlCmdd" ;
VAL_ 2147484672 XBRPriority 3 "LwPrrtyUsdInOvrrdDsbldXBRCtrlMd" 2 "MdmPrrtyUsdFrACCSystmsThsMdDsNt" 1 "HighPriorityNotDefined" 0 "HghstPrrtyUsdFrEmrgncySttnsEgFr" ;
VAL_ 2147484672 XBREBIMode 3 "NotDefined" 2 "EndranceBrakeIntegrationAllowed" 1 "OnlyEnduranceBrakesAllowed" 0 "NEndrnceBrakeIntegrationAllowed" ;
VAL_ 2147548927 WaterInFuelIndicator 1 "Yes" 0 "No" ;
VAL_ 2147548776 WinchOilPressSwitch 3 "NotAvailable" 2 "ErrrSwtchStteCannotBeDetermined" 1 "OKOilPressIsAboveMin" 0 "NOTOKOilPressIsTooLow" ;
VAL_ 2147548776 HydOilFilterRestrictionSwitch 3 "NotAvailable" 2 "Error" 1 "RestrictionExistsOnOilFitler" 0 "NoRestriction" ;
VAL_ 2147545097 SteerWheelAngleSensorType 3 "NotAvailable" 2 "Reserved" 1 "AbsMeasuringPrinciple" 0 "RelativeMeasuringPrinciple" ;
VAL_ 2147548751 YCBrakeCtrlActive 3 "DontCare_TakeNoAction" 2 "Reserved" 1 "YCBrakeCtrlActive" 0 "YCBrakeCtrlPassiveButInstalled" ;
VAL_ 2147548751 YCEngCtrlActive 3 "DontCare_TakeNoAction" 2 "Reserved" 1 "YCEngCtrlActive" 0 "YCEngCtrlPassiveButInstalled" ;
VAL_ 2147548751 ROPBrakeCtrlActive 3 "DontCare_TakeNoAction" 2 "Reserved" 1 "ROPBrakeCtrlActive" 0 "ROPBrakeCtrlPassiveButInstalled" ;
VAL_ 2147548751 ROPEngCtrlActive 3 "DontCare_TakeNoAction" 2 "Reserved" 1 "ROPEngCtrlActive" 0 "ROPEngCtrlPassiveButInstalled" ;
VAL_ 2147548751 VDCBrakeLightRq 3 "DontCare_TakeNoAction" 2 "Reserved" 1 "TurnBrakeLightOn" 0 "TurnBrakeLightNotOn" ;
VAL_ 2147548751 VDCFullyOperational 3 "DontCare_TakeNoAction" 2 "Reserved" 1 "FullyOperational" 0 "NotFullyOperational" ;
VAL_ 2147548751 VDCInformationSignal 3 "DontCare_TakeNoAction" 2 "Reserved" 1 "On" 0 "Off" ;
VAL_ 2147483648 OverrideCtrlModePriority 3 "LowPriority" 2 "MdmPrrtyUsdFrPwrtrnCtrlOprtnsWh" 1 "HighPriority" 0 "HghstPrrtyUsdFrSttnsThtRqrImmdt" ;
VAL_ 2147483648 EngRqedSpeedCtrlConditions 2 "ThsCtrlCndtnHsBnOptmzdTMnmzRpmO" 3 "StbltyOptmzdFrDrvlnEnggdAnd_OrI" 1 "StbltyOptmzdFrDrvlnDsnggdAndNnl" 0 "ThsSpdGvrnrGnSlctnIsAdjstdTPrvd" ;
VAL_ 2147483648 EngOverrideCtrlMode 3 "Spd_TrqLmtCtrlLmtSpdAnd_OrTrqBs" 2 "TrqCtrlCntrlTrqTInclddDsrdTrqVl" 1 "SpdCtrlGvrnSpdTInclddDsrdSpdVle" 0 "OvrrdDsbldDsblAnyExstngCtrlCmdd" ;
VAL_ 2147548608 TransitRunStatus 3 "NotAvailable" 2 "ErrorCondition" 1 "On" 0 "Off" ;
VAL_ 2147548608 VehicleUseStatus 3 "NotAvailable" 2 "ErrorCondition" 1 "UnauthorizedUse" 0 "NormalUse" ;
VAL_ 2147548608 SilentAlarmStatus 3 "NotAvailable" 2 "ErrorCondition" 1 "On" 0 "Off" ;
VAL_ 2147548608 TypeOfPassengerCount 1 "BoardingPassenger" 0 "AbsPassengerCount" ;
VAL_ 2147548602 FareboxAlarmIdentifier 97 "1111111AgencyDefined" 26 "1100000ReservedToBeAssigned" 25 "MaintenanceAccessOutOfService" 24 "MntnncAccssInSrvcCnsdrdAnAlrmCn" 23 "PaperCurrencyJamCleared" 22 "PaperCurrencyJam" 21 "Pass_TransferJamCleared" 20 "Pass_TransferJam" 19 "FareboxResetToAutomaticMode" 18 "FareboxSetInManualBypass" 17 "CoinDejamOperated" 16 "Card_PassBoxFull" 15 "Card_PassBoxLessThan75Full" 14 "Card_PassBox75Full" 13 "CurrencyBoxFull" 12 "CurrencyBoxLessThan75Full" 11 "CurrencyBox75Full" 10 "CoinboxFull" 9 "Coinbox75Full" 8 "InsufficientFareAccepted" 7 "CshbxOpndInSrvcCnsdrdAnAlrmCndt" 6 "CashboxDoorTimeout" 5 "CashboxRestored" 4 "CashboxRemoved" 3 "ProbeCompleted" 2 "ProbeStarted" 1 "VoltageRestored" 0 "VoltageDropout" ;
VAL_ 2147548602 FareboxEmergencyStatus 3 "NotAvailable" 2 "ErrorCondition" 1 "EmergencyCondition" 0 "NonemergencyCondition" ;
VAL_ 2147548603 TransferType 6 "11111AgencyDefined" 5 "Out" 4 "In" 3 "West" 2 "East" 1 "South" 0 "North" ;
VAL_ 2147548603 TypeOfService 2 "111AgencyDefined" 1 "ExpressService" 0 "LocalService" ;
VAL_ 2147548603 PaymentDetails 11 "1111AgencyDefined" 6 "1010ReservedForAssignment" 5 "Card" 4 "Pass" 3 "Ticket" 2 "Token" 1 "Cash" 0 "NotAnUpgrade" ;
VAL_ 2147548603 TypeOfFare 11 "1111AgencyDefined" 7 "1010ReservedForAssignment" 6 "PassB" 5 "PassA" 4 "TicketB" 3 "TicketA" 2 "TokenB" 1 "TokenA" 0 "Cash_NoDetail" ;
VAL_ 2147548603 TransactionType 12 "1111AgencyDefined" 8 "1011ReservedForAssignment" 7 "Free" 6 "Transfer" 5 "Permit" 4 "Card" 3 "Pass" 2 "Ticket" 1 "Token" 0 "Cash" ;
VAL_ 2147548604 DriversFareboxSecurityCode 1 "65535SecurityCode" ;
VAL_ 2147548604 FarePresets 16 "to11111111ReservedForAssignment" 0 "to00001111AgencyDefined" ;
VAL_ 2147548604 TripDirection 6 "1111AgencyDefined" 5 "Out" 4 "In" 3 "West" 2 "East" 1 "South" 0 "North" ;
VAL_ 2147548604 TripStatus 6 "LayoverEnd" 5 "LayoverStart" 2 "TripEnd" 1 "TripStart" 7 "Undefined" ;
VAL_ 2147548604 FareboxServiceStatus 3 "NotAvailable" 2 "ErrorCondition" 1 "FareboxInService" 0 "FareboxOutOfService" ;
VAL_ 2147548605 StrobeActivationCtrlStatus 3 "NotAvailable" 2 "ErrorCondition" 1 "ActivateStrobe" 0 "DeactiveStrobe" ;
VAL_ 2147548605 TransitDoorEnable 3 "NotAvailable" 2 "ErrorCondition" 1 "TrnstDrSttsWllOvrrdStrbActvtion" 0 "IgnoreTransitDoorStatus" ;
VAL_ 2147548605 PriorityOfRespSentByEmitter 15 "NotAvailable" 14 "ErrorCondition" 12 "to1101Reserved" 11 "PrrtyStByHardwareToHighPriority" 10 "PrrtyStByHrdwareToProbePriority" 9 "PrrtySetByHardwareToLowPriority" 4 "to1000Reserved" 3 "HighPriority" 2 "ProbePriority" 1 "LowPriority" 0 "Reserved" ;
VAL_ 2147548605 IntersectionPreemptionRq_Resp 3 "NotAvailable" 2 "ErrorCondition" 1 "MessageIsARespFromEmitter" 0 "MessageIsARqDirectedToEmitter" ;
VAL_ 2147548605 TransitRouteIDUsage 3 "NotAvailable" 2 "ErrorCondition" 1 "TrnstRtIDUsedForInterleavedData" 0 "TrnstRtIDNtUsdFrInterleavedData" ;
VAL_ 2147548605 RangeCodeEnable 3 "NotAvailable" 2 "ErrorCondition" 1 "RangeCodeUsedForInterleavedData" 0 "RngCdeNotUsedForInterleavedData" ;
VAL_ 2147548792 PCUSupplySolenoidStatus 1 "On" 0 "Off" ;
VAL_ 2147548792 PCUCtrlSolenoidStatus 1 "On" 0 "Off" ;
VAL_ 2147548792 PCUDeflateSolenoidStatus 1 "On" 0 "Off" ;
VAL_ 2147548792 TirePressSupplySwitchStatus 1 "On" 0 "Off" ;
VAL_ 2147548792 PCUSteerSolenoidStatus 1 "On" 0 "Off" ;
VAL_ 2147548792 PCUDriveSolenoidStatus 1 "On" 0 "Off" ;
VAL_ 2147548792 DriveChannelMode 15 "NotAvailable" 14 "ErrorCondition" 7 "1101Reserved" 6 "PressCheck" 5 "DfltWtSystmWllDfltWhnCndtnsAllw" 4 "InfltWtSystmWllInfltWhnCndtnsAl" 3 "Confirm" 2 "Deflate" 1 "Inflate" 0 "Maintain" ;
VAL_ 2147548792 Trailer_TagChannelMode 15 "NotAvailable" 14 "ErrorCondition" 7 "1101Reserved" 6 "PressCheck" 5 "DfltWtSystmWllDfltWhnCndtnsAllw" 4 "InfltWtSystmWllInfltWhnCndtnsAl" 3 "Confirm" 2 "Deflate" 1 "Inflate" 0 "Maintain" ;
VAL_ 2147548792 SteerChannelMode 15 "NotAvailable" 14 "ErrorCondition" 7 "1101Reserved" 6 "PressCheck" 5 "DfltWtSystmWllDfltWhnCndtnsAllw" 4 "InfltWtSystmWllInfltWhnCndtnsAl" 3 "Confirm" 2 "Deflate" 1 "Inflate" 0 "Maintain" ;
VAL_ 2147548792 PCUTrailerTagPushSolenoidStatus 1 "On" 0 "Off" ;
VAL_ 2147548916 TirePressThresholdDetection 7 "NotAvailable" 6 "ErrorIndicator" 5 "NotDefined" 4 "ExtrmUndrPrssTrPrssrIsAtALvlWhr" 3 "UndrPrssTrPrssrIsLwrThnThPrssrD" 2 "NWrnngPrssTrPrssrIsWthnThThrshl" 1 "OvrPrssTrPrssrIsHghrThnThPrssrD" 0 "ExtrmOvrPrssTrPrssrIsAtALvlWhrT" ;
VAL_ 2147548916 CTIWheelEndElectricalFault 3 "NotSupported" 2 "Error" 1 "NotDefined" 0 "Ok" ;
VAL_ 2147548916 CTITireStatus 3 "NotSupported" 2 "Error" 1 "TireLeakDetected" 0 "Ok" ;
VAL_ 2147548916 CTIWheelSensorStatus 3 "NotSupported" 2 "NotDefined" 1 "On" 0 "Off_IsolatedFromCTIPressCtrl" ;
VAL_ 2147548758 CatalystTankLevel 4 "Full" 0 "Empty" ;
VAL_ 2147548920 TransOilLevelMeasurementStatus 15 "NotAvailable" 14 "Error" 13 "ConditionsNotValidOther" 12 "NotDefined" 8 "CndtionsNotValidEngSpeedTooHigh" 7 "CnditionsNotValidEngSpeedTooLow" 6 "CndtionsNotValidVehicleNotLevel" 5 "CndtnsNtVldVhclMvngOtptShftSpdT" 4 "CndtnsNtVldTrnsFluidTempTooHigh" 3 "CndtnsNtVldTransFluidTempTooLow" 2 "ConditionsNotValidTransInGear" 1 "CndtnsNtVldSttlngTmrStllCntngDw" 0 "CndtnsVldFrTrnsOlLvlMeasurement" ;
VAL_ 2147548920 TransOilLevelCountdownTimer 15 "NotAvailable" 14 "Error" 13 "ThirteenMinutes" 12 "TwelveMinutes" 11 "ElevenMinutes" 10 "TenMinutes" 9 "NineMinutes" 8 "EightMinutes" 7 "SevenMinutes" 6 "SixMinutes" 5 "FiveMinutes" 4 "FourMinutes" 3 "ThreeMinutes" 2 "TwoMinutes" 1 "OneMinute" 0 "lessThan1Minute" ;
VAL_ 2147548780 DirectionIndicator 1 "Reverse" 0 "Forward" ;
VAL_ 2147548780 TachographPerformance 1 "PerformanceAnalysis" 0 "NormalPerformance" ;
VAL_ 2147548780 HandlingInformation 1 "HandlingInformation" 0 "NoHandlingInformation" ;
VAL_ 2147548780 SystemEvent 1 "TachographEvent" 0 "NoTachographEvent" ;
VAL_ 2147548780 DriverCardDriver2 1 "DriverCardPresent" 0 "DriverCardNotPresent" ;
VAL_ 2147548780 Driver2TimeRelatedStates 15 "NotAvailable" 14 "Error" 13 "Other" 7 "1100Reserved" 6 "Limit616HReached" 5 "Limit515MinBefore16H" 4 "Limit49HReached" 3 "Limit315MinBefore9H" 2 "Limit24HReached" 1 "Limit115MinBefore4H" 0 "Normal_NoLimitsReached" ;
VAL_ 2147548780 Overspeed 1 "Overspeed" 0 "NoOverspeed" ;
VAL_ 2147548780 DriverCardDriver1 1 "DriverCardPresent" 0 "DriverCardNotPresent" ;
VAL_ 2147548780 Driver1TimeRelatedStates 15 "NotAvailable" 14 "Error" 13 "Other" 7 "1100Reserved" 6 "Limit616HReached" 5 "Limit515MinBefore16H" 4 "Limit49HReached" 3 "Limit315MinBefore9H" 2 "Limit24HReached" 1 "Limit115MinBefore4H" 0 "Normal_NoLimitsReached" ;
VAL_ 2147548780 DriveRecognize 1 "VehicleMotionDetected" 0 "VehicleMotionNotDetected" ;
VAL_ 2147548780 Driver2WorkingState 7 "NotAvailable" 6 "Error" 4 "101Reserved" 3 "DriveBehindWheel" 2 "WrkLdngUnldingWorkingInAnOffice" 1 "DriverAvailableShortBreak" 0 "RestSleeping" ;
VAL_ 2147548780 Driver1WorkingState 7 "NotAvailable" 6 "Error" 4 "101Reserved" 3 "DriveBehindWheel" 2 "WrkLdngUnldingWorkingInAnOffice" 1 "DriverAvailableShortBreak" 0 "RestSleeping" ;
VAL_ 2147483904 TrnsShftSlctorDisplayModeSwitch 3 "NotAvailable" 2 "Error" 1 "On" 0 "Off" ;
VAL_ 2147483904 TransMode4 3 "TakeNoAction" 2 "Reserved" 1 "Enable" 0 "Disable" ;
VAL_ 2147483904 TransMode3 3 "TakeNoAction" 2 "Reserved" 1 "Enable" 0 "Disable" ;
VAL_ 2147483904 TransMode2 3 "TakeNoAction" 2 "Reserved" 1 "Enable" 0 "Disable" ;
VAL_ 2147483904 TransMode1 3 "TakeNoAction" 2 "Reserved" 1 "Enable" 0 "Disable" ;
VAL_ 2147483904 DisengageDiffLockRqCentralRear 3 "TakeNoAction" 1 "DisengageDiffLock" 0 "EngageDiffLock" ;
VAL_ 2147483904 DisengageDiffLockRqCentralFront 3 "TakeNoAction" 1 "DisengageDiffLock" 0 "EngageDiffLock" ;
VAL_ 2147483904 DisengageDiffLockRqCentral 3 "TakeNoAction" 1 "DisengageDiffLock" 0 "EngageDiffLock" ;
VAL_ 2147483904 DisengageDiffLockRqRearAxle2 3 "TakeNoAction" 1 "DisengageDiffLock" 0 "EngageDiffLock" ;
VAL_ 2147483904 DisengageDiffLockRqRearAxle1 3 "TakeNoAction" 1 "DisengageDiffLock" 0 "EngageDiffLock" ;
VAL_ 2147483904 DisengageDiffLockRqFrontAxle2 3 "TakeNoAction" 1 "DisengageDiffLock" 0 "EngageDiffLock" ;
VAL_ 2147483904 DisengageDiffLockRqFrontAxle1 3 "TakeNoAction" 1 "DisengageDiffLock" 0 "EngageDiffLock" ;
VAL_ 2147483904 TransRqedGear 61 "Reserved" 222 "NeutralSelectorPos" 223 "ReverseSelectorPos" 224 "PsUnknownAnd_OrNoButtonsPressed" 225 "PrssOfMmntryBttnTRslctCrrentPos" 226 "BtwnRvrsAndPrkShiftSelectorPoss" 227 "BtwnNtrlAndRvrsShftSelectorPoss" 228 "BtwnDrvAndNtrlShiftSelectorPoss" 229 "BtwnD1AndDriveShiftSelectorPoss" 230 "BetweenD2AndD1ShiftSelectorPoss" 231 "BetweenD3AndD2ShiftSelectorPoss" 232 "BetweenD4AndD3ShiftSelectorPoss" 233 "BetweenD5AndD4ShiftSelectorPoss" 234 "BetweenD6AndD5ShiftSelectorPoss" 235 "BetweenD7AndD6ShiftSelectorPoss" 236 "BtwnTwoForwardShiftSelectorPoss" 237 "BtwnTwoReverseShiftSelectorPoss" 238 "BetweenTwoShiftSelectorPoss" 239 "D77thFrwrdSlctrPsRfrncdFrmDrive" 240 "D66thFrwrdSlctrPsRfrncdFrmDrive" 241 "D55thFrwrdSlctrPsRfrncdFrmDrive" 242 "D44thFrwrdSlctrPsRfrncdFrmDrive" 243 "D33rdFrwrdSlctrPsRfrncdFrmDrive" 244 "D22ndFrwrdSlctrPsRfrncdFrmDrive" 245 "D11stFrwrdSlctrPsRfrncdFrmDrive" 246 "Downshift2GearsFromCurrentPos" 247 "Downshift1GearFromCurrentPos" 248 "Upshift2GearsFromCurrentPos" 249 "Upshift1GearFromCurrentPos" 250 "ForwardLowPos" 251 "ParkPos" 252 "ForwardDrivePos" 253 "HoldCurrentGear" ;
VAL_ 2147483904 DisengageDrivelineRq 3 "TakeNoAction" 1 "DisengageDriveline" 0 "AllowDrivelineEngagement" ;
VAL_ 2147483904 TorqueConverterLockupDisableRq 3 "TakeNoAction" 1 "DisableTorqueConvertorLockup" 0 "AllowTorqueConvertorLockup" ;
VAL_ 2147483904 TransGearShiftInhibitRq 3 "TakeNoAction" 1 "GearShiftsAreInhibited" 0 "GearShiftsAreAllowed" ;
VAL_ 2147548900 EngOverspeedTest 3 "NotAvailable" 2 "Reserved" 1 "EngOverspeedTestActive" 0 "EngOverspeedTestNotActive" ;
VAL_ 2147548900 EngAirShutoffCmdStatus 0 "ArShtffDsbldNtAttmptngTShtffEng" 3 "NotAvailable" 2 "Reserved" 1 "ArShtffEnbldAttmptngTShtffEngAr" ;
VAL_ 2147548900 EngAlarmOutputCmdStatus 3 "NotAvailable" 2 "Reserved" 1 "EngAlarmOutputCmdActive" 0 "EngAlarmOutputCmdNotActive" ;
VAL_ 2147548900 EngAlarmAcknowledge 3 "NotAvailable" 2 "Error" 1 "EngAlarmAcknowledgeActive" 0 "EngAlarmAcknowledgeNotActive" ;
VAL_ 2147548900 EngProtectionSystemConfig 1 "EnabledInCalib" 0 "DisabledInCalib" ;
VAL_ 2147548900 EngProtectionSystemTimerState 1 "Active" 0 "Inactive" ;
VAL_ 2147548900 EngPrtectionSystemTimerOverride 1 "Active" 0 "Inactive" ;
VAL_ 2147548900 EngPrtctnSystmApprchingShutdown 1 "Approaching" 0 "NotApproaching" ;
VAL_ 2147548900 EngPrtctionSystemHasShutdownEng 0 "No" ;
VAL_ 2147548900 EngWaitToStartLamp 1 "On" 0 "Off" ;
VAL_ 2147548900 RefrigerantHighPressSwitch 1 "PrssTHghCmprssrCltchMyBDsngaged" 0 "PressNormal" ;
VAL_ 2147548900 RefrigerantLowPressSwitch 1 "PrssTLwCmprssrCltchMyBDsengaged" 0 "PressNormal" ;
VAL_ 2147548900 A_CHighPressFanSwitch 1 "PressHighFanMayBeEngaged" 0 "PressNormal" ;
VAL_ 2147548900 EngIdleShutdownTimerFunction 1 "EnabledInCalib" 0 "DisabledInCalib" ;
VAL_ 2147548900 EngIdleShutdownTimerState 1 "Active" 0 "Inactive" ;
VAL_ 2147548900 EngIdleShutdownTimerOverride 1 "Active" 0 "Inactive" ;
VAL_ 2147548900 EngIdleShutdownDriverAlertMode 1 "Active" 0 "Inactive" ;
VAL_ 2147548900 EngIdleShutdownHasShutdownEng 1 "Yes" 0 "No" ;
VAL_ 2147540480 EngBuildHoursReset 3 "TakeNoAction" 1 "Reset" 0 "DoNotReset" ;
VAL_ 2147540480 TripGroup2Proprietary 3 "NotApplicable" 1 "Reset" 0 "TakeNoAction" ;
VAL_ 2147540480 TripGroup1 3 "NotApplicable" 1 "Reset" 0 "TakeNoAction" ;
VAL_ 2147548912 OperatorPTOMemorySelectSwitch 3 "notAvailable" 2 "error" 1 "PTOSetSpeedMemory2Selected" 0 "PTOSetSpeedMemory1Selected" ;
VAL_ 2147548912 EngPTOAccelerateSwitch 1 "On" 0 "Off" ;
VAL_ 2147548912 EngPTOResumeSwitch 1 "On" 0 "Off" ;
VAL_ 2147548912 EngPTOCoast_DecelerateSwitch 1 "On" 0 "Off" ;
VAL_ 2147548912 EngPTOSetSwitch 1 "On" 0 "Off" ;
VAL_ 2147548912 EngRmtPTOVriableSpeedCtrlSwitch 2 "Error" 1 "On" 0 "Off" ;
VAL_ 2147548912 EngRmtPTOPrprgrmmdSpdCtrlSwitch 1 "On" 0 "Off" ;
VAL_ 2147548912 EngPTOEnableSwitch 1 "On" 0 "Off" ;
VAL_ 2147548621 RearWasherFunction 1 "Low" 0 "Off" ;
VAL_ 2147548621 FrontOperatorWasherSwitch 1 "Low" 0 "Off" ;
VAL_ 2147548621 FrontNonoperatorWasherSwitch 1 "Low" 0 "Off" ;
VAL_ 2147548621 RearWiperSwitch 3 "Reserved" 1 "Low" 0 "Off" ;
VAL_ 2147548621 FrontOperatorWiperSwitch 3 "Reserved" 1 "Low" 0 "Off" ;
VAL_ 2147548621 FrontNonoperatorWiperSwitch 3 "Reserved" 1 "Low" 0 "Off" ;
VAL_ 2147548619 EngAltDroopAuxInputSelect 15 "NotAvailable" 14 "ErrorCondition" 1 "thr1101OnOfAltDrpSttng1Thrgh13I" 0 "NormalDroopSettingIsSelected" ;
VAL_ 2147548619 EngAltDroopRemoteAccelSelect 15 "NotAvailable" 14 "ErrorCondition" 1 "thr1101OnOfAltDrpSttng1Thrgh13I" 0 "NormalDroopSettingIsSelected" ;
VAL_ 2147548619 EngAltDroopAccel2Select 15 "NotAvailable" 14 "ErrorCondition" 1 "thr1101OnOfAltDrpSttng1Thrgh13I" 0 "NormalDroopSettingIsSelected" ;
VAL_ 2147548619 EngAltDroopAccel1Select 14 "ErrorCondition" 1 "thr1101OnOfAltDrpSttng1Thrgh13I" 0 "NormalDroopSettingIsSelected" ;
VAL_ 2147548619 EngAltRatingSelect 1 "IndctsThtAltPwrFling1IsSelected" 0 "IndctsThtMxPwrFuelingIsSelected" ;
VAL_ 2147548619 EngAltLowIdleSwitch 3 "NotAvailableUnused" 2 "Error" 1 "AltLowIdlePointIsSelected" 0 "DefaultLowIdlePointIsSelected" ;
VAL_ 2147548619 EngSynchronizationSwitch 3 "NotAvailableUnused" 2 "Error" 1 "FunctionalityIsEnabled" 0 "FunctionalityIsDisabled" ;
VAL_ 2147548619 EngAuxGovernorSwitch 2 "ErrorCondition" 1 "AuxGovernorIsEnabled" 0 "AuxGovernorIsDisabled" 3 "NotAvailable" ;
VAL_ 2147548615 EngAltDroopAuxInputSelectState 14 "SAEReserved" 1 "thr1101CtrlSttIsOnOfAltDrpSttng" 0 "CtrlStateIsNormalDroopSetting" ;
VAL_ 2147548615 EngAltDrpRemoteAccelSelectState 15 "NotAvailable" 14 "SAEReserved" 1 "thr1101CtrlSttIsOnOfAltDrpSttng" 0 "CtrlStateIsNormalDroopSetting" ;
VAL_ 2147548615 EngAltDroopAccel2SelectState 14 "SAEReserved" 1 "thr1101CtrlsSttIsOnOfAltDrpSttn" 0 "CtrlsStateIsNormalDroopSetting" ;
VAL_ 2147548615 EngAltDroopAccel1SelectState 15 "NotAvailable" 14 "SAEReserved" 1 "thr1101CtrlSttIsOnOfAltDrpSttng" 0 "CtrlStateIsNormalDroopSetting" ;
VAL_ 2147548615 EngAltRatingSelectState 1 "CtrlStateIsAltPowerFueling1" 0 "CtrlStateIsMaxPowerFueling" ;
VAL_ 2147548615 EngAltLowIdleSelectState 3 "NotAvailable" 2 "SAEReserved" 1 "AltIdleState" 0 "NormalIdleState" ;
VAL_ 2147548615 EngMultiUnitSyncState 3 "NotAvailable" 2 "SAEReserved" 1 "CtrlStateIsFunctionalityEnabled" 0 "CtrlStteIsFunctionalityDisabled" ;
VAL_ 2147548615 EngAuxGovernorState 3 "NotAvailable" 2 "SAEReserved" 1 "CtrlStateIsAuxGovernorEnabled" 0 "CtrlStateIsAuxGovernorDisabled" ;
VAL_ 2147548620 HighLowBeamSwitch 1 "HighBeamSelected" 0 "LowBeamSelected" ;
VAL_ 2147548620 HazardLightSwitch 1 "HazardLampsToBeFlashing" 0 "HazardLampsToBeOff" ;
VAL_ 2147548620 TurnSignalSwitch 3 "Reserved" 1 "LeftTurnToBeFlashing" 0 "NoTurnBeingSignaled" ;
VAL_ 2147548620 MainLightSwitch 3 "Reserved" 1 "PrkOnPsByWhchThOprtrSlctsThtThP" 0 "OffPsByWhchThOprtrSlctsThtNnOfT" ;
VAL_ 2147548620 WorkLightSwitch 3 "Reserved" 1 "WrkLghtCmbntn1OnPsByWhchThOprtr" 0 "OffPsByWhchThOprtrSlctsThtNnOfT" ;
VAL_ 2147548748 BlackOutWorkLampSelect 3 "NotSupported" 2 "Reserved" 1 "On" 0 "Off" ;
VAL_ 2147548748 NightVisionIlluminatorSelect 3 "NotSupported" 2 "Reserved" 1 "On" 0 "Off" ;
VAL_ 2147548748 BlackOutBrake_StopLampSelect 3 "NotSupported" 2 "Reserved" 1 "On" 0 "Off" ;
VAL_ 2147548748 ConvoyDrivingLampSelect 3 "NotSupported" 2 "Reserved" 1 "On" 0 "Off" ;
VAL_ 2147548748 ConvoyLampSelect 3 "NotSupported" 2 "Reserved" 1 "On" 0 "Off" ;
VAL_ 2147548748 FrontBlackOutMarkerLampSelect 3 "NotSupported" 2 "Reserved" 1 "On" 0 "Off" ;
VAL_ 2147548748 RearBlackOutMarkerSelect 3 "NotSupported" 2 "Reserved" 1 "On" 0 "Off" ;
